VERSION ""

NS_ :

BS_:

BU_: CVC_B BCM_FL BCM_FR DUMMY_ECU DKCU BCM_R

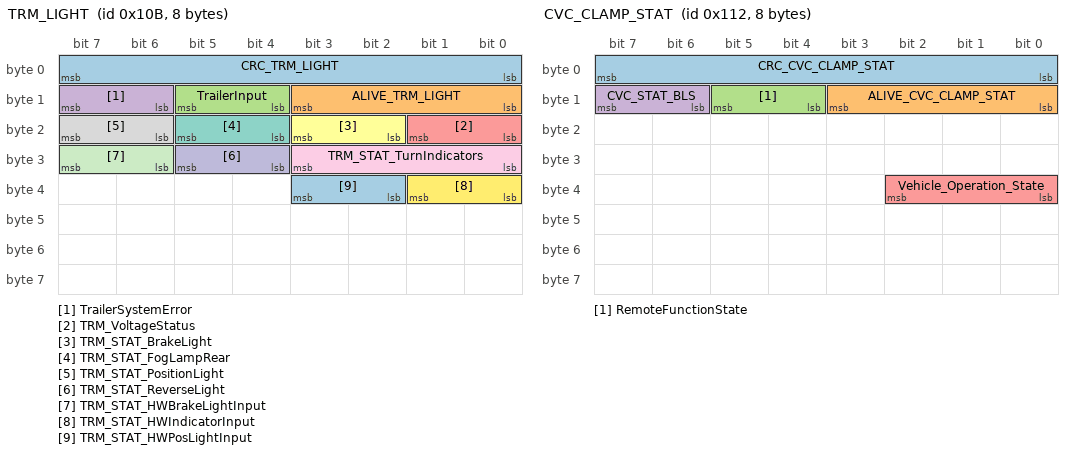
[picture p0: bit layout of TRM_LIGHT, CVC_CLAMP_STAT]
BO_ 267 TRM_LIGHT: 8 CVC_B
 SG_ CRC_TRM_LIGHT : 7|8@0+ (1,0) [0|255] ""  BCM_FL,BCM_FR,BCM_R
 SG_ ALIVE_TRM_LIGHT : 11|4@0+ (1,0) [0|15] ""  BCM_FL,BCM_FR,BCM_R
 SG_ TrailerInput : 13|2@0+ (1,0) [0|3] ""  BCM_FL,BCM_FR,BCM_R
 SG_ TrailerSystemError : 15|2@0+ (1,0) [0|3] ""  BCM_FL,BCM_FR,BCM_R
 SG_ TRM_VoltageStatus : 17|2@0+ (1,0) [0|3] ""  BCM_FL,BCM_FR,BCM_R
 SG_ TRM_STAT_BrakeLight : 19|2@0+ (1,0) [0|3] ""  BCM_FL,BCM_FR,BCM_R
 SG_ TRM_STAT_FogLampRear : 21|2@0+ (1,0) [0|3] ""  BCM_FL,BCM_FR,BCM_R
 SG_ TRM_STAT_PositionLight : 23|2@0+ (1,0) [0|3] ""  BCM_FL,BCM_FR,BCM_R
 SG_ TRM_STAT_TurnIndicators : 27|4@0+ (1,0) [0|15] ""  BCM_FL,BCM_FR,BCM_R
 SG_ TRM_STAT_ReverseLight : 29|2@0+ (1,0) [0|3] ""  BCM_FL,BCM_FR,BCM_R
 SG_ TRM_STAT_HWBrakeLightInput : 31|2@0+ (1,0) [0|3] ""  BCM_FL,BCM_FR,BCM_R
 SG_ TRM_STAT_HWIndicatorInput : 33|2@0+ (1,0) [0|3] ""  BCM_FL,BCM_FR,BCM_R
 SG_ TRM_STAT_HWPosLightInput : 35|2@0+ (1,0) [0|3] ""  BCM_FL,BCM_FR,BCM_R

BO_ 274 CVC_CLAMP_STAT: 8 CVC_B
 SG_ CRC_CVC_CLAMP_STAT : 7|8@0+ (1,0) [0|255] ""  BCM_FL,BCM_FR,DKCU,BCM_R
 SG_ ALIVE_CVC_CLAMP_STAT : 11|4@0+ (1,0) [0|15] ""  BCM_FL,BCM_FR,DKCU,BCM_R
 SG_ RemoteFunctionState : 13|2@0+ (1,0) [0|3] ""  BCM_FL,BCM_FR,DKCU,BCM_R
 SG_ CVC_STAT_BLS : 15|2@0+ (1,0) [0|3] ""  BCM_FL,BCM_FR,DKCU,BCM_R
 SG_ Vehicle_Operation_State : 34|3@0+ (1,0) [0|7] ""  BCM_FL,BCM_FR,DKCU,BCM_R

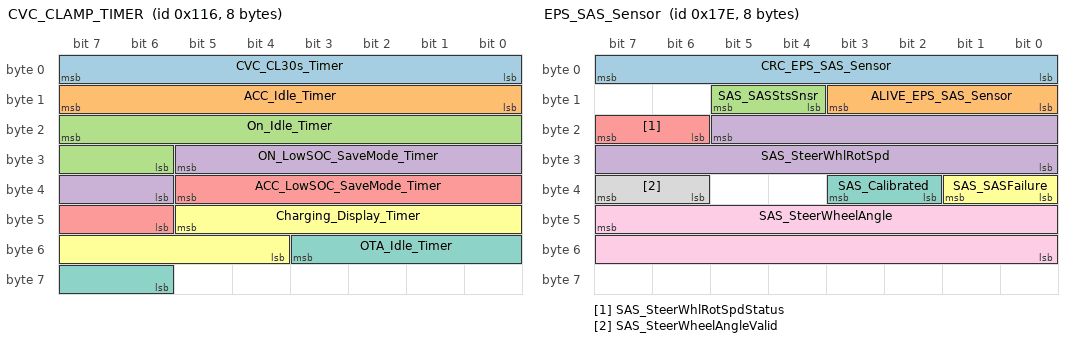
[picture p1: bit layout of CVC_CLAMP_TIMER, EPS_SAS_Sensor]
BO_ 278 CVC_CLAMP_TIMER: 8 CVC_B
 SG_ CVC_CL30s_Timer : 7|8@0+ (1,0) [0|255] "s"  BCM_FL,BCM_FR,BCM_R
 SG_ ACC_Idle_Timer : 15|8@0+ (1,0) [0|255] "s"  BCM_FL,BCM_FR,BCM_R
 SG_ On_Idle_Timer : 23|10@0+ (1,0) [0|1023] "s"  BCM_FL,BCM_FR,BCM_R
 SG_ ON_LowSOC_SaveMode_Timer : 29|8@0+ (1,0) [0|255] "s"  BCM_FL,BCM_FR,BCM_R
 SG_ ACC_LowSOC_SaveMode_Timer : 37|8@0+ (1,0) [0|255] "s"  BCM_FL,BCM_FR,BCM_R
 SG_ Charging_Display_Timer : 45|10@0+ (1,0) [0|1023] "s"  BCM_FL,BCM_FR,BCM_R
 SG_ OTA_Idle_Timer : 51|6@0+ (1,0) [0|63] "minute"  BCM_FL,BCM_FR,BCM_R

BO_ 284 FOTAClampCtrl: 8 CVC_B
 SG_ TBOX_FOTA_STAT_TerminalReq : 7|3@0+ (1,0) [0|7] ""  BCM_FL,BCM_FR,BCM_R

BO_ 307 SRR_RR_BSD_RCTA_DOW: 32 CVC_B
 SG_ CRC_SRR_RR_BSD_RCTA_DOW : 7|8@0+ (1,0) [0|255] ""  BCM_FL,BCM_FR,BCM_R
 SG_ ALIVE_SRR_RR_BSD_RCTA_DOW : 11|4@0+ (1,0) [0|15] ""  BCM_FL,BCM_FR,BCM_R
 SG_ SRR_RR_BSD_check : 19|2@0+ (1,0) [0|3] ""  BCM_FL,BCM_FR,BCM_R
 SG_ SRR_RR_BSD_state : 22|3@0+ (1,0) [0|7] ""  BCM_FL,BCM_FR,BCM_R
 SG_ SRR_RR_BSD_AudChime_Feed : 23|1@0+ (1,0) [0|1] ""  BCM_FL,BCM_FR,BCM_R
 SG_ SRR_RR_BSD_IndLeft : 25|2@0+ (1,0) [0|3] ""  BCM_FL,BCM_FR,BCM_R
 SG_ SRR_RR_BSD_IndRight : 27|2@0+ (1,0) [0|3] ""  BCM_FL,BCM_FR,BCM_R
 SG_ SRR_RR_BSD_SndWarn : 29|2@0+ (1,0) [0|3] ""  BCM_FL,BCM_FR,BCM_R
 SG_ SRR_RR_BSD_Mode_Feed : 30|1@0+ (1,0) [0|1] ""  BCM_FL,BCM_FR,BCM_R
 SG_ SRR_RR_BSD_sens_Feed : 33|2@0+ (1,0) [0|3] ""  BCM_FL,BCM_FR,BCM_R
 SG_ SRR_RR_RCTA_IndRight : 39|2@0+ (1,0) [0|3] ""  BCM_FL,BCM_FR,BCM_R
 SG_ SRR_RR_RCTA_IndLeft : 17|2@0+ (1,0) [0|3] ""  BCM_FL,BCM_FR,BCM_R
 SG_ SRR_RR_RCTA_sens_Feed : 37|2@0+ (1,0) [0|3] ""  BCM_FL,BCM_FR,BCM_R
 SG_ SRR_RR_RCTA_state : 63|3@0+ (1,0) [0|7] ""  BCM_FL,BCM_FR,BCM_R
 SG_ SRR_RR_RCTA_SndWarn : 35|2@0+ (1,0) [0|3] ""  BCM_FL,BCM_FR,BCM_R
 SG_ SRR_RR_RCTA_Mode_Feed : 13|2@0+ (1,0) [0|3] ""  BCM_FL,BCM_FR,BCM_R
 SG_ SRR_RR_RCTA_check : 47|2@0+ (1,0) [0|3] ""  BCM_FL,BCM_FR,BCM_R
 SG_ SRR_RR_DOW_SndWarn : 50|2@0+ (1,0) [0|3] ""  BCM_FL,BCM_FR,BCM_R
 SG_ SRR_RR_DOW_WarnRight : 52|2@0+ (1,0) [0|3] ""  BCM_FL,BCM_FR,BCM_R
 SG_ SRR_RR_DOW_WarnLeft : 54|2@0+ (1,0) [0|3] ""  BCM_FL,BCM_FR,BCM_R
 SG_ SRR_RR_DOW_check : 40|2@0+ (1,0) [0|3] ""  BCM_FL,BCM_FR,BCM_R
 SG_ SRR_RR_DOW_state : 45|3@0+ (1,0) [0|7] ""  BCM_FL,BCM_FR,BCM_R
 SG_ SRR_RR_DOW_Mode_Feed : 42|2@0+ (1,0) [0|3] ""  BCM_FL,BCM_FR,BCM_R
 SG_ SRR_RR_Right_block : 15|2@0+ (1,0) [0|3] ""  BCM_FL,BCM_FR,BCM_R
 SG_ SRR_RR_Left_block : 60|2@0+ (1,0) [0|3] ""  BCM_FL,BCM_FR,BCM_R
 SG_ Obj_ID_RL : 71|8@0+ (1,0) [0|255] ""  BCM_FL,BCM_FR,BCM_R
 SG_ Obj_Class_RL : 79|3@0+ (1,0) [0|7] ""  BCM_FL,BCM_FR,BCM_R
 SG_ Obj_OrientationAngle_RL : 76|10@0+ (0.4,-180) [-180|229.2] "deg"  BCM_FL,BCM_FR,BCM_R
 SG_ Obj_DistLong_RL : 82|13@0+ (0.2,-500) [-500|1138.2] "m"  BCM_FL,BCM_FR,BCM_R
 SG_ Obj_DislLat_RL : 101|11@0+ (0.2,-204.6) [-204.6|204.8] "m"  BCM_FL,BCM_FR,BCM_R
 SG_ Obj_VrelLong_RL : 106|10@0+ (0.25,-128) [-128|127.75] "m/s"  BCM_FL,BCM_FR,BCM_R
 SG_ Obj_VrelLat_RL : 112|9@0+ (0.25,-64) [-64|63.75] "m/s"  BCM_FL,BCM_FR,BCM_R
 SG_ Obj_ID_RR : 135|8@0+ (1,0) [0|255] ""  BCM_FL,BCM_FR,BCM_R
 SG_ Obj_Class_RR : 143|3@0+ (1,0) [0|7] ""  BCM_FL,BCM_FR,BCM_R
 SG_ Obj_OrientationAngle_RR : 140|10@0+ (0.4,-180) [-180|229.2] "deg"  BCM_FL,BCM_FR,BCM_R
 SG_ Obj_DistLong_RR : 146|13@0+ (0.2,-500) [-500|1138.2] "m"  BCM_FL,BCM_FR,BCM_R
 SG_ Obj_DislLat_RR : 165|11@0+ (0.2,-204.6) [-204.6|204.8] "m"  BCM_FL,BCM_FR,BCM_R
 SG_ Obj_VrelLong_RR : 170|10@0+ (0.25,-128) [-128|127.75] "m/s"  BCM_FL,BCM_FR,BCM_R
 SG_ Obj_VrelLat_RR : 176|9@0+ (0.25,-64) [-64|63.75] "m/s"  BCM_FL,BCM_FR,BCM_R
 SG_ SRR_RR_RCTB_Mode_Feed : 193|2@0+ (1,0) [0|3] ""  BCM_FL,BCM_FR,BCM_R
 SG_ SRR_RR_RCTB_State : 58|3@0+ (1,0) [0|7] ""  BCM_FL,BCM_FR,BCM_R
 SG_ SRR_RR_RCTB_Check : 197|2@0+ (1,0) [0|3] ""  BCM_FL,BCM_FR,BCM_R
 SG_ SRR_RR_RCTB_Braking_Flag : 199|2@0+ (1,0) [0|3] ""  BCM_FL,BCM_FR,BCM_R
 SG_ SRR_RR_RCTB_Braking_Deceleration : 215|8@0+ (0.1,-6.5) [-6.5|6.5] "m/s2"  BCM_FL,BCM_FR,BCM_R
 SG_ SRR_RR_CollisionObjID : 223|8@0+ (1,0) [0|255] ""  BCM_FL,BCM_FR,BCM_R

BO_ 323 CVC_RearHVAC_Control: 20 CVC_B
 SG_ Ionizer_Set : 3|2@0+ (1,0) [0|3] ""  BCM_R
 SG_ Rear_AirRecirculationFlap_Set : 15|8@0+ (1,0) [0|100] "%"  BCM_R
 SG_ FrontPass_AirModeFlap_Set : 23|8@0+ (1,0) [0|100] "%"  BCM_R
 SG_ FrontByPass_AirModeFlap_Set : 31|8@0+ (1,0) [0|100] "%"  BCM_R
 SG_ RearFoot_AirModeFlap_Set : 39|8@0+ (1,0) [0|100] "%"  BCM_R
 SG_ Rear_AirModeFlap_Set : 47|8@0+ (1,0) [0|100] "%"  BCM_R
 SG_ RL_TempFlap_Set : 55|8@0+ (1,0) [0|100] "%"  BCM_R
 SG_ RR_TempFlap_Set : 63|8@0+ (1,0) [0|100] "%"  BCM_R
 SG_ Rear_TempFlap_Set : 71|8@0+ (1,0) [0|100] "%"  BCM_R
 SG_ RearSOV_Req : 1|2@0+ (1,0) [0|3] ""  BCM_R
 SG_ RearBlowerRelay_Set : 5|2@0+ (1,0) [0|3] ""  BCM_R

BO_ 382 EPS_SAS_Sensor: 8 CVC_B
 SG_ CRC_EPS_SAS_Sensor : 7|8@0+ (1,0) [0|255] ""  DUMMY_ECU
 SG_ ALIVE_EPS_SAS_Sensor : 11|4@0+ (1,0) [0|15] ""  DUMMY_ECU
 SG_ SAS_SASStsSnsr : 13|2@0+ (1,0) [0|1] ""  DUMMY_ECU
 SG_ SAS_SteerWhlRotSpd : 21|14@0+ (0.125,-1024) [-1024|1023.88] "degree/s"  DUMMY_ECU
 SG_ SAS_SteerWhlRotSpdStatus : 23|2@0+ (1,0) [0|1] ""  DUMMY_ECU
 SG_ SAS_SASFailure : 33|2@0+ (1,0) [0|1] ""  DUMMY_ECU
 SG_ SAS_Calibrated : 35|2@0+ (1,0) [0|1] ""  DUMMY_ECU
 SG_ SAS_SteerWheelAngleValid : 39|2@0+ (1,0) [0|1] ""  DUMMY_ECU
 SG_ SAS_SteerWheelAngle : 47|16@0+ (0.0238,-780) [-780|779.7] "deg"  DUMMY_ECU

BO_ 519 BCM_SunroofSts: 8 BCM_FR
 SG_ SR_Undervoltage_Fault_Sts : 0|1@0+ (1,0) [0|1] ""  CVC_B
 SG_ SR_Overvoltage_Fault_Sts : 1|1@0+ (1,0) [0|1] ""  CVC_B
 SG_ SR_SLEEP_RQ : 2|1@0+ (1,0) [0|1] ""  CVC_B
 SG_ SR_Position : 5|3@0+ (1,0) [0|7] ""  CVC_B
 SG_ SR_Motor_Running_Sts : 7|2@0+ (1,0) [0|3] ""  CVC_B
 SG_ SR_MotorReverse_Fault_Sts : 8|1@0+ (1,0) [0|1] ""  CVC_B
 SG_ SR_Hall_Fault_Sts : 9|1@0+ (1,0) [0|1] ""  CVC_B
 SG_ SR_Normalisation_Sts : 10|1@0+ (1,0) [0|1] ""  CVC_B
 SG_ SR_Relay_Fault : 11|1@0+ (1,0) [0|1] ""  CVC_B
 SG_ SR_Commu_Fault_Sts : 12|1@0+ (1,0) [0|1] ""  CVC_B
 SG_ SR_Initialisation_Status : 13|1@0+ (1,0) [0|1] ""  CVC_B
 SG_ SR_Ctrl_Result : 15|2@0+ (1,0) [0|3] ""  CVC_B
 SG_ SR_ThermalProtection_Fault_Sts : 16|1@0+ (1,0) [0|1] ""  CVC_B
 SG_ SR_Posit_Percentage : 23|7@0+ (1,0) [0|100] "%"  CVC_B
 SG_ SR_Operation_Stat : 27|4@0+ (1,0) [0|8] ""  CVC_B
 SG_ SR_Error_RSP : 28|1@0+ (1,0) [0|1] ""  CVC_B
 SG_ BCM_AutoSunroof_Sts : 30|2@0+ (1,0) [0|3] ""  CVC_B

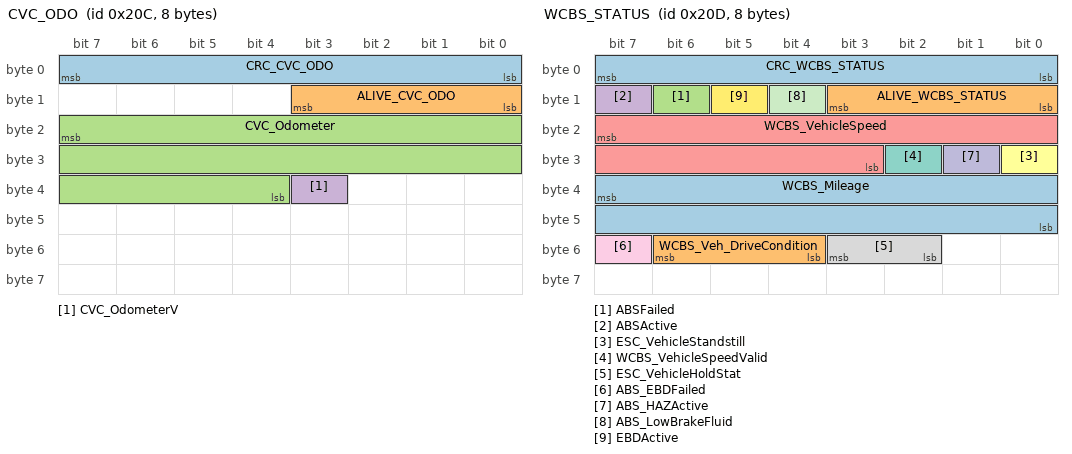
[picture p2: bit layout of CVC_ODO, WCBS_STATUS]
BO_ 524 CVC_ODO: 8 CVC_B
 SG_ CRC_CVC_ODO : 7|8@0+ (1,0) [0|255] ""  BCM_FL,BCM_FR
 SG_ ALIVE_CVC_ODO : 11|4@0+ (1,0) [0|15] ""  BCM_FL,BCM_FR
 SG_ CVC_Odometer : 23|20@0+ (1,0) [0|999999] "km"  BCM_FL,BCM_FR
 SG_ CVC_OdometerV : 35|1@0+ (1,0) [0|1] ""  BCM_FL,BCM_FR

BO_ 525 WCBS_STATUS: 8 CVC_B
 SG_ CRC_WCBS_STATUS : 7|8@0+ (1,0) [0|255] ""  BCM_FL,BCM_FR,DKCU,BCM_R
 SG_ ALIVE_WCBS_STATUS : 11|4@0+ (1,0) [0|15] ""  BCM_FL,BCM_FR,DKCU,BCM_R
 SG_ ABSFailed : 14|1@0+ (1,0) [0|1] ""  BCM_FL,BCM_FR,DKCU,BCM_R
 SG_ ABSActive : 15|1@0+ (1,0) [0|1] ""  BCM_FL,BCM_FR,DKCU,BCM_R
 SG_ WCBS_VehicleSpeed : 23|13@0+ (0.05625,0) [0|300] "km/h"  BCM_FL,BCM_FR,DKCU,BCM_R
 SG_ ESC_VehicleStandstill : 24|1@0+ (1,0) [0|1] ""  BCM_FL,BCM_FR,DKCU,BCM_R
 SG_ WCBS_VehicleSpeedValid : 26|1@0+ (1,0) [0|1] ""  BCM_FL,BCM_FR,DKCU,BCM_R
 SG_ ESC_VehicleHoldStat : 51|2@0+ (1,0) [0|3] ""  BCM_FL,BCM_FR,DKCU,BCM_R
 SG_ ABS_EBDFailed : 55|1@0+ (1,0) [0|1] ""  BCM_FL,BCM_FR,DKCU,BCM_R
 SG_ ABS_HAZActive : 25|1@0+ (1,0) [0|1] ""  BCM_FL,BCM_FR,DKCU,BCM_R
 SG_ ABS_LowBrakeFluid : 12|1@0+ (1,0) [0|1] ""  BCM_FL,BCM_FR,DKCU,BCM_R
 SG_ EBDActive : 13|1@0+ (1,0) [0|1] ""  BCM_FL,BCM_FR,DKCU,BCM_R
 SG_ WCBS_Mileage : 39|16@0+ (1,0) [0|65535] "cm"  BCM_FL,BCM_FR,DKCU,BCM_R
 SG_ WCBS_Veh_DriveCondition : 54|3@0+ (1,0) [0|7] ""  BCM_FL,BCM_FR,DKCU,BCM_R

BO_ 533 BMS_Sts: 16 CVC_B
 SG_ CRC_BMS_Sts : 7|8@0+ (1,0) [0|255] ""  BCM_FL,BCM_FR,BCM_R
 SG_ ALIVE_BMS_Sts : 11|4@0+ (1,0) [0|15] ""  BCM_FL,BCM_FR,BCM_R
 SG_ BMS_BatBalance_ERR : 12|1@0+ (1,0) [0|1] ""  BCM_FL,BCM_FR,BCM_R
 SG_ BMS_Balance_STS : 13|1@0+ (1,0) [0|1] ""  BCM_FL,BCM_FR,BCM_R
 SG_ BMS_IGN_Sts : 14|1@0+ (1,0) [0|1] ""  BCM_FL,BCM_FR,BCM_R
 SG_ BMS_HWCrash_Sts : 15|1@0+ (1,0) [0|1] ""  BCM_FL,BCM_FR,BCM_R
 SG_ BMS_HVIL_STS : 17|2@0+ (1,0) [0|3] ""  BCM_FL,BCM_FR,BCM_R
 SG_ BMS_HVOnOff_STS : 19|2@0+ (1,0) [0|3] ""  BCM_FL,BCM_FR,BCM_R
 SG_ BMS_ERR_LEV : 23|4@0+ (1,0) [0|7] ""  BCM_FL,BCM_FR,BCM_R
 SG_ BMS_SocActual_EST : 25|10@0+ (0.1,0) [0|100] "%"  BCM_FL,BCM_FR,BCM_R
 SG_ BMS_Sys_STS : 29|4@0+ (1,0) [0|15] ""  BCM_FL,BCM_FR,BCM_R
 SG_ BMS_ISU_Status : 31|2@0+ (1,0) [0|3] ""  BCM_FL,BCM_FR,BCM_R
 SG_ BMS_SOH : 47|8@0+ (0.5,0) [0|100] "%"  BCM_FL,BCM_FR,BCM_R
 SG_ BMS_SOE : 55|8@0+ (0.5,0) [0|100] "%"  BCM_FL,BCM_FR,BCM_R
 SG_ BMS_HV_Sts : 63|8@0+ (1,0) [0|255] ""  BCM_FL,BCM_FR,BCM_R
 SG_ BMS_Display_SOC : 71|10@0+ (0.1,0) [0|100] "%"  BCM_FL,BCM_FR,BCM_R
 SG_ BMS_SOCE : 87|14@0+ (0.01,0) [0|100] "%"  BCM_FL,BCM_FR,BCM_R

BO_ 536 CVC_ExteriorLight_Req: 12 CVC_B
 SG_ CRC_CVC_ExteriorLight_Req : 7|8@0+ (1,0) [0|255] ""  BCM_FL,BCM_FR,BCM_R
 SG_ ALIVE_CVC_ExteriorLight_Req : 11|4@0+ (1,0) [0|15] ""  BCM_FL,BCM_FR,BCM_R
 SG_ CVC_PosLight_RR_Req : 31|2@0+ (1,0) [0|3] ""  BCM_FL,BCM_FR,BCM_R
 SG_ CVC_RearFogLamp_RL_Req : 13|2@0+ (1,0) [0|3] ""  BCM_FL,BCM_FR,BCM_R
 SG_ CVC_RearFogLamp_RR_Req : 15|2@0+ (1,0) [0|3] ""  BCM_FL,BCM_FR,BCM_R
 SG_ CVC_DaytimeRunningLight_FL_Req : 17|2@0+ (1,0) [0|3] ""  BCM_FL,BCM_FR,BCM_R
 SG_ CVC_DaytimeRunningLight_FR_Req : 19|2@0+ (1,0) [0|3] ""  BCM_FL,BCM_FR,BCM_R
 SG_ CVC_TurnIndicator_FL_Req : 21|2@0+ (1,0) [0|3] ""  BCM_FL,BCM_FR,BCM_R
 SG_ CVC_TurnIndicator_RL_Req : 23|2@0+ (1,0) [0|3] ""  BCM_FL,BCM_FR,BCM_R
 SG_ CVC_TurnIndicator_FR_Req : 25|2@0+ (1,0) [0|3] ""  BCM_FL,BCM_FR,BCM_R
 SG_ CVC_TurnIndicator_RR_Req : 27|2@0+ (1,0) [0|3] ""  BCM_FL,BCM_FR,BCM_R
 SG_ CVC_RLS_AutoLampRequest : 29|2@0+ (1,0) [0|3] ""  BCM_FL,BCM_FR,BCM_R
 SG_ CVC_ReverseLamp_RL_Req : 33|2@0+ (1,0) [0|3] ""  BCM_FL,BCM_FR,BCM_R
 SG_ CVC_ReverseLamp_RR_Req : 35|2@0+ (1,0) [0|3] ""  BCM_FL,BCM_FR,BCM_R
 SG_ CVC_BrakeLight_RL_Req : 37|2@0+ (1,0) [0|3] ""  BCM_FL,BCM_FR,BCM_R
 SG_ CVC_BrakeLight_RR_Req : 39|2@0+ (1,0) [0|3] ""  BCM_FL,BCM_FR,BCM_R
 SG_ CVC_BrakeLight_Center_Req : 41|2@0+ (1,0) [0|3] ""  BCM_FL,BCM_FR,BCM_R
 SG_ CVC_LicensePlateLamp_RE_Req : 43|2@0+ (1,0) [0|3] ""  BCM_FL,BCM_FR,BCM_R
 SG_ CVC_HighBeam_FL_Req : 45|2@0+ (1,0) [0|3] ""  BCM_FL,BCM_FR,BCM_R
 SG_ CVC_HighBeam_FR_Req : 47|2@0+ (1,0) [0|3] ""  BCM_FL,BCM_FR,BCM_R
 SG_ CVC_LowBeam_FL_Req : 49|2@0+ (1,0) [0|3] ""  BCM_FL,BCM_FR,BCM_R
 SG_ CVC_LowBeam_FR_Req : 51|2@0+ (1,0) [0|3] ""  BCM_FL,BCM_FR,BCM_R
 SG_ CVC_PosLight_RL_Req : 53|2@0+ (1,0) [0|3] ""  BCM_FL,BCM_FR,BCM_R
 SG_ CVC_MirrorLED_FL_Req : 55|2@0+ (1,0) [0|3] ""  BCM_FL,BCM_R
 SG_ CVC_MirrorLED_FR_Req : 57|2@0+ (1,0) [0|3] ""  BCM_FR,BCM_R
 SG_ CVC_WelcomeFarewellLight_Req : 60|3@0+ (1,0) [0|7] ""  BCM_FL,BCM_FR,BCM_R
 SG_ CVC_SignatureLight_RE_Req : 63|3@0+ (1,0) [0|7] ""  BCM_FL,BCM_FR,BCM_R
 SG_ CVC_PosLight_FR_Req : 65|2@0+ (1,0) [0|3] ""  BCM_FL,BCM_FR,BCM_R
 SG_ CVC_PosLight_FL_Req : 67|2@0+ (1,0) [0|3] ""  BCM_FL,BCM_FR,BCM_R
 SG_ CVC_FrontFogLamp_FR_Req : 69|2@0+ (1,0) [0|3] ""  BCM_FL,BCM_FR,BCM_R
 SG_ CVC_FrontFogLamp_FL_Req : 71|2@0+ (1,0) [0|3] ""  BCM_FL,BCM_FR,BCM_R
 SG_ CVC_IndicatorMode_Req : 75|4@0+ (1,0) [0|15] ""  BCM_FL,BCM_FR,BCM_R
 SG_ CVC_ParkLight_RL_Req : 77|2@0+ (1,0) [0|3] ""  BCM_R
 SG_ CVC_ParkLight_RR_Req : 79|2@0+ (1,0) [0|3] ""  BCM_R
 SG_ CVC_SideMarkerLight_Req : 83|2@0+ (1,0) [0|3] ""  BCM_FL,BCM_FR,BCM_R
 SG_ CVC_ParkLight_RM_Req : 85|2@0+ (1,0) [0|3] ""  BCM_R
 SG_ CVC_PosLight_RM_Req : 87|2@0+ (1,0) [0|3] ""  BCM_R

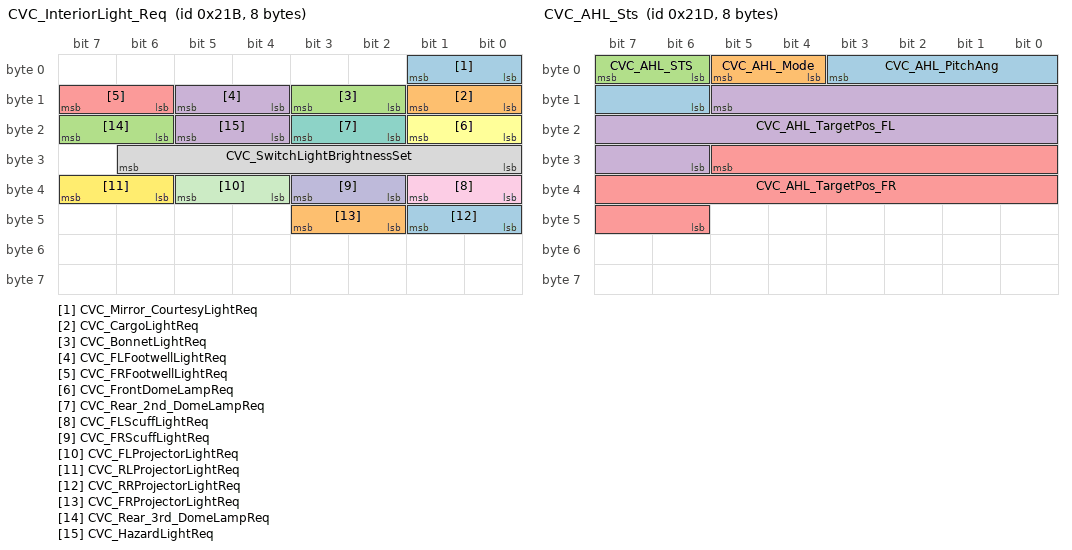
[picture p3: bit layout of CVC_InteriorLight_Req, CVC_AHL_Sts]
BO_ 539 CVC_InteriorLight_Req: 8 CVC_B
 SG_ CVC_Mirror_CourtesyLightReq : 1|2@0+ (1,0) [0|3] ""  BCM_FL,BCM_FR,BCM_R
 SG_ CVC_CargoLightReq : 9|2@0+ (1,0) [0|3] ""  BCM_FL,BCM_FR,BCM_R
 SG_ CVC_BonnetLightReq : 11|2@0+ (1,0) [0|3] ""  BCM_FL,BCM_FR,BCM_R
 SG_ CVC_FLFootwellLightReq : 13|2@0+ (1,0) [0|3] ""  BCM_FL,BCM_FR,BCM_R
 SG_ CVC_FRFootwellLightReq : 15|2@0+ (1,0) [0|3] ""  BCM_FL,BCM_FR,BCM_R
 SG_ CVC_FrontDomeLampReq : 17|2@0+ (1,0) [0|3] ""  BCM_FL,BCM_FR,BCM_R
 SG_ CVC_Rear_2nd_DomeLampReq : 19|2@0+ (1,0) [0|3] ""  BCM_FL,BCM_FR,BCM_R
 SG_ CVC_SwitchLightBrightnessSet : 30|7@0+ (1,0) [0|100] "%"  BCM_FL,BCM_FR,BCM_R
 SG_ CVC_FLScuffLightReq : 33|2@0+ (1,0) [0|3] ""  BCM_FL,BCM_FR,BCM_R
 SG_ CVC_FRScuffLightReq : 35|2@0+ (1,0) [0|3] ""  BCM_FL,BCM_FR,BCM_R
 SG_ CVC_FLProjectorLightReq : 37|2@0+ (1,0) [0|3] ""  BCM_FL,BCM_FR,BCM_R
 SG_ CVC_RLProjectorLightReq : 39|2@0+ (1,0) [0|3] ""  BCM_FL,BCM_FR,BCM_R
 SG_ CVC_RRProjectorLightReq : 41|2@0+ (1,0) [0|3] ""  BCM_FL,BCM_FR,BCM_R
 SG_ CVC_FRProjectorLightReq : 43|2@0+ (1,0) [0|3] ""  BCM_FL,BCM_FR,BCM_R
 SG_ CVC_Rear_3rd_DomeLampReq : 23|2@0+ (1,0) [0|3] ""  BCM_FL,BCM_FR,BCM_R
 SG_ CVC_HazardLightReq : 21|2@0+ (1,0) [0|3] ""  BCM_FL,BCM_FR,BCM_R

BO_ 541 CVC_AHL_Sts: 8 CVC_B
 SG_ CVC_AHL_PitchAng : 3|6@0+ (0.1,-2) [-2|2] "Degree"  BCM_FL,BCM_FR
 SG_ CVC_AHL_Mode : 5|2@0+ (1,0) [0|3] ""  BCM_FL,BCM_FR
 SG_ CVC_AHL_STS : 7|2@0+ (1,0) [0|3] ""  BCM_FL,BCM_FR
 SG_ CVC_AHL_TargetPos_FL : 13|16@0+ (1,0) [0|65535] ""  BCM_FL,BCM_FR
 SG_ CVC_AHL_TargetPos_FR : 29|16@0+ (1,0) [0|65535] ""  BCM_FL,BCM_FR

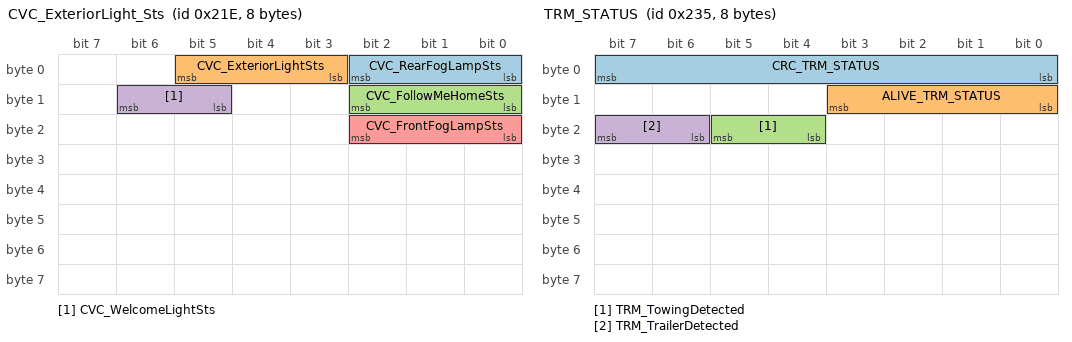
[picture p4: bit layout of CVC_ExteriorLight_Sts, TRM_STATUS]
BO_ 542 CVC_ExteriorLight_Sts: 8 CVC_B
 SG_ CVC_RearFogLampSts : 2|3@0+ (1,0) [0|4] ""  BCM_FL,BCM_FR,BCM_R
 SG_ CVC_ExteriorLightSts : 5|3@0+ (1,0) [0|4] ""  BCM_FL,BCM_FR,BCM_R
 SG_ CVC_FollowMeHomeSts : 10|3@0+ (1,0) [0|5] ""  BCM_FL,BCM_FR,BCM_R
 SG_ CVC_WelcomeLightSts : 14|2@0+ (1,0) [0|3] ""  BCM_FL,BCM_FR,BCM_R
 SG_ CVC_FrontFogLampSts : 18|3@0+ (1,0) [0|4] ""  BCM_FL,BCM_FR,BCM_R

BO_ 565 TRM_STATUS: 8 CVC_B
 SG_ CRC_TRM_STATUS : 7|8@0+ (1,0) [0|255] ""  DUMMY_ECU
 SG_ ALIVE_TRM_STATUS : 11|4@0+ (1,0) [0|15] ""  DUMMY_ECU
 SG_ TRM_TowingDetected : 21|2@0+ (1,0) [0|3] ""  DUMMY_ECU
 SG_ TRM_TrailerDetected : 23|2@0+ (1,0) [0|3] ""  DUMMY_ECU

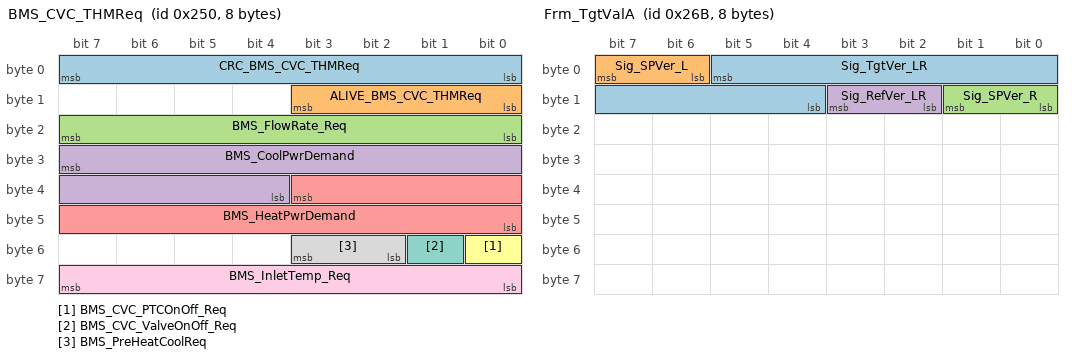
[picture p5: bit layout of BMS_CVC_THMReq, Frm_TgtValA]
BO_ 592 BMS_CVC_THMReq: 8 CVC_B
 SG_ CRC_BMS_CVC_THMReq : 7|8@0+ (1,0) [0|255] ""  BCM_FL,BCM_FR,BCM_R
 SG_ ALIVE_BMS_CVC_THMReq : 11|4@0+ (1,0) [0|15] ""  BCM_FL,BCM_FR,BCM_R
 SG_ BMS_FlowRate_Req : 23|8@0+ (1,0) [0|50] "l/min"  BCM_FL,BCM_FR,BCM_R
 SG_ BMS_CoolPwrDemand : 31|12@0+ (0.1,0) [0|10] "kW"  BCM_FL,BCM_FR,BCM_R
 SG_ BMS_HeatPwrDemand : 35|12@0+ (0.1,0) [0|10] "kW"  BCM_FL,BCM_FR,BCM_R
 SG_ BMS_CVC_PTCOnOff_Req : 48|1@0+ (1,0) [0|1] ""  BCM_FL,BCM_FR,BCM_R
 SG_ BMS_CVC_ValveOnOff_Req : 49|1@0+ (1,0) [0|1] ""  BCM_FL,BCM_FR,BCM_R
 SG_ BMS_PreHeatCoolReq : 51|2@0+ (1,0) [0|3] ""  BCM_FL,BCM_FR,BCM_R
 SG_ BMS_InletTemp_Req : 63|8@0+ (1,-40) [-40|215] "Degree C"  BCM_FL,BCM_FR,BCM_R

BO_ 619 Frm_TgtValA: 8 CVC_B
 SG_ Sig_TgtVer_LR : 5|10@0+ (1,0) [0|1000] "deg"  BCM_FL,BCM_FR,BCM_R
 SG_ Sig_SPVer_L : 7|2@0+ (1,0) [0|3] ""  BCM_FL,BCM_FR,BCM_R
 SG_ Sig_SPVer_R : 9|2@0+ (1,0) [0|3] "deg"  BCM_FL,BCM_FR,BCM_R
 SG_ Sig_RefVer_LR : 11|2@0+ (1,0) [0|3] ""  BCM_FL,BCM_FR,BCM_R

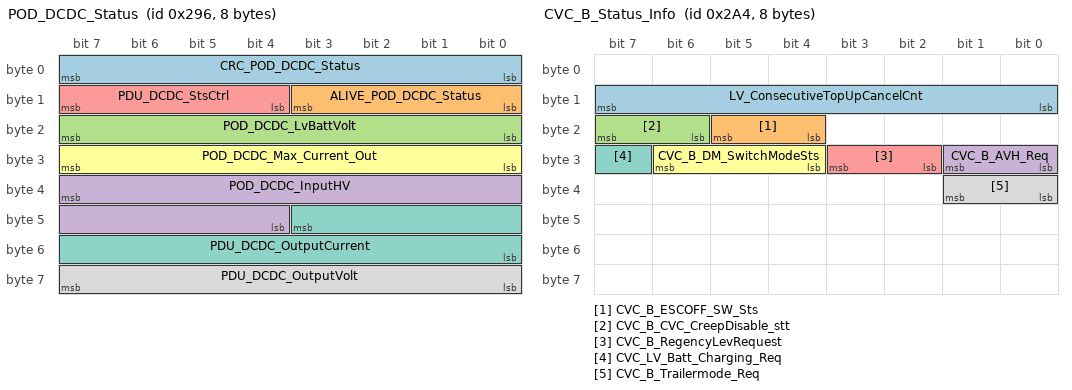
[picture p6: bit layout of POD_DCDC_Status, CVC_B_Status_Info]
BO_ 662 POD_DCDC_Status: 8 CVC_B
 SG_ CRC_POD_DCDC_Status : 7|8@0+ (1,0) [0|255] ""  BCM_FL,BCM_FR,BCM_R
 SG_ ALIVE_POD_DCDC_Status : 11|4@0+ (1,0) [0|15] ""  BCM_FL,BCM_FR,BCM_R
 SG_ POD_DCDC_LvBattVolt : 23|8@0+ (0.1,0) [0|15] ""  BCM_FL,BCM_FR,BCM_R
 SG_ POD_DCDC_InputHV : 39|12@0+ (0.5,0) [0|1000] "V"  BCM_FL,BCM_FR,BCM_R
 SG_ PDU_DCDC_StsCtrl : 15|4@0+ (1,0) [0|15] ""  BCM_FL,BCM_FR,BCM_R
 SG_ POD_DCDC_Max_Current_Out : 31|8@0+ (1,0) [0|250] ""  BCM_FL,BCM_FR,BCM_R
 SG_ PDU_DCDC_OutputCurrent : 43|12@0+ (0.1,-100) [-100|300] "A"  BCM_FL,BCM_FR,BCM_R
 SG_ PDU_DCDC_OutputVolt : 63|8@0+ (0.125,0) [0|31.875] "V"  BCM_FL,BCM_FR,BCM_R

BO_ 676 CVC_B_Status_Info: 8 CVC_B
 SG_ LV_ConsecutiveTopUpCancelCnt : 15|8@0+ (1,0) [0|255] ""  BCM_FL
 SG_ CVC_B_ESCOFF_SW_Sts : 21|2@0+ (1,0) [0|3] ""  BCM_FL,BCM_FR,BCM_R
 SG_ CVC_B_CVC_CreepDisable_stt : 23|2@0+ (1,0) [0|3] ""  BCM_FL,BCM_FR,BCM_R
 SG_ CVC_B_AVH_Req : 25|2@0+ (1,0) [0|3] ""  BCM_FL,BCM_FR,BCM_R
 SG_ CVC_B_RegencyLevRequest : 27|2@0+ (1,0) [0|3] ""  BCM_FL,BCM_FR,BCM_R
 SG_ CVC_B_DM_SwitchModeSts : 30|3@0+ (1,0) [0|7] ""  BCM_FL,BCM_FR,BCM_R
 SG_ CVC_LV_Batt_Charging_Req : 31|1@0+ (1,0) [0|1] ""  BCM_FL
 SG_ CVC_B_Trailermode_Req : 33|2@0+ (1,0) [0|3] ""  BCM_FL,BCM_FR,BCM_R

BO_ 746 CVC_Temp: 16 CVC_B
 SG_ InteriorTemperature : 7|12@0+ (0.1,-80) [-80|329] "C"  BCM_FL,BCM_FR,DKCU,BCM_R
 SG_ CVC_SW_Versions : 23|16@0+ (1,0) [0|255] ""  DUMMY_ECU
 SG_ CVC_Fan_Sts : 33|2@0+ (1,0) [0|3] ""  DUMMY_ECU
 SG_ CVC_DCChgPosTemp : 47|8@0+ (1,-40) [-40|210] "Degree C"  DUMMY_ECU
 SG_ CVC_DCChgNegTemp : 55|8@0+ (1,-40) [-40|210] "Degree C"  DUMMY_ECU
 SG_ CVC_ACChgLTerminalTemp : 63|8@0+ (1,-40) [-40|210] "Degree C"  DUMMY_ECU
 SG_ CVC_ACChgNTerminalTemp_Reserve : 71|8@0+ (1,-40) [-40|210] "Degree C"  DUMMY_ECU
 SG_ CVC_EdrivePump_Sts : 77|2@0+ (1,0) [0|3] ""  DUMMY_ECU
 SG_ CVC_BatPump_Sts : 79|2@0+ (1,0) [0|3] ""  DUMMY_ECU
 SG_ CVC_ActiveHeatingPower : 87|16@0+ (0.2,0) [0|8000] "kW"  DUMMY_ECU

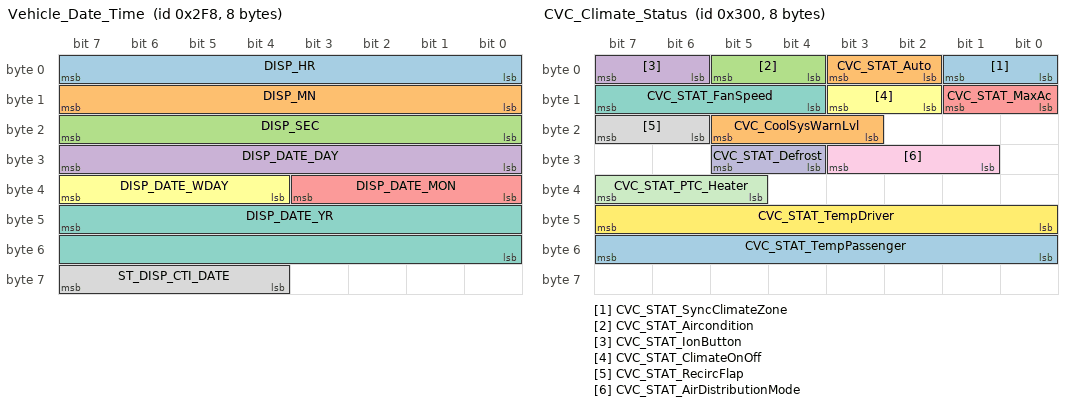
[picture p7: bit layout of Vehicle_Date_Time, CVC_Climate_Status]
BO_ 760 Vehicle_Date_Time: 8 CVC_B
 SG_ DISP_HR : 7|8@0+ (1,0) [0|23] "h"  BCM_FL,BCM_FR,BCM_R
 SG_ DISP_MN : 15|8@0+ (1,0) [0|59] "min"  BCM_FL,BCM_FR,BCM_R
 SG_ DISP_SEC : 23|8@0+ (1,0) [0|59] "s"  BCM_FL,BCM_FR,BCM_R
 SG_ DISP_DATE_DAY : 31|8@0+ (1,0) [1|31] "Day"  BCM_FL,BCM_FR,BCM_R
 SG_ DISP_DATE_MON : 35|4@0+ (1,0) [1|12] "Month"  BCM_FL,BCM_FR,BCM_R
 SG_ DISP_DATE_WDAY : 39|4@0+ (1,0) [0|15] ""  BCM_FL,BCM_FR,BCM_R
 SG_ DISP_DATE_YR : 47|16@0+ (1,0) [1|65534] "Year"  BCM_FL,BCM_FR,BCM_R
 SG_ ST_DISP_CTI_DATE : 63|4@0+ (1,0) [0|15] ""  BCM_FL,BCM_FR,BCM_R

BO_ 768 CVC_Climate_Status: 8 CVC_B
 SG_ CVC_STAT_SyncClimateZone : 1|2@0+ (1,0) [0|3] ""  DUMMY_ECU
 SG_ CVC_STAT_Auto : 3|2@0+ (1,0) [0|3] ""  DUMMY_ECU
 SG_ CVC_STAT_Aircondition : 5|2@0+ (1,0) [0|3] ""  DUMMY_ECU
 SG_ CVC_STAT_IonButton : 7|2@0+ (1,0) [0|3] ""  DUMMY_ECU
 SG_ CVC_STAT_MaxAc : 9|2@0+ (1,0) [0|3] ""  DUMMY_ECU
 SG_ CVC_STAT_ClimateOnOff : 11|2@0+ (1,0) [0|3] ""  DUMMY_ECU
 SG_ CVC_STAT_FanSpeed : 15|4@0+ (1,0) [0|15] ""  DUMMY_ECU
 SG_ CVC_STAT_RecircFlap : 23|2@0+ (1,0) [0|3] ""  DUMMY_ECU
 SG_ CVC_STAT_AirDistributionMode : 27|3@0+ (1,0) [0|7] ""  DUMMY_ECU
 SG_ CVC_STAT_Defrost : 29|2@0+ (1,0) [0|3] ""  DUMMY_ECU
 SG_ CVC_STAT_PTC_Heater : 39|3@0+ (1,0) [0|7] ""  DUMMY_ECU
 SG_ CVC_STAT_TempDriver : 47|8@0+ (0.5,0) [16|32] "Degree C"  DUMMY_ECU
 SG_ CVC_STAT_TempPassenger : 55|8@0+ (0.5,0) [16|32] "Degree C"  DUMMY_ECU
 SG_ CVC_CoolSysWarnLvl : 21|3@0+ (1,0) [0|7] ""  DUMMY_ECU

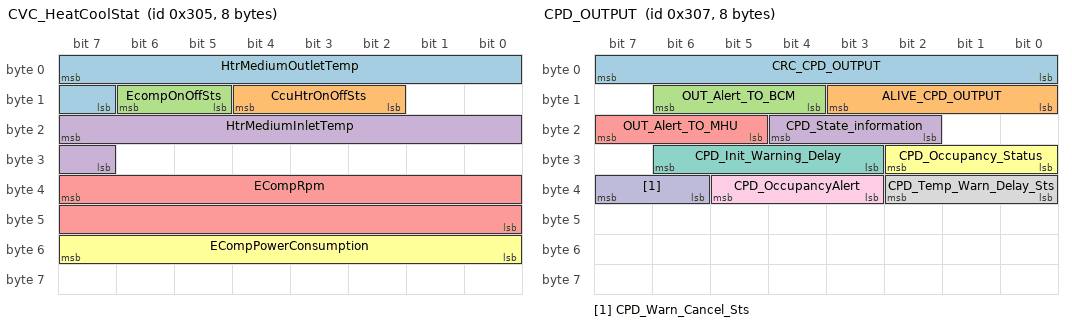
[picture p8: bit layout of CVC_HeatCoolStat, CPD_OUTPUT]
BO_ 773 CVC_HeatCoolStat: 8 CVC_B
 SG_ HtrMediumOutletTemp : 7|9@0+ (0.5,-40) [-40|200] "Degree C"  BCM_FR
 SG_ CcuHtrOnOffSts : 12|3@0+ (1,0) [0|7] ""  BCM_FR
 SG_ EcompOnOffSts : 14|2@0+ (1,0) [0|3] ""  BCM_FR
 SG_ HtrMediumInletTemp : 23|9@0+ (0.5,-40) [-40|200] "Degree C"  BCM_FR
 SG_ ECompRpm : 39|16@0+ (1,0) [0|12000] "rpm"  BCM_FR
 SG_ ECompPowerConsumption : 55|8@0+ (0.1,0) [0|12] "kW"  BCM_FR

BO_ 775 CPD_OUTPUT: 8 DKCU
 SG_ CRC_CPD_OUTPUT : 7|8@0+ (1,0) [0|255] ""  CVC_B
 SG_ ALIVE_CPD_OUTPUT : 11|4@0+ (1,0) [0|15] ""  CVC_B
 SG_ OUT_Alert_TO_BCM : 14|3@0+ (1,0) [0|7] ""  CVC_B
 SG_ CPD_State_information : 20|3@0+ (1,0) [0|7] ""  CVC_B
 SG_ OUT_Alert_TO_MHU : 23|3@0+ (1,0) [0|7] ""  CVC_B
 SG_ CPD_Occupancy_Status : 26|3@0+ (1,0) [0|7] ""  CVC_B
 SG_ CPD_Init_Warning_Delay : 30|4@0+ (1,0) [0|15] ""  CVC_B
 SG_ CPD_Temp_Warn_Delay_Sts : 34|3@0+ (1,0) [0|7] ""  CVC_B
 SG_ CPD_OccupancyAlert : 37|3@0+ (1,0) [0|7] ""  CVC_B
 SG_ CPD_Warn_Cancel_Sts : 39|2@0+ (1,0) [0|3] ""  CVC_B

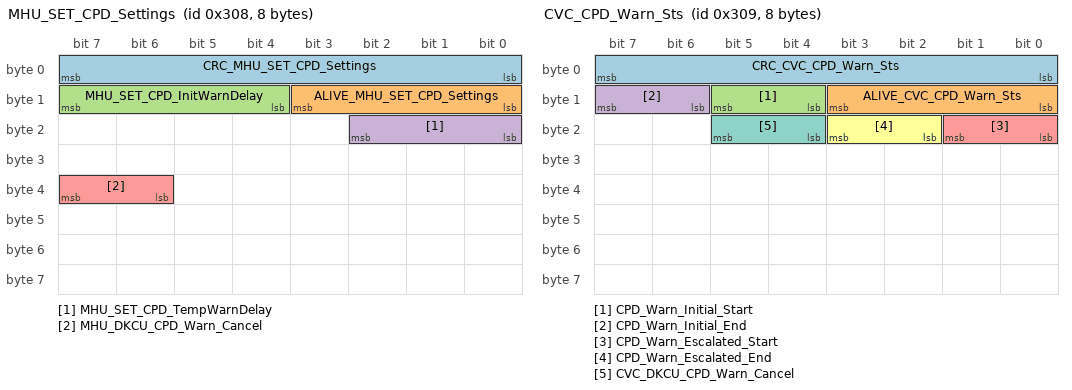
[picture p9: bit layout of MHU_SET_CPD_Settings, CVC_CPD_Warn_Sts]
BO_ 776 MHU_SET_CPD_Settings: 8 CVC_B
 SG_ CRC_MHU_SET_CPD_Settings : 7|8@0+ (1,0) [0|255] ""  DKCU
 SG_ ALIVE_MHU_SET_CPD_Settings : 11|4@0+ (1,0) [0|15] ""  DKCU
 SG_ MHU_SET_CPD_InitWarnDelay : 15|4@0+ (1,0) [0|15] ""  DKCU
 SG_ MHU_SET_CPD_TempWarnDelay : 18|3@0+ (1,0) [0|7] ""  DKCU
 SG_ MHU_DKCU_CPD_Warn_Cancel : 39|2@0+ (1,0) [0|3] ""  DKCU

BO_ 777 CVC_CPD_Warn_Sts: 8 CVC_B
 SG_ CRC_CVC_CPD_Warn_Sts : 7|8@0+ (1,0) [0|255] ""  DKCU
 SG_ ALIVE_CVC_CPD_Warn_Sts : 11|4@0+ (1,0) [0|15] ""  DKCU
 SG_ CPD_Warn_Initial_Start : 13|2@0+ (1,0) [0|3] ""  DKCU
 SG_ CPD_Warn_Initial_End : 15|2@0+ (1,0) [0|3] ""  DKCU
 SG_ CPD_Warn_Escalated_Start : 17|2@0+ (1,0) [0|3] ""  DKCU
 SG_ CPD_Warn_Escalated_End : 19|2@0+ (1,0) [0|3] ""  DKCU
 SG_ CVC_DKCU_CPD_Warn_Cancel : 21|2@0+ (1,0) [0|3] ""  DKCU

BO_ 778 CVC_DKCU_CommandRequest: 24 CVC_B
 SG_ CRC_CVC_DKCU_CommandRequest : 7|8@0+ (1,0) [0|255] ""  DKCU
 SG_ ALIVE_CVC_DKCU_CommandRequest : 11|4@0+ (1,0) [0|15] ""  DKCU
 SG_ CVC_DKCU_PhoneLocationReq : 18|3@0+ (1,0) [0|7] ""  DKCU
 SG_ Secure_ResetCnt_0x30A : 135|16@0+ (1,0) [0|65535] ""  DKCU
 SG_ Secure_MsgCnt_0x30A : 151|16@0+ (1,0) [0|65535] ""  DKCU
 SG_ Secure_MAC_0x30A : 167|32@0+ (1,0) [0|4294967295] ""  DKCU

BO_ 779 CVC_DK_TempIntervention_Start: 8 CVC_B
 SG_ CVC_DKCU_Temp_Intervention_Fdbk : 7|8@0+ (1,0) [0|255] ""  DKCU
 SG_ CVC_DKCU_Remote_Phone_Interventi : 15|8@0+ (1,0) [0|255] ""  DKCU

BO_ 862 CVC_Vehicle_info: 16 CVC_B
 SG_ CRC_CVC_Vehicle_info : 7|8@0+ (1,0) [0|255] ""  BCM_FL,BCM_FR,DKCU,BCM_R
 SG_ ALIVE_CVC_Vehicle_info : 11|4@0+ (1,0) [0|15] ""  BCM_FL,BCM_FR,DKCU,BCM_R
 SG_ CVC_VehLock_STS : 13|2@0+ (1,0) [0|3] ""  BCM_FL,BCM_FR,DKCU,BCM_R
 SG_ CVC_VehSpd_ScreenDisplay : 23|8@0+ (1,0) [0|254] ""  BCM_FL,BCM_FR,DKCU,BCM_R
 SG_ CVC_VehChgAllow : 25|2@0+ (1,0) [0|3] ""  BCM_FL,BCM_FR,DKCU,BCM_R
 SG_ CVC_VehDischgAllow : 15|2@0+ (1,0) [0|3] ""  BCM_FL,BCM_FR,DKCU,BCM_R
 SG_ Re_InitCharging_Req : 27|2@0+ (1,0) [0|3] ""  BCM_FL,BCM_FR,DKCU,BCM_R
 SG_ CVC_AntiTheft_Status : 30|3@0+ (1,0) [0|7] ""  BCM_FL,BCM_FR,DKCU,BCM_R
 SG_ CVC_GPSMonitorStatus : 31|1@0+ (1,0) [0|1] ""  DUMMY_ECU
 SG_ CVC_RLS_Malfunction : 37|1@0+ (1,0) [0|1] ""  DUMMY_ECU
 SG_ CVC_RLS_Response_Error : 36|1@0+ (1,0) [0|1] ""  DUMMY_ECU
 SG_ CVC_HV_DispSOC : 41|10@0+ (0.1,0) [0|100] "%"  BCM_FL,BCM_FR,BCM_R
 SG_ CVC_HV_Cur_LoadComp : 63|10@0+ (0.1,0) [0|100] "A"  BCM_FL,BCM_FR,BCM_R
 SG_ CVC_FrontWiperMotor_Status : 69|2@0+ (1,0) [0|3] ""  DUMMY_ECU
 SG_ CVC_RearWiperMotor_Status : 67|2@0+ (1,0) [0|3] ""  DUMMY_ECU

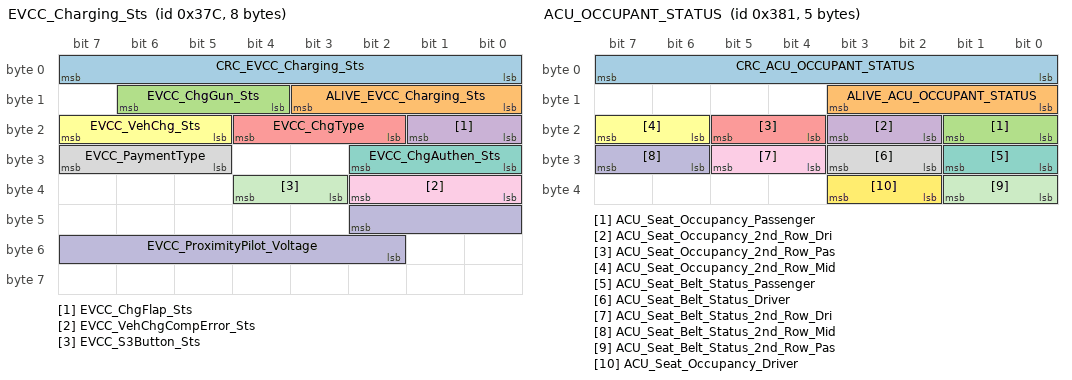
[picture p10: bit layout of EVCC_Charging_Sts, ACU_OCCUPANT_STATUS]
BO_ 892 EVCC_Charging_Sts: 8 CVC_B
 SG_ CRC_EVCC_Charging_Sts : 7|8@0+ (1,0) [0|255] ""  BCM_FL,BCM_FR,BCM_R
 SG_ ALIVE_EVCC_Charging_Sts : 11|4@0+ (1,0) [0|15] ""  BCM_FL,BCM_FR,BCM_R
 SG_ EVCC_ChgGun_Sts : 14|3@0+ (1,0) [0|7] ""  BCM_FL,BCM_FR,BCM_R
 SG_ EVCC_ChgFlap_Sts : 17|2@0+ (1,0) [0|3] ""  BCM_FL,BCM_FR,BCM_R
 SG_ EVCC_ChgType : 20|3@0+ (1,0) [0|7] ""  BCM_FL,BCM_FR,BCM_R
 SG_ EVCC_VehChg_Sts : 23|3@0+ (1,0) [0|7] ""  BCM_FL,BCM_FR,BCM_R
 SG_ EVCC_ChgAuthen_Sts : 26|3@0+ (1,0) [0|7] ""  BCM_FL,BCM_FR,BCM_R
 SG_ EVCC_PaymentType : 31|3@0+ (1,0) [0|7] ""  BCM_FL,BCM_FR,BCM_R
 SG_ EVCC_VehChgCompError_Sts : 34|3@0+ (1,0) [0|7] ""  BCM_FL,BCM_FR,BCM_R
 SG_ EVCC_ProximityPilot_Voltage : 42|9@0+ (0.01,0) [0|5] "V"  BCM_FL,BCM_FR,BCM_R
 SG_ EVCC_S3Button_Sts : 36|2@0+ (1,0) [0|3] ""  BCM_FL,BCM_FR,BCM_R

BO_ 897 ACU_OCCUPANT_STATUS: 5 CVC_B
 SG_ CRC_ACU_OCCUPANT_STATUS : 7|8@0+ (1,0) [0|255] ""  BCM_FL,BCM_FR,BCM_R
 SG_ ALIVE_ACU_OCCUPANT_STATUS : 11|4@0+ (1,0) [0|15] ""  BCM_FL,BCM_FR,BCM_R
 SG_ ACU_Seat_Occupancy_Passenger : 17|2@0+ (1,0) [0|3] ""  BCM_FL,BCM_FR,BCM_R
 SG_ ACU_Seat_Occupancy_2nd_Row_Dri : 19|2@0+ (1,0) [0|3] ""  BCM_FL,BCM_FR,BCM_R
 SG_ ACU_Seat_Occupancy_2nd_Row_Pas : 21|2@0+ (1,0) [0|3] ""  BCM_FL,BCM_FR,BCM_R
 SG_ ACU_Seat_Occupancy_2nd_Row_Mid : 23|2@0+ (1,0) [0|3] ""  BCM_FL,BCM_FR,BCM_R
 SG_ ACU_Seat_Belt_Status_Passenger : 25|2@0+ (1,0) [0|3] ""  BCM_FL,BCM_FR,BCM_R
 SG_ ACU_Seat_Belt_Status_Driver : 27|2@0+ (1,0) [0|3] ""  BCM_FL,BCM_FR,BCM_R
 SG_ ACU_Seat_Belt_Status_2nd_Row_Dri : 29|2@0+ (1,0) [0|3] ""  BCM_FL,BCM_FR,BCM_R
 SG_ ACU_Seat_Belt_Status_2nd_Row_Mid : 31|2@0+ (1,0) [0|3] ""  BCM_FL,BCM_FR,BCM_R
 SG_ ACU_Seat_Belt_Status_2nd_Row_Pas : 33|2@0+ (1,0) [0|3] ""  BCM_FL,BCM_FR,BCM_R
 SG_ ACU_Seat_Occupancy_Driver : 35|2@0+ (1,0) [0|3] ""  BCM_FL,BCM_FR,BCM_R

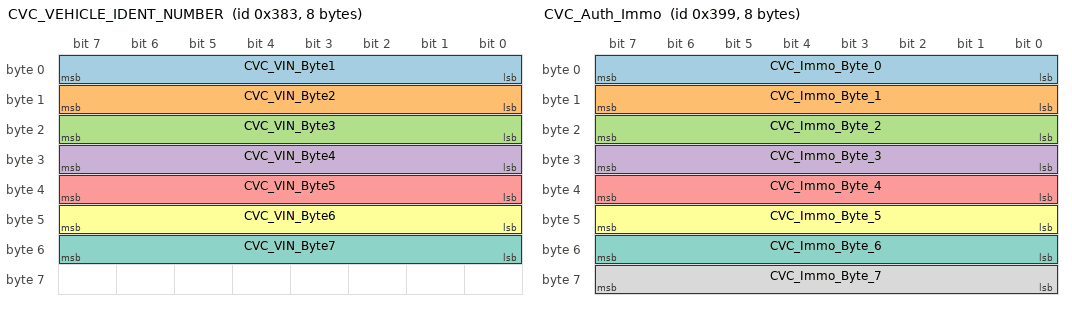
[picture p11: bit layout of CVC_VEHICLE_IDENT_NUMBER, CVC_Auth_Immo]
BO_ 899 CVC_VEHICLE_IDENT_NUMBER: 8 CVC_B
 SG_ CVC_VIN_Byte1 : 7|8@0+ (1,0) [0|255] ""  BCM_FL,BCM_FR,BCM_R
 SG_ CVC_VIN_Byte2 : 15|8@0+ (1,0) [0|255] ""  BCM_FL,BCM_FR,BCM_R
 SG_ CVC_VIN_Byte3 : 23|8@0+ (1,0) [0|255] ""  BCM_FL,BCM_FR,BCM_R
 SG_ CVC_VIN_Byte4 : 31|8@0+ (1,0) [0|255] ""  BCM_FL,BCM_FR,BCM_R
 SG_ CVC_VIN_Byte5 : 39|8@0+ (1,0) [0|255] ""  BCM_FL,BCM_FR,BCM_R
 SG_ CVC_VIN_Byte6 : 47|8@0+ (1,0) [0|255] ""  BCM_FL,BCM_FR,BCM_R
 SG_ CVC_VIN_Byte7 : 55|8@0+ (1,0) [0|255] ""  BCM_FL,BCM_FR,BCM_R

BO_ 905 CVC_Sts3: 64 CVC_B
 SG_ DK_CVC_Immo_Status : 33|2@0+ (1,0) [0|3] ""  DKCU
 SG_ CVC_IMMO_Sts : 35|2@0+ (1,0) [0|3] ""  BCM_FR
 SG_ Truncated_MAC : 71|32@0+ (1,0) [0|4294967295] ""  BCM_FR
 SG_ DKCU_AuthSessionStatus : 37|2@0+ (1,0) [0|3] ""  DKCU

BO_ 921 CVC_Auth_Immo: 8 CVC_B
 SG_ CVC_Immo_Byte_0 : 7|8@0+ (1,0) [0|255] ""  BCM_FR,DKCU
 SG_ CVC_Immo_Byte_1 : 15|8@0+ (1,0) [0|255] ""  BCM_FR,DKCU
 SG_ CVC_Immo_Byte_2 : 23|8@0+ (1,0) [0|255] ""  BCM_FR,DKCU
 SG_ CVC_Immo_Byte_3 : 31|8@0+ (1,0) [0|255] ""  BCM_FR,DKCU
 SG_ CVC_Immo_Byte_4 : 39|8@0+ (1,0) [0|255] ""  BCM_FR,DKCU
 SG_ CVC_Immo_Byte_5 : 47|8@0+ (1,0) [0|255] ""  BCM_FR,DKCU
 SG_ CVC_Immo_Byte_6 : 55|8@0+ (1,0) [0|255] ""  BCM_FR,DKCU
 SG_ CVC_Immo_Byte_7 : 63|8@0+ (1,0) [0|255] ""  BCM_FR,DKCU

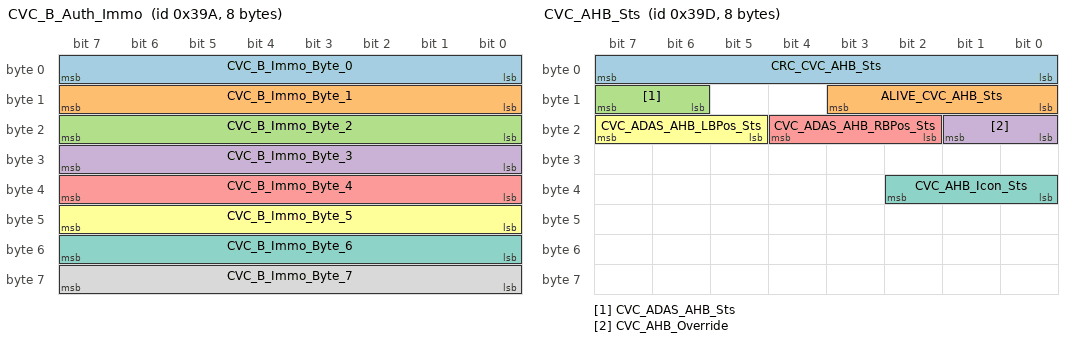
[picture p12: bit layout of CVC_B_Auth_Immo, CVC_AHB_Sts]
BO_ 922 CVC_B_Auth_Immo: 8 CVC_B
 SG_ CVC_B_Immo_Byte_0 : 7|8@0+ (1,0) [0|255] ""  BCM_FR
 SG_ CVC_B_Immo_Byte_1 : 15|8@0+ (1,0) [0|255] ""  BCM_FR
 SG_ CVC_B_Immo_Byte_2 : 23|8@0+ (1,0) [0|255] ""  BCM_FR
 SG_ CVC_B_Immo_Byte_3 : 31|8@0+ (1,0) [0|255] ""  BCM_FR
 SG_ CVC_B_Immo_Byte_4 : 39|8@0+ (1,0) [0|255] ""  BCM_FR
 SG_ CVC_B_Immo_Byte_5 : 47|8@0+ (1,0) [0|255] ""  BCM_FR
 SG_ CVC_B_Immo_Byte_6 : 55|8@0+ (1,0) [0|255] ""  BCM_FR
 SG_ CVC_B_Immo_Byte_7 : 63|8@0+ (1,0) [0|255] ""  BCM_FR

BO_ 925 CVC_AHB_Sts: 8 CVC_B
 SG_ CRC_CVC_AHB_Sts : 7|8@0+ (1,0) [0|255] ""  BCM_FL,BCM_FR,BCM_R
 SG_ ALIVE_CVC_AHB_Sts : 11|4@0+ (1,0) [0|15] ""  BCM_FL,BCM_FR,BCM_R
 SG_ CVC_ADAS_AHB_Sts : 15|2@0+ (1,0) [0|3] ""  BCM_FL,BCM_FR,BCM_R
 SG_ CVC_AHB_Override : 17|2@0+ (1,0) [0|3] ""  BCM_FL,BCM_FR,BCM_R
 SG_ CVC_ADAS_AHB_RBPos_Sts : 20|3@0+ (1,0) [0|7] ""  BCM_FL,BCM_FR,BCM_R
 SG_ CVC_ADAS_AHB_LBPos_Sts : 23|3@0+ (1,0) [0|7] ""  BCM_FL,BCM_FR,BCM_R
 SG_ CVC_AHB_Icon_Sts : 34|3@0+ (1,0) [0|7] ""  BCM_FL,BCM_FR,BCM_R

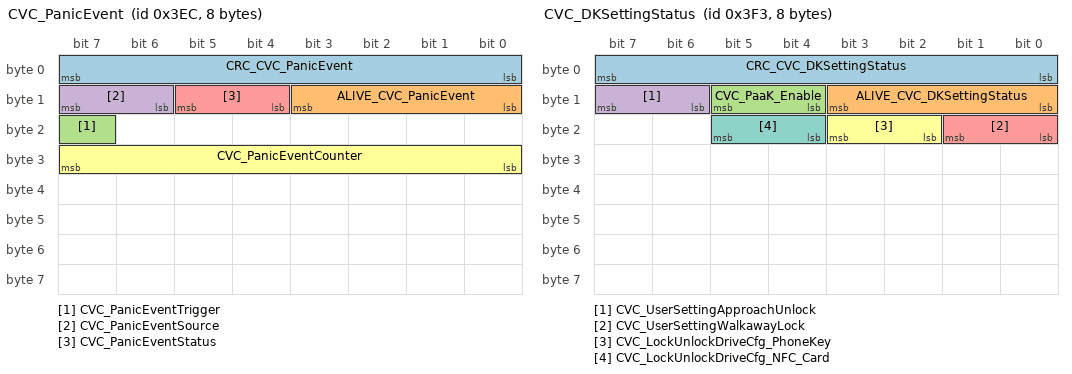
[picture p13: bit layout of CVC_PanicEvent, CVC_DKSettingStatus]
BO_ 1004 CVC_PanicEvent: 8 CVC_B
 SG_ CRC_CVC_PanicEvent : 7|8@0+ (1,0) [0|255] ""  DKCU
 SG_ ALIVE_CVC_PanicEvent : 11|4@0+ (1,0) [0|15] ""  DKCU
 SG_ CVC_PanicEventTrigger : 23|1@0+ (1,0) [0|1] ""  DKCU
 SG_ CVC_PanicEventSource : 15|2@0+ (1,0) [0|3] ""  DKCU
 SG_ CVC_PanicEventStatus : 13|2@0+ (1,0) [0|3] ""  DKCU
 SG_ CVC_PanicEventCounter : 31|8@0+ (1,0) [0|255] ""  DKCU

BO_ 1009 CVC_Amb_Intensity_Brightness: 8 CVC_B
 SG_ CVC_AmbientLightIntensityBrightn : 7|8@0+ (1,0) [0|100] "%"  BCM_FL,BCM_FR,BCM_R

BO_ 1011 CVC_DKSettingStatus: 8 CVC_B
 SG_ CRC_CVC_DKSettingStatus : 7|8@0+ (1,0) [0|255] ""  DKCU
 SG_ ALIVE_CVC_DKSettingStatus : 11|4@0+ (1,0) [0|15] ""  DKCU
 SG_ CVC_PaaK_Enable : 13|2@0+ (1,0) [0|3] ""  DKCU
 SG_ CVC_UserSettingApproachUnlock : 15|2@0+ (1,0) [0|3] ""  DKCU
 SG_ CVC_UserSettingWalkawayLock : 17|2@0+ (1,0) [0|3] ""  DKCU
 SG_ CVC_LockUnlockDriveCfg_PhoneKey : 19|2@0+ (1,0) [0|3] ""  DKCU
 SG_ CVC_LockUnlockDriveCfg_NFC_Card : 21|2@0+ (1,0) [0|3] ""  DKCU

BO_ 1015 CVC_MFS_Control_Button: 12 CVC_B
 SG_ CRC_CVC_MFS_Control_Button : 7|8@0+ (1,0) [0|255] ""  BCM_FL,BCM_FR,BCM_R
 SG_ ALIVE_CVC_MFS_Control_Button : 11|4@0+ (1,0) [0|15] ""  BCM_FL,BCM_FR,BCM_R
 SG_ MFS_L_Lever_Control : 14|3@0+ (1,0) [0|7] ""  BCM_FL,BCM_R
 SG_ MFS_L_LeverButton_Control : 24|3@0+ (1,0) [0|7] ""  BCM_FL,BCM_R
 SG_ MFS_L_Failure : 17|3@0+ (1,0) [0|7] ""  BCM_FL
 SG_ MFS_L_UpControl : 23|3@0+ (1,0) [0|7] ""  BCM_FL,BCM_FR,BCM_R
 SG_ MFS_L_DownControl : 20|3@0+ (1,0) [0|7] ""  BCM_FL,BCM_FR,BCM_R
 SG_ MFS_L_LeftControl : 30|3@0+ (1,0) [0|7] ""  BCM_FL,BCM_FR,BCM_R
 SG_ MFS_L_RightControl : 27|3@0+ (1,0) [0|7] ""  BCM_FL,BCM_FR,BCM_R
 SG_ MFS_LIN_error : 51|3@0+ (1,0) [0|7] ""  BCM_FL
 SG_ MFS_R_Lever_Control : 37|3@0+ (1,0) [0|7] ""  BCM_FL,BCM_R
 SG_ MFS_R_LeverButton_Control : 54|3@0+ (1,0) [0|7] ""  BCM_FL,BCM_R
 SG_ MFS_R_Failure : 48|3@0+ (1,0) [0|7] ""  BCM_FL
 SG_ MFS_R_UpControl : 47|3@0+ (1,0) [0|7] ""  BCM_FL
 SG_ MFS_R_DownControl : 34|3@0+ (1,0) [0|7] ""  BCM_FL
 SG_ MFS_R_LeftControl : 44|3@0+ (1,0) [0|7] ""  BCM_FL
 SG_ MFS_R_RightControl : 41|3@0+ (1,0) [0|7] ""  BCM_FL
 SG_ MFS_Delta_Scroll_Wheel_Left : 71|8@0+ (1,0) [0|255] ""  BCM_FL
 SG_ MFS_Delta_Scroll_Wheel_Right : 79|8@0+ (1,0) [0|255] ""  BCM_FL
 SG_ MFS_Scroll_Wheel_Left_Direction : 61|2@0+ (1,0) [0|3] ""  BCM_FL
 SG_ MFS_Scroll_Wheel_Right_Direction : 59|2@0+ (1,0) [0|3] ""  BCM_FL
 SG_ MFS_Scroll_Wheel_Left_Press : 57|2@0+ (1,0) [0|3] ""  BCM_FL
 SG_ MFS_Scroll_Wheel_Right_Press : 85|2@0+ (1,0) [0|3] ""  BCM_FL
 SG_ MFS_Scroll_Wheel_Left_Valid : 86|1@0+ (1,0) [0|1] ""  BCM_FL
 SG_ MFS_Scroll_Wheel_Right_Valid : 87|1@0+ (1,0) [0|1] ""  BCM_FL
 SG_ MFS_Scroll_Wheel_Left_ID : 83|4@0+ (1,0) [0|15] ""  BCM_FL,BCM_R
 SG_ MFS_Scroll_Wheel_Right_ID : 91|4@0+ (1,0) [0|15] ""  BCM_FL,BCM_R

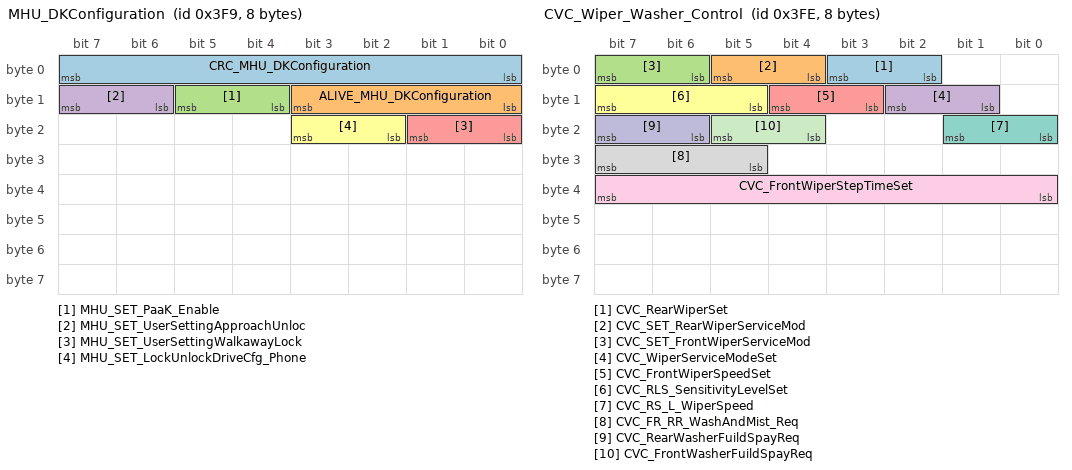
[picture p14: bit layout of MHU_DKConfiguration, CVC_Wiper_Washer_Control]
BO_ 1017 MHU_DKConfiguration: 8 CVC_B
 SG_ CRC_MHU_DKConfiguration : 7|8@0+ (1,0) [0|255] ""  DKCU
 SG_ ALIVE_MHU_DKConfiguration : 11|4@0+ (1,0) [0|15] ""  DKCU
 SG_ MHU_SET_PaaK_Enable : 13|2@0+ (1,0) [0|3] ""  DKCU
 SG_ MHU_SET_UserSettingApproachUnloc : 15|2@0+ (1,0) [0|3] ""  DKCU
 SG_ MHU_SET_UserSettingWalkawayLock : 17|2@0+ (1,0) [0|3] ""  DKCU
 SG_ MHU_SET_LockUnlockDriveCfg_Phone : 19|2@0+ (1,0) [0|3] ""  DKCU

BO_ 1022 CVC_Wiper_Washer_Control: 8 CVC_B
 SG_ CVC_RearWiperSet : 3|2@0+ (1,0) [0|2] ""  BCM_FL,BCM_FR,BCM_R
 SG_ CVC_SET_RearWiperServiceMod : 5|2@0+ (1,0) [0|3] ""  BCM_FL,BCM_FR,BCM_R
 SG_ CVC_SET_FrontWiperServiceMod : 7|2@0+ (1,0) [0|3] ""  BCM_FL,BCM_FR,BCM_R
 SG_ CVC_WiperServiceModeSet : 10|2@0+ (1,0) [0|2] ""  BCM_FL,BCM_FR,BCM_R
 SG_ CVC_FrontWiperSpeedSet : 12|2@0+ (1,0) [0|3] ""  BCM_FL,BCM_FR,BCM_R
 SG_ CVC_RLS_SensitivityLevelSet : 15|3@0+ (1,0) [1|4] ""  BCM_FL,BCM_FR,BCM_R
 SG_ CVC_RS_L_WiperSpeed : 17|2@0+ (1,0) [0|3] ""  BCM_FL,BCM_FR,BCM_R
 SG_ CVC_FR_RR_WashAndMist_Req : 31|3@0+ (1,0) [0|7] ""  BCM_FL,BCM_FR,BCM_R
 SG_ CVC_FrontWiperStepTimeSet : 39|8@0+ (1,0) [0|255] "s"  BCM_FL,BCM_FR,BCM_R
 SG_ CVC_RearWasherFuildSpayReq : 23|2@0+ (1,0) [0|2] ""  BCM_FL,BCM_FR,BCM_R
 SG_ CVC_FrontWasherFuildSpayReq : 21|2@0+ (1,0) [0|2] ""  BCM_FL,BCM_FR,BCM_R

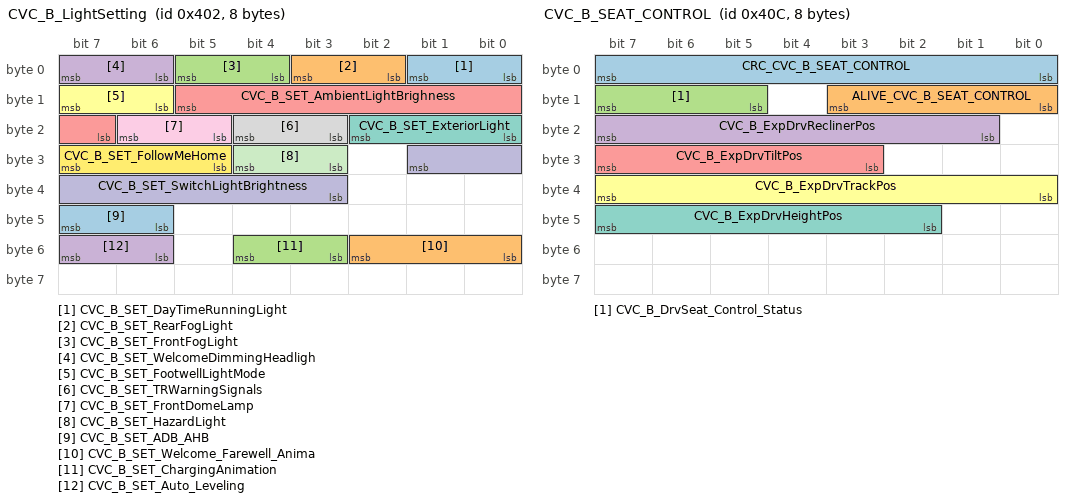
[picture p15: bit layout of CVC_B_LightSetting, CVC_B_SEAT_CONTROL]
BO_ 1026 CVC_B_LightSetting: 8 CVC_B
 SG_ CVC_B_SET_DayTimeRunningLight : 1|2@0+ (1,0) [0|3] ""  BCM_FL,BCM_FR,BCM_R
 SG_ CVC_B_SET_RearFogLight : 3|2@0+ (1,0) [0|3] ""  BCM_FL,BCM_FR,BCM_R
 SG_ CVC_B_SET_FrontFogLight : 5|2@0+ (1,0) [0|3] ""  BCM_FL,BCM_FR,BCM_R
 SG_ CVC_B_SET_WelcomeDimmingHeadligh : 7|2@0+ (1,0) [0|3] ""  BCM_FL,BCM_FR,BCM_R
 SG_ CVC_B_SET_AmbientLightBrighness : 13|7@0+ (1,0) [0|100] "%"  BCM_FL,BCM_FR,BCM_R
 SG_ CVC_B_SET_FootwellLightMode : 15|2@0+ (1,0) [0|3] ""  BCM_FL,BCM_FR,BCM_R
 SG_ CVC_B_SET_ExteriorLight : 18|3@0+ (1,0) [0|7] ""  BCM_FL,BCM_FR,BCM_R
 SG_ CVC_B_SET_TRWarningSignals : 20|2@0+ (1,0) [0|3] ""  BCM_FL,BCM_FR,BCM_R
 SG_ CVC_B_SET_FrontDomeLamp : 22|2@0+ (1,0) [0|3] ""  BCM_FL,BCM_FR,BCM_R
 SG_ CVC_B_SET_SwitchLightBrightness : 25|7@0+ (1,0) [0|100] "%"  BCM_FL,BCM_FR,BCM_R
 SG_ CVC_B_SET_HazardLight : 28|2@0+ (1,0) [0|3] ""  BCM_FL,BCM_FR,BCM_R
 SG_ CVC_B_SET_FollowMeHome : 31|3@0+ (1,0) [0|7] ""  BCM_FL,BCM_FR,BCM_R
 SG_ CVC_B_SET_ADB_AHB : 47|2@0+ (1,0) [0|3] ""  BCM_FL,BCM_FR,BCM_R
 SG_ CVC_B_SET_Welcome_Farewell_Anima : 50|3@0+ (1,0) [0|7] ""  BCM_FL,BCM_FR,BCM_R
 SG_ CVC_B_SET_ChargingAnimation : 52|2@0+ (1,0) [0|3] ""  BCM_FL,BCM_FR,BCM_R
 SG_ CVC_B_SET_Auto_Leveling : 55|2@0+ (1,0) [0|3] ""  BCM_FL,BCM_FR,BCM_R

BO_ 1032 CVC_ComfortReq: 8 CVC_B
 SG_ CVC_SET_MirrorAuto : 1|2@0+ (1,0) [0|3] ""  BCM_FL,BCM_FR
 SG_ CVC_SET_MirrorAutoUnfold : 3|2@0+ (1,0) [0|3] ""  BCM_FL,BCM_FR
 SG_ CVC_SET_WLC : 5|2@0+ (1,0) [0|3] ""  BCM_FL,BCM_FR
 SG_ CVC_SET_AutoRearWiper : 7|2@0+ (1,0) [0|3] ""  BCM_FL,BCM_FR
 SG_ CVC_SET_RearHeatedWindow : 9|2@0+ (1,0) [0|3] ""  BCM_FL,BCM_FR
 SG_ CVC_TPMSReset : 11|2@0+ (1,0) [0|3] ""  BCM_FL,BCM_FR
 SG_ CVC_SET_MirrorDefaultSetting : 13|2@0+ (1,0) [0|3] ""  BCM_FL,BCM_FR
 SG_ CVC_SET_MirrorReverseLink : 15|2@0+ (1,0) [0|3] ""  BCM_FL,BCM_FR
 SG_ CVC_SET_AntiTheftMode : 17|2@0+ (1,0) [0|3] ""  BCM_FL,BCM_FR
 SG_ CVC_SET_WLCReminder : 21|2@0+ (1,0) [0|3] ""  BCM_FL,BCM_FR
 SG_ CVC_SET_ClimateKeepOn : 25|2@0+ (1,0) [0|3] ""  BCM_FL,BCM_FR
 SG_ CVC_SET_WLC2 : 27|2@0+ (1,0) [0|3] ""  BCM_FL,BCM_FR
 SG_ CVC_SET_WLC2Reminder : 29|2@0+ (1,0) [0|3] ""  BCM_FL,BCM_FR
 SG_ CVC_SET_WLC_Phoneforgetalert : 35|2@0+ (1,0) [0|3] ""  BCM_FL,BCM_FR
 SG_ CVC_SteeringWheel_Adjust_Req : 39|3@0+ (1,0) [0|7] ""  BCM_FL
 SG_ CVC_SteeringWheelPosX_Req : 47|7@0+ (1,-50) [-50|50] "mm"  BCM_FL
 SG_ CVC_SteeringWheelPosY_Req : 55|7@0+ (1,-50) [-50|50] "mm"  BCM_FL

BO_ 1033 TBOX_IntrusionAlertStatus: 8 CVC_B
 SG_ TBOX_IntrusionAlertStatus : 31|2@0+ (1,0) [0|3] ""  BCM_FL,BCM_FR,BCM_R

BO_ 1036 CVC_B_SEAT_CONTROL: 8 CVC_B
 SG_ CRC_CVC_B_SEAT_CONTROL : 7|8@0+ (1,0) [0|255] ""  BCM_FL
 SG_ ALIVE_CVC_B_SEAT_CONTROL : 11|4@0+ (1,0) [0|15] ""  BCM_FL
 SG_ CVC_B_DrvSeat_Control_Status : 15|3@0+ (1,0) [0|7] ""  BCM_FL
 SG_ CVC_B_ExpDrvReclinerPos : 23|7@0+ (1,0) [0|127] "degree"  BCM_FL
 SG_ CVC_B_ExpDrvTiltPos : 31|5@0+ (1,0) [0|31] "mm"  BCM_FL
 SG_ CVC_B_ExpDrvTrackPos : 39|8@0+ (1,0) [0|255] "mm"  BCM_FL
 SG_ CVC_B_ExpDrvHeightPos : 47|6@0+ (1,0) [0|63] "mm"  BCM_FL

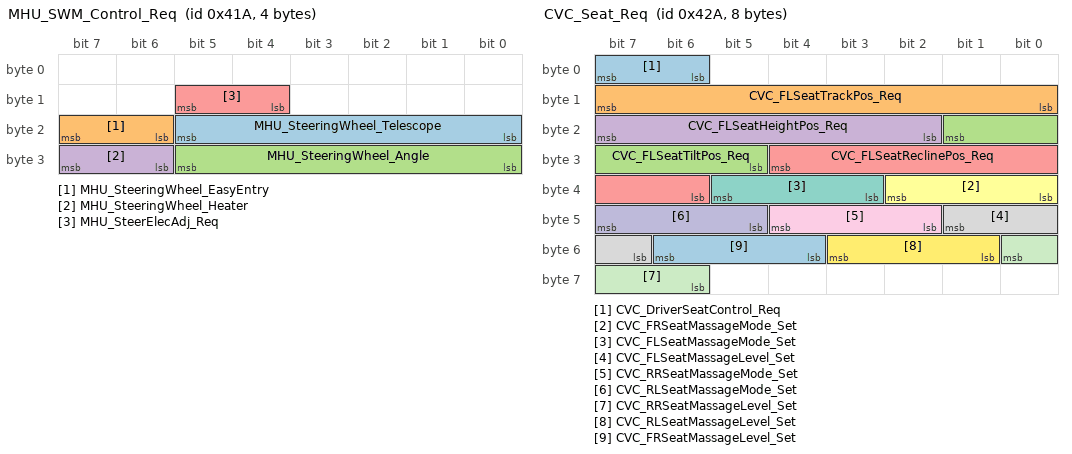
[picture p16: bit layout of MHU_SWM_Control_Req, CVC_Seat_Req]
BO_ 1050 MHU_SWM_Control_Req: 4 CVC_B
 SG_ MHU_SteeringWheel_Telescope : 21|6@0+ (1,-20) [-20|20] "mm"  BCM_FL
 SG_ MHU_SteeringWheel_EasyEntry : 23|2@0+ (1,0) [0|3] ""  BCM_FL
 SG_ MHU_SteeringWheel_Angle : 29|6@0+ (0.1,-2.1) [-2.1|2.1] "Degree"  BCM_FL
 SG_ MHU_SteeringWheel_Heater : 31|2@0+ (1,0) [0|3] ""  BCM_FL
 SG_ MHU_SteerElecAdj_Req : 13|2@0+ (1,0) [0|3] ""  BCM_FL

BO_ 1066 CVC_Seat_Req: 8 CVC_B
 SG_ CVC_DriverSeatControl_Req : 7|2@0+ (1,0) [0|3] ""  BCM_FL
 SG_ CVC_FLSeatTrackPos_Req : 15|8@0+ (1,0) [0|240] "mm"  BCM_FL
 SG_ CVC_FLSeatTiltPos_Req : 17|5@0+ (1,0) [0|18] "mm"  BCM_FL
 SG_ CVC_FLSeatHeightPos_Req : 23|6@0+ (1,0) [0|52] "mm"  BCM_FL
 SG_ CVC_FLSeatReclinePos_Req : 28|7@0+ (1,0) [0|70] "Degree"  BCM_FL
 SG_ CVC_FRSeatMassageMode_Set : 34|3@0+ (1,0) [0|7] ""  BCM_FR
 SG_ CVC_FLSeatMassageMode_Set : 37|3@0+ (1,0) [0|7] ""  BCM_FL
 SG_ CVC_FLSeatMassageLevel_Set : 41|3@0+ (1,0) [0|7] ""  BCM_FL
 SG_ CVC_RRSeatMassageMode_Set : 44|3@0+ (1,0) [0|7] ""  DUMMY_ECU
 SG_ CVC_RLSeatMassageMode_Set : 47|3@0+ (1,0) [0|7] ""  DUMMY_ECU
 SG_ CVC_RRSeatMassageLevel_Set : 48|3@0+ (1,0) [0|7] ""  DUMMY_ECU
 SG_ CVC_RLSeatMassageLevel_Set : 51|3@0+ (1,0) [0|7] ""  DUMMY_ECU
 SG_ CVC_FRSeatMassageLevel_Set : 54|3@0+ (1,0) [0|7] ""  BCM_FR

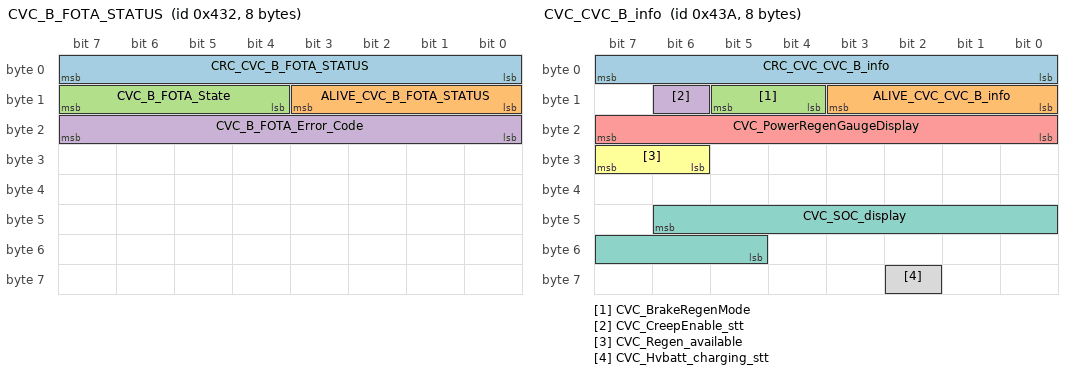
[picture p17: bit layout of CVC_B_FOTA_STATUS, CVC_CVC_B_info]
BO_ 1074 CVC_B_FOTA_STATUS: 8 CVC_B
 SG_ CRC_CVC_B_FOTA_STATUS : 7|8@0+ (1,0) [0|255] ""  BCM_FL,BCM_FR,BCM_R
 SG_ ALIVE_CVC_B_FOTA_STATUS : 11|4@0+ (1,0) [0|15] ""  BCM_FL,BCM_FR,BCM_R
 SG_ CVC_B_FOTA_State : 15|4@0+ (1,0) [0|15] ""  BCM_FL,BCM_FR,BCM_R
 SG_ CVC_B_FOTA_Error_Code : 23|8@0+ (1,0) [0|255] ""  BCM_FL,BCM_FR,BCM_R

BO_ 1082 CVC_CVC_B_info: 8 CVC_B
 SG_ CRC_CVC_CVC_B_info : 7|8@0+ (1,0) [0|255] ""  BCM_FL,BCM_FR,BCM_R
 SG_ ALIVE_CVC_CVC_B_info : 11|4@0+ (1,0) [0|15] ""  BCM_FL,BCM_FR,BCM_R
 SG_ CVC_BrakeRegenMode : 13|2@0+ (1,0) [0|3] ""  BCM_FL,BCM_FR,BCM_R
 SG_ CVC_CreepEnable_stt : 14|1@0+ (1,0) [0|1] ""  BCM_FL,BCM_FR,BCM_R
 SG_ CVC_PowerRegenGaugeDisplay : 23|8@0+ (1,-100) [-100|100] "%"  BCM_FL,BCM_FR,BCM_R
 SG_ CVC_Regen_available : 31|2@0+ (1,0) [0|3] ""  BCM_FL,BCM_FR,BCM_R
 SG_ CVC_SOC_display : 46|10@0+ (0.1,0) [0|100] "%"  BCM_FL,BCM_FR,BCM_R
 SG_ CVC_Hvbatt_charging_stt : 58|1@0+ (1,0) [0|1] ""  BCM_FL,BCM_FR,BCM_R

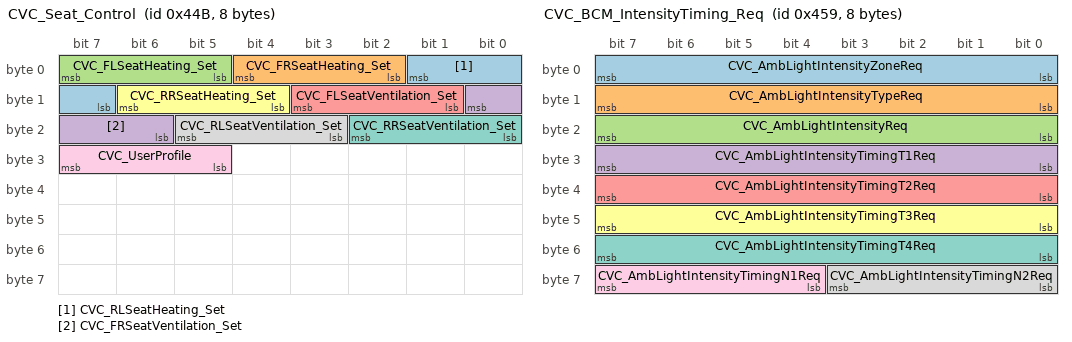
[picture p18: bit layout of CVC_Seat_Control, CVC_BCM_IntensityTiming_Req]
BO_ 1099 CVC_Seat_Control: 8 CVC_B
 SG_ CVC_RLSeatHeating_Set : 1|3@0+ (1,0) [0|7] ""  DUMMY_ECU
 SG_ CVC_FRSeatHeating_Set : 4|3@0+ (1,0) [0|7] ""  BCM_FR
 SG_ CVC_FLSeatHeating_Set : 7|3@0+ (1,0) [0|7] ""  BCM_FL
 SG_ CVC_FRSeatVentilation_Set : 8|3@0+ (1,0) [0|7] ""  BCM_FR
 SG_ CVC_FLSeatVentilation_Set : 11|3@0+ (1,0) [0|7] ""  BCM_FL
 SG_ CVC_RRSeatHeating_Set : 14|3@0+ (1,0) [0|7] ""  DUMMY_ECU
 SG_ CVC_RRSeatVentilation_Set : 18|3@0+ (1,0) [0|7] ""  DUMMY_ECU
 SG_ CVC_RLSeatVentilation_Set : 21|3@0+ (1,0) [0|7] ""  DUMMY_ECU
 SG_ CVC_UserProfile : 31|3@0+ (1,0) [0|7] ""  BCM_FL,BCM_FR

BO_ 1112 CVC_BCM_Color_Req: 8 CVC_B
 SG_ CVC_AmbientLightColorZoneReq : 7|8@0+ (1,0) [0|31] ""  BCM_FL,BCM_FR,BCM_R
 SG_ CVC_AmbientLightColorRed : 15|8@0+ (1,0) [0|255] ""  BCM_FL,BCM_FR,BCM_R
 SG_ CVC_AmbientLightColorGreen : 23|8@0+ (1,0) [0|255] ""  BCM_FL,BCM_FR,BCM_R
 SG_ CVC_AmbientLightColorBlue : 31|8@0+ (1,0) [0|255] ""  BCM_FL,BCM_FR,BCM_R

BO_ 1113 CVC_BCM_IntensityTiming_Req: 8 CVC_B
 SG_ CVC_AmbLightIntensityZoneReq : 7|8@0+ (1,0) [0|31] ""  BCM_FL,BCM_FR,BCM_R
 SG_ CVC_AmbLightIntensityTypeReq : 15|8@0+ (1,0) [0|5] ""  BCM_FL,BCM_FR,BCM_R
 SG_ CVC_AmbLightIntensityReq : 23|8@0+ (1,0) [0|100] "%"  BCM_FL,BCM_FR,BCM_R
 SG_ CVC_AmbLightIntensityTimingT1Req : 31|8@0+ (0.1,0) [0|25.5] "s"  BCM_FL,BCM_FR,BCM_R
 SG_ CVC_AmbLightIntensityTimingT2Req : 39|8@0+ (0.1,0) [0|25.5] "s"  BCM_FL,BCM_FR,BCM_R
 SG_ CVC_AmbLightIntensityTimingT3Req : 47|8@0+ (0.1,0) [0|25.5] "s"  BCM_FL,BCM_FR,BCM_R
 SG_ CVC_AmbLightIntensityTimingT4Req : 55|8@0+ (0.1,0) [0|25.5] "s"  BCM_FL,BCM_FR,BCM_R
 SG_ CVC_AmbLightIntensityTimingN2Req : 59|4@0+ (1,0) [0|15] ""  BCM_FL,BCM_FR,BCM_R
 SG_ CVC_AmbLightIntensityTimingN1Req : 63|4@0+ (1,0) [0|15] ""  BCM_FL,BCM_FR,BCM_R

BO_ 1114 CVC_AmbLightReq: 8 CVC_B
 SG_ CVC_Z3_AmbLightZoneFLReq : 1|2@0+ (1,0) [0|3] ""  BCM_FL,BCM_FR,BCM_R
 SG_ CVC_Z1_AmbLightZoneIPDrivReq : 3|2@0+ (1,0) [0|3] ""  BCM_FL,BCM_FR,BCM_R
 SG_ CVC_Z2_AmbLightZoneFRReq : 5|2@0+ (1,0) [0|3] ""  BCM_FL,BCM_FR,BCM_R
 SG_ CVC_Z5_AmbLightZoneRLReq : 7|2@0+ (1,0) [0|3] ""  BCM_FL,BCM_FR,BCM_R
 SG_ CVC_Z4_AmbLightZoneRRReq : 9|2@0+ (1,0) [0|3] ""  BCM_FL,BCM_FR,BCM_R
 SG_ CVC_Z3B_AmbLightZoneFLReq : 11|2@0+ (1,0) [0|3] ""  BCM_FL,BCM_FR,BCM_R
 SG_ CVC_Z2B_AmbLightZoneFRReq : 13|2@0+ (1,0) [0|3] ""  BCM_FL,BCM_FR,BCM_R
 SG_ CVC_Z6_AmbLightZoneIPPassReq : 15|2@0+ (1,0) [0|3] ""  BCM_FL,BCM_FR,BCM_R
 SG_ CVC_Z6B_AmbLightZoneIPPassReq : 17|2@0+ (1,0) [0|3] ""  BCM_FL,BCM_FR,BCM_R
 SG_ CVC_Z7_AmbLightZoneConsLReq : 19|2@0+ (1,0) [0|3] ""  BCM_FL,BCM_FR,BCM_R
 SG_ CVC_Z7B_AmbLightZoneConsLReq : 21|2@0+ (1,0) [0|3] ""  BCM_FL,BCM_FR,BCM_R
 SG_ CVC_Z8_AmbLightZoneConsRReq : 23|2@0+ (1,0) [0|3] ""  BCM_FL,BCM_FR,BCM_R
 SG_ CVC_Z8B_AmbLightZoneConsRReq : 25|2@0+ (1,0) [0|3] ""  BCM_FL,BCM_FR,BCM_R
 SG_ CVC_Z9_AmbLightZoneConsRLReq : 27|2@0+ (1,0) [0|3] ""  BCM_FL,BCM_FR,BCM_R
 SG_ CVC_Z10_AmbLightZoneConsRRReq : 29|2@0+ (1,0) [0|3] ""  BCM_FL,BCM_FR,BCM_R
 SG_ CVC_Z5B_AmbLightZoneRLReq : 31|2@0+ (1,0) [0|3] ""  BCM_FL,BCM_FR,BCM_R
 SG_ CVC_Z4B_AmbLightZoneRRReq : 33|2@0+ (1,0) [0|3] ""  BCM_FL,BCM_FR,BCM_R

BO_ 1117 FCAM_Heater_Request: 4 CVC_B
 SG_ CRC_FCAM_Heater_Request : 7|8@0+ (1,0) [0|255] ""  BCM_FL
 SG_ ALIVE_FCAM_Heater_Request : 11|4@0+ (1,0) [0|15] ""  BCM_FL
 SG_ FCAM_HeaterActivation_Req : 16|1@0+ (1,0) [0|1] ""  BCM_FL

BO_ 1171 BMS_WarnMsg: 8 CVC_B
 SG_ CRC_BMS_WarnMsg : 7|8@0+ (1,0) [0|255] ""  BCM_FL,BCM_FR,BCM_R
 SG_ ALIVE_BMS_WarnMsg : 11|4@0+ (1,0) [0|15] ""  BCM_FL,BCM_FR,BCM_R
 SG_ BMS_PackTempSts : 13|2@0+ (1,0) [0|3] ""  BCM_FL,BCM_FR,BCM_R
 SG_ BMS_ThermalRunaway : 14|1@0+ (1,0) [0|1] ""  BCM_FL,BCM_FR,BCM_R
 SG_ BMS_BatteryReplacement : 15|1@0+ (1,0) [0|1] ""  BCM_FL,BCM_FR,BCM_R
 SG_ BMS_Warning_PowerDegrade : 16|1@0+ (1,0) [0|1] ""  BCM_FL,BCM_FR,BCM_R
 SG_ BMS_Warning_DeltaSoC : 17|1@0+ (1,0) [0|1] ""  BCM_FL,BCM_FR,BCM_R
 SG_ BMS_Warning_HVILSts : 18|1@0+ (1,0) [0|1] ""  BCM_FL,BCM_FR,BCM_R
 SG_ BMS_Warning_Isolation : 19|1@0+ (1,0) [0|1] ""  BCM_FL,BCM_FR,BCM_R
 SG_ BMS_Warning_CoolantLeakage : 20|1@0+ (1,0) [0|1] ""  BCM_FL,BCM_FR,BCM_R
 SG_ BMS_MalfunctionSts : 21|1@0+ (1,0) [0|1] ""  BCM_FL,BCM_FR,BCM_R
 SG_ BMS_LowBattery : 23|2@0+ (1,0) [0|3] ""  BCM_FL,BCM_FR,BCM_R
 SG_ BMS_Warning_DeltaTemperature : 31|8@0+ (1,0) [0|255] ""  BCM_FL,BCM_FR,BCM_R
 SG_ BMS_Warning_BDUTemperatureSts : 39|8@0+ (1,0) [0|255] ""  BCM_FL,BCM_FR,BCM_R
 SG_ BMS_Warning_Contactor_Aging : 47|1@0+ (1,0) [0|1] ""  BCM_FL,BCM_FR,BCM_R
 SG_ BMS_Reserved_signal4 : 55|8@0+ (1,0) [0|255] ""  BCM_FL,BCM_FR,BCM_R
 SG_ BMS_Reserved_signal5 : 63|8@0+ (1,0) [0|255] ""  BCM_FL,BCM_FR,BCM_R

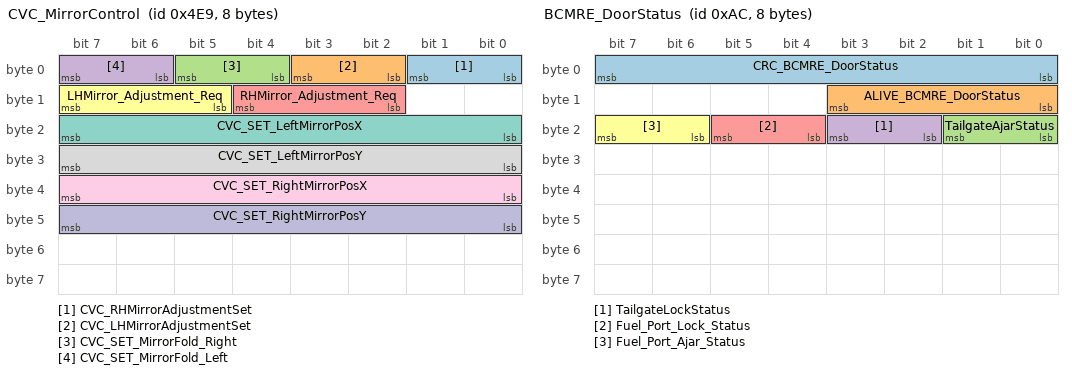
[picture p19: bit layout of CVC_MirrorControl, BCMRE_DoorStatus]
BO_ 1257 CVC_MirrorControl: 8 CVC_B
 SG_ CVC_RHMirrorAdjustmentSet : 1|2@0+ (1,0) [0|3] ""  BCM_FL,BCM_FR,BCM_R
 SG_ CVC_LHMirrorAdjustmentSet : 3|2@0+ (1,0) [0|3] ""  BCM_FL,BCM_FR,BCM_R
 SG_ CVC_SET_MirrorFold_Right : 5|2@0+ (1,0) [0|3] ""  BCM_FL,BCM_FR,BCM_R
 SG_ CVC_SET_MirrorFold_Left : 7|2@0+ (1,0) [0|3] ""  BCM_FL,BCM_FR,BCM_R
 SG_ RHMirror_Adjustment_Req : 12|3@0+ (1,0) [0|5] ""  BCM_FR
 SG_ LHMirror_Adjustment_Req : 15|3@0+ (1,0) [0|5] ""  BCM_FL
 SG_ CVC_SET_LeftMirrorPosX : 23|8@0+ (1,-15) [-15|15] "deg"  BCM_FL
 SG_ CVC_SET_LeftMirrorPosY : 31|8@0+ (1,-15) [-15|15] "deg"  BCM_FL
 SG_ CVC_SET_RightMirrorPosX : 39|8@0+ (1,-15) [-15|15] "deg"  BCM_FR
 SG_ CVC_SET_RightMirrorPosY : 47|8@0+ (1,-15) [-15|15] "deg"  BCM_FR

BO_ 1879 CVC_ThermalDebug: 16 CVC_B
 SG_ CVC_TMSMode : 23|8@0+ (1,0) [0|255] ""  DUMMY_ECU
 SG_ CVC_HVCHPowerLim : 31|10@0+ (0.1,0) [0|50] "kW"  DUMMY_ECU
 SG_ CVC_HVCHOffCode : 85|16@0+ (1,0) [0|65535] ""  DUMMY_ECU
 SG_ CVC_AirPTCOffCode : 37|16@0+ (1,0) [0|65535] ""  DUMMY_ECU
 SG_ CVC_CompOffCode : 53|32@0+ (1,0) [0|4294967295] ""  DUMMY_ECU

BO_ 1889 CVC_ITM_Debug: 20 CVC_B
 SG_ EAC_power_lim : 23|8@0+ (0.08,0) [0|3175] "kW"  DUMMY_ECU
 SG_ EAC_speed : 31|8@0+ (50,0) [0|12750] "rpm"  DUMMY_ECU
 SG_ EAC_target_speed : 39|8@0+ (50,0) [0|12750] "rpm"  DUMMY_ECU
 SG_ EAC_status : 47|3@0+ (1,0) [0|7] ""  DUMMY_ECU
 SG_ EAC_drive_request : 44|2@0+ (1,0) [0|3] "rpm"  DUMMY_ECU
 SG_ MWV1_OperationMode : 51|4@0+ (1,0) [0|15] ""  DUMMY_ECU
 SG_ MWV2_OperationMode : 55|4@0+ (1,0) [0|15] ""  DUMMY_ECU
 SG_ LEXV2_CurrentPosition : 63|16@0+ (1,0) [0|65535] ""  DUMMY_ECU
 SG_ CVC_LEXV2_PositionRequest : 79|16@0+ (1,0) [0|65535] ""  DUMMY_ECU
 SG_ LEXV1_CurrentPosition : 95|16@0+ (1,0) [0|65535] ""  DUMMY_ECU
 SG_ CVC_LEXV1_PositionRequest : 111|16@0+ (1,0) [0|65535] ""  DUMMY_ECU
 SG_ UIF_Temperatur : 127|12@0+ (0.1,-80) [-80|17920] "Degree C"  DUMMY_ECU
 SG_ BlwSpeed : 143|8@0+ (20,0) [0|255] "rpm"  DUMMY_ECU
 SG_ BlwRotationSpd : 151|8@0+ (20,0) [0|255] "rpm"  DUMMY_ECU

BO_ 1968 CVC_Synchronization_Master: 8 CVC_B
 SG_ Sync_TripCnt : 7|24@0+ (1,0) [0|16777215] ""  BCM_FL,BCM_FR,DKCU
 SG_ Sync_ResetCnt : 31|16@0+ (1,0) [0|65535] ""  BCM_FL,BCM_FR,DKCU
 SG_ Sync_MAC : 47|24@0+ (1,0) [0|16777215] ""  BCM_FL,BCM_FR,DKCU

BO_ 168 BCMRE_Climate_Feedback: 20 BCM_R
 SG_ BCMRE_Climate_RearAirDistFlapPos : 47|8@0+ (1,0) [0|100] "%"  CVC_B
 SG_ BCMRE_Climate_RearTempFlapPos : 55|8@0+ (1,0) [0|100] "%"  CVC_B
 SG_ BCMRE_Climate_RearAirRecirculati : 60|1@0+ (1,0) [0|1] ""  CVC_B
 SG_ BCMRE_Climate_RearAirDistFlapSts : 61|1@0+ (1,0) [0|1] ""  CVC_B
 SG_ BCMRE_Climate_RearTempFlapSts : 62|1@0+ (1,0) [0|1] ""  CVC_B
 SG_ BCMRE_Climate_RearAirRecirc_0000 : 15|8@0+ (1,0) [0|100] "%"  CVC_B
 SG_ BCMRE_Climate_FrontPassAirMode_F : 23|8@0+ (1,0) [0|100] "%"  CVC_B
 SG_ BCMRE_Climate_FrontByPassAirMode : 31|8@0+ (1,0) [0|100] "%"  CVC_B
 SG_ BCMRE_Climate_RearFootAirMode_Fl : 39|8@0+ (1,0) [0|100] "%"  CVC_B
 SG_ BCMRE_Climate_RLTemp_FlapPos : 71|8@0+ (1,0) [0|100] "%"  CVC_B
 SG_ BCMRE_Climate_RRTemp_FlapPos : 79|8@0+ (1,0) [0|100] "%"  CVC_B
 SG_ BCMRE_Climate_FrontPassAirMode_S : 63|1@0+ (1,0) [0|1] ""  CVC_B
 SG_ BCMRE_Climate_FrontByPassAi_0000 : 59|1@0+ (1,0) [0|1] ""  CVC_B
 SG_ BCMRE_Climate_RearFootAirMode_St : 58|1@0+ (1,0) [0|1] ""  CVC_B
 SG_ BCMRE_Climate_RLTemp_Sts : 57|1@0+ (1,0) [0|1] ""  CVC_B
 SG_ BCMRE_Climate_RRTemp_Sts : 56|1@0+ (1,0) [0|1] ""  CVC_B
 SG_ BCMRE_Climate_RearBlowerRelay_St : 81|2@0+ (1,0) [0|3] ""  CVC_B
 SG_ BCMRE_Climate_AirDistFlapRHPos : 95|8@0+ (1,0) [0|100] "%"  CVC_B
 SG_ BCMRE_Climate_AirDistFlapRHSts : 87|1@0+ (1,0) [0|1] ""  CVC_B
 SG_ BCMRE_Climate_BypassFlap : 103|8@0+ (1,0) [0|100] "%"  CVC_B
 SG_ BCMRE_Climate_BypassFlapSts : 86|1@0+ (1,0) [0|1] ""  CVC_B
 SG_ BCMRE_Climate_AirDistRearFlapPos : 111|8@0+ (1,0) [0|100] "%"  CVC_B
 SG_ BCMRE_Climate_AirDistRearFlapSts : 85|1@0+ (1,0) [0|1] ""  CVC_B
 SG_ BCMRE_Climate_RearDuctFlapPos : 119|7@0+ (1,0) [0|100] "%"  CVC_B
 SG_ BCMRE_Climate_RearDuctFlapSts : 112|1@0+ (1,0) [0|1] ""  CVC_B

BO_ 172 BCMRE_DoorStatus: 8 BCM_R
 SG_ CRC_BCMRE_DoorStatus : 7|8@0+ (1,0) [0|255] ""  CVC_B,DKCU
 SG_ ALIVE_BCMRE_DoorStatus : 11|4@0+ (1,0) [0|15] ""  CVC_B,DKCU
 SG_ TailgateAjarStatus : 17|2@0+ (1,0) [0|3] ""  CVC_B,DKCU
 SG_ TailgateLockStatus : 19|2@0+ (1,0) [0|3] ""  CVC_B,DKCU
 SG_ Fuel_Port_Lock_Status : 21|2@0+ (1,0) [0|3] ""  CVC_B,DKCU
 SG_ Fuel_Port_Ajar_Status : 23|2@0+ (1,0) [0|3] ""  CVC_B,DKCU

BO_ 179 ETG_Entry_Control: 8 BCM_R
 SG_ Tailgate_Malfunction : 0|1@0+ (1,0) [0|1] ""  CVC_B,DKCU
 SG_ TailgateIntButton_Request : 2|2@0+ (1,0) [0|2] ""  CVC_B,DKCU
 SG_ AntiPinch_Operation : 3|1@0+ (1,0) [0|1] ""  CVC_B,DKCU

BO_ 188 BCM_RE_PassiveEntryRequest: 8 BCM_R
 SG_ DoorPassiveEntry_Request : 1|2@0+ (1,0) [0|3] ""  CVC_B
 SG_ TailgatePassiveEntry_Request : 3|2@0+ (1,0) [0|3] ""  CVC_B

CM_ SG_ 267 ALIVE_TRM_LIGHT "Alive counter rolling counter of the message if it's over 14 then will swap back to 0 and increase again. Invalid Value = F";
CM_ SG_ 267 TrailerInput "Trailer synchronization confirmation with HW/SW";
CM_ SG_ 267 TrailerSystemError "Trailer error detection";
CM_ SG_ 267 TRM_VoltageStatus "Trailer voltage status";
CM_ SG_ 267 TRM_STAT_BrakeLight "Trailer Brake light status";
CM_ SG_ 267 TRM_STAT_FogLampRear "Trailer Rear fog lamp status";
CM_ SG_ 267 TRM_STAT_PositionLight "Trailer Position light status";
CM_ SG_ 267 TRM_STAT_TurnIndicators "Trailer Turn Indicatiors status";
CM_ SG_ 267 TRM_STAT_ReverseLight "Trailer Reverse light status";
CM_ SG_ 267 TRM_STAT_HWBrakeLightInput "Trailer hardwired Brake light inputstatus";
CM_ SG_ 267 TRM_STAT_HWIndicatorInput "Trailer hardwired Turn Indicatiors input status";
CM_ SG_ 267 TRM_STAT_HWPosLightInput "Trailer hardwired Position light input status";
CM_ SG_ 274 CRC_CVC_CLAMP_STAT "Checksum";
CM_ SG_ 274 ALIVE_CVC_CLAMP_STAT "Alive counter";
CM_ SG_ 274 RemoteFunctionState "0x1(remote function) will be sent after PreRemoteStart=0x1 first time in ignition OFF state, and this signal will be kept 0x1 until SESAM exit remote state.";
CM_ SG_ 274 CVC_STAT_BLS "Signal represent plausibility of both HW Inputs for brake light switch.";
CM_ SG_ 274 Vehicle_Operation_State "Represent the status of physical terminal";
CM_ SG_ 278 CVC_CL30s_Timer "The signal timer indicate the minimum time the vehicle turning off CL30s in OFF state";
CM_ SG_ 278 ACC_Idle_Timer "The Idle timer signal to the CAN indicating the time vehicle back to OFF state from ACC state in normal state";
CM_ SG_ 278 On_Idle_Timer "The Driver Ideal Timer signal to the CAN indicating the time vehicle back to OFF state from ON";
CM_ SG_ 278 ON_LowSOC_SaveMode_Timer "The Save mode ON timer signal to the CAN indicating the time vehicle back to ACC state from ON state in Transport mode or Low SOC state";
CM_ SG_ 278 ACC_LowSOC_SaveMode_Timer "The Save mode ACC timer signal to the CAN indicating the time vehicle back to ACC state from ON state in Transport mode or Low SOC state";
CM_ SG_ 278 Charging_Display_Timer "Full screen charging display timer";
CM_ SG_ 278 OTA_Idle_Timer "The OTA Ideal Timer signal to the CAN indicating the time vehicle back to OFF state from ON";
CM_ SG_ 284 TBOX_FOTA_STAT_TerminalReq "CAR state switching request for FOTA";
CM_ SG_ 307 CRC_SRR_RR_BSD_RCTA_DOW "Checksum";
CM_ SG_ 307 ALIVE_SRR_RR_BSD_RCTA_DOW "Alive Counter";
CM_ SG_ 307 SRR_RR_BSD_check "Blind Sport Detection Check";
CM_ SG_ 307 SRR_RR_BSD_state "Blind Sport Detection State Feedback";
CM_ SG_ 307 SRR_RR_BSD_AudChime_Feed "Blind Sport Detection Audible Chime Feedback";
CM_ SG_ 307 SRR_RR_BSD_IndLeft "Left Blind Sport Detection Warning";
CM_ SG_ 307 SRR_RR_BSD_IndRight "Right Blind Sport Detection Warning";
CM_ SG_ 307 SRR_RR_BSD_SndWarn "Rear Blind Sport Detection warning sound en disable";
CM_ SG_ 307 SRR_RR_BSD_Mode_Feed "Blind Sport Detection On Off Feedback";
CM_ SG_ 307 SRR_RR_BSD_sens_Feed "Blind Sport Detection sensitivity Feedback";
CM_ SG_ 307 SRR_RR_RCTA_IndRight "Right Rear Cross Traffic Alert (RCTA) System Warning";
CM_ SG_ 307 SRR_RR_RCTA_IndLeft "Left Rear Cross Traffic Alert (RCTA) System Warning";
CM_ SG_ 307 SRR_RR_RCTA_sens_Feed "Rear Cross Traffic Alert  Warning Sensitivity Feedback";
CM_ SG_ 307 SRR_RR_RCTA_state "Rear Cross Traffic Alert  Warning State";
CM_ SG_ 307 SRR_RR_RCTA_SndWarn "Rear Cross Traffic Alert warning sound en disable";
CM_ SG_ 307 SRR_RR_RCTA_Mode_Feed "Rear Cross Traffic Alert  Warning On Off Feedback";
CM_ SG_ 307 SRR_RR_RCTA_check "Rear Cross Traffic Alert Check";
CM_ SG_ 307 SRR_RR_DOW_SndWarn "Door Open Sound Warning en disable";
CM_ SG_ 307 SRR_RR_DOW_WarnRight "Right Door Open Warning";
CM_ SG_ 307 SRR_RR_DOW_WarnLeft "Left Door Open Warning";
CM_ SG_ 307 SRR_RR_DOW_check "Door Opening Warning Check";
CM_ SG_ 307 SRR_RR_DOW_state "Door Open Warning State";
CM_ SG_ 307 SRR_RR_DOW_Mode_Feed "Door Open Warning Mode select Feedback";
CM_ SG_ 307 SRR_RR_Right_block "Rear Right Radar Blockage state";
CM_ SG_ 307 SRR_RR_Left_block "Rear Left Radar Blockage state";
CM_ SG_ 307 Obj_ID_RL "This target ID";
CM_ SG_ 307 Obj_Class_RL "Estimated type of object";
CM_ SG_ 307 Obj_OrientationAngle_RL "azimuth";
CM_ SG_ 307 Obj_DistLong_RL "This ID target is a decomposition of the distance from the radar in the x-direction.";
CM_ SG_ 307 Obj_DislLat_RL "Distance decomposition of this ID target from the radar in the y-direction.";
CM_ SG_ 307 Obj_VrelLong_RL "This ID target distance radar x-direction velocity decomposition quantity";
CM_ SG_ 307 Obj_VrelLat_RL "This ID target distance from the radar y-direction velocity decomposition quantity";
CM_ SG_ 307 Obj_ID_RR "This target ID";
CM_ SG_ 307 Obj_Class_RR "Estimated type of object";
CM_ SG_ 307 Obj_OrientationAngle_RR "azimuth";
CM_ SG_ 307 Obj_DistLong_RR "This ID target is a decomposition of the distance from the radar in the x-direction.";
CM_ SG_ 307 Obj_DislLat_RR "Distance decomposition of this ID target from the radar in the y-direction.";
CM_ SG_ 307 Obj_VrelLong_RR "This ID target distance radar x-direction velocity decomposition quantity";
CM_ SG_ 307 Obj_VrelLat_RR "This ID target distance from the radar y-direction velocity decomposition quantity";
CM_ SG_ 307 SRR_RR_RCTB_Mode_Feed "Intersection Assist State  Mode select";
CM_ SG_ 307 SRR_RR_RCTB_State "Intersection Assist State";
CM_ SG_ 307 SRR_RR_RCTB_Check "Intersection Assist State Check";
CM_ SG_ 307 SRR_RR_RCTB_Braking_Flag "RCTB brake request flag";
CM_ SG_ 307 SRR_RR_RCTB_Braking_Deceleration "RCTB brake request deceleration";
CM_ SG_ 307 SRR_RR_CollisionObjID "Rear radar collision object";
CM_ SG_ 382 CRC_EPS_SAS_Sensor "Checksum";
CM_ SG_ 382 ALIVE_EPS_SAS_Sensor "Alive Counter";
CM_ SG_ 382 SAS_SASStsSnsr "The flag of  SAS status Punch Steering angle status";
CM_ SG_ 382 SAS_SteerWhlRotSpd "The current rotation speed of the steering wheel.";
CM_ SG_ 382 SAS_SteerWhlRotSpdStatus "The status of SteerWheelRotSpd";
CM_ SG_ 382 SAS_SASFailure "Angle sensor disabled.";
CM_ SG_ 382 SAS_Calibrated "SAS calibration state";
CM_ SG_ 382 SAS_SteerWheelAngleValid "Effective signal for steering angle";
CM_ SG_ 382 SAS_SteerWheelAngle "The current angle of the steering wheel(Positive, to left Negative, to right)";
CM_ SG_ 519 SR_Undervoltage_Fault_Sts "Sunroof under voltage status";
CM_ SG_ 519 SR_Overvoltage_Fault_Sts "Sunroof over voltage";
CM_ SG_ 519 SR_SLEEP_RQ "Sunroof sleep request";
CM_ SG_ 519 SR_Position "Sunroof position";
CM_ SG_ 519 SR_Motor_Running_Sts "Sunroof motor running status";
CM_ SG_ 519 SR_MotorReverse_Fault_Sts "Sunroof motor reverse status";
CM_ SG_ 519 SR_Hall_Fault_Sts "SR Hall Fault Sts";
CM_ SG_ 519 SR_Normalisation_Sts "SR Normalisation Sts";
CM_ SG_ 519 SR_Relay_Fault "SR Relay Fault";
CM_ SG_ 519 SR_Commu_Fault_Sts "Sunroof comminication status";
CM_ SG_ 519 SR_Initialisation_Status "SR_Initialisation_Status";
CM_ SG_ 519 SR_Ctrl_Result "Sunroof control result";
CM_ SG_ 519 SR_ThermalProtection_Fault_Sts "Sunroof thermal protection status";
CM_ SG_ 519 SR_Posit_Percentage "Sunroof position in percentage";
CM_ SG_ 519 SR_Operation_Stat "Sunroof operating state";
CM_ SG_ 519 SR_Error_RSP "Sunroof error";
CM_ SG_ 519 BCM_AutoSunroof_Sts "Auto Sunroof setting feedback";
CM_ SG_ 524 CRC_CVC_ODO "Checksum";
CM_ SG_ 524 ALIVE_CVC_ODO "Alive Counter";
CM_ SG_ 524 CVC_Odometer "Odometer information.";
CM_ SG_ 524 CVC_OdometerV "Validity of odometer information";
CM_ BO_ 525 "WCBS status";
CM_ SG_ 525 CRC_WCBS_STATUS "Checksum";
CM_ SG_ 525 ALIVE_WCBS_STATUS "Alive counter";
CM_ SG_ 525 ABSFailed "ABS Fault Status";
CM_ SG_ 525 ABSActive "Further details when which bit will be set are defined within attached Excel file: Functions_Interventions File is at the moment under review at Bosch WCBS side";
CM_ SG_ 525 WCBS_VehicleSpeed "Vehicle Speed";
CM_ SG_ 525 ESC_VehicleStandstill "Vehicle stationary detected";
CM_ SG_ 525 WCBS_VehicleSpeedValid "Vehicle Speed Status";
CM_ SG_ 525 ESC_VehicleHoldStat "Set if vehicle stationary for ACC is detected";
CM_ SG_ 525 ABS_EBDFailed "Signal from ABS/ABS to indicate EBD failure for driver";
CM_ SG_ 525 ABS_HAZActive "Emergency Stop Active";
CM_ SG_ 525 ABS_LowBrakeFluid "Detect the brake fluid level";
CM_ SG_ 525 EBDActive "Signal from ABS/ABS to indicate if EBD is activate or not";
CM_ SG_ 525 WCBS_Mileage "Mileage in cm";
CM_ SG_ 525 WCBS_Veh_DriveCondition "Driving Condition";
CM_ SG_ 533 CRC_BMS_Sts "Checksum";
CM_ SG_ 533 ALIVE_BMS_Sts "Rolling Counter";
CM_ SG_ 533 BMS_BatBalance_ERR "Battery Balance Error indicates Balancing switch is short or open";
CM_ SG_ 533 BMS_Balance_STS "BMS Balance Status";
CM_ SG_ 533 BMS_IGN_Sts "the ignition signal status (on/off)";
CM_ SG_ 533 BMS_HWCrash_Sts "Battery Pack Hardware Crash signal Status";
CM_ SG_ 533 BMS_HVIL_STS "The HVIL state of BMS";
CM_ SG_ 533 BMS_HVOnOff_STS "Status of the High Voltage";
CM_ SG_ 533 BMS_ERR_LEV "BMS requesting CVC to operate at the limited operating strategy (LOS)";
CM_ SG_ 533 BMS_SocActual_EST "Actual SOC";
CM_ SG_ 533 BMS_Sys_STS "BMS_Status(Self-test after BMS wake-up) BMS CVC";
CM_ SG_ 533 BMS_ISU_Status "Pack Insulation Status";
CM_ SG_ 533 BMS_SOH "BMS State Of Health";
CM_ SG_ 533 BMS_SOE "BMS State Of Enegy";
CM_ SG_ 533 BMS_HV_Sts "HV Status";
CM_ SG_ 533 BMS_Display_SOC "Display SOC";
CM_ SG_ 533 BMS_SOCE "State of certified energy";
CM_ SG_ 536 CVC_PosLight_RR_Req "Request RR position light";
CM_ SG_ 536 CVC_RearFogLamp_RL_Req "Request to control rear fog lamp Left";
CM_ SG_ 536 CVC_RearFogLamp_RR_Req "Request to control rear fog lamp Right";
CM_ SG_ 536 CVC_DaytimeRunningLight_FL_Req "Request to control FL DRL";
CM_ SG_ 536 CVC_DaytimeRunningLight_FR_Req "Request to control FR DRL";
CM_ SG_ 536 CVC_TurnIndicator_FL_Req "Request to control FL indicator";
CM_ SG_ 536 CVC_TurnIndicator_RL_Req "Request to control RL indicator";
CM_ SG_ 536 CVC_TurnIndicator_FR_Req "Request to control FR indicator";
CM_ SG_ 536 CVC_TurnIndicator_RR_Req "Request to control RR indicator";
CM_ SG_ 536 CVC_RLS_AutoLampRequest "Request automatic lighting control";
CM_ SG_ 536 CVC_ReverseLamp_RL_Req "Request left reverse lamp";
CM_ SG_ 536 CVC_ReverseLamp_RR_Req "Request right reverse lamp";
CM_ SG_ 536 CVC_BrakeLight_RL_Req "Request to control left brake light";
CM_ SG_ 536 CVC_BrakeLight_RR_Req "Request to control right brake light";
CM_ SG_ 536 CVC_BrakeLight_Center_Req "Request to control center mounting brake light";
CM_ SG_ 536 CVC_LicensePlateLamp_RE_Req "Request to control license plate lamp";
CM_ SG_ 536 CVC_HighBeam_FL_Req "Request to control FL HB";
CM_ SG_ 536 CVC_HighBeam_FR_Req "Request to control FR HB";
CM_ SG_ 536 CVC_LowBeam_FL_Req "Request to control Front-left LB";
CM_ SG_ 536 CVC_LowBeam_FR_Req "Request to control Front-right LB";
CM_ SG_ 536 CVC_PosLight_RL_Req "Request RL position light";
CM_ SG_ 536 CVC_MirrorLED_FL_Req "Request left front and rear mirror LED";
CM_ SG_ 536 CVC_MirrorLED_FR_Req "Request right front and rear mirror LED";
CM_ SG_ 536 CVC_SignatureLight_RE_Req "Rear right feature light request";
CM_ SG_ 536 CVC_PosLight_FR_Req "Request FR position light";
CM_ SG_ 536 CVC_PosLight_FL_Req "Request FL position light";
CM_ SG_ 536 CVC_FrontFogLamp_FR_Req "Request to control Front fog lamp Right";
CM_ SG_ 536 CVC_FrontFogLamp_FL_Req "Request to control Front fog lamp Left";
CM_ SG_ 536 CVC_IndicatorMode_Req "Request to control the working mode of vehicle indicator lights";
CM_ SG_ 536 CVC_ParkLight_RL_Req "Request RL Park light";
CM_ SG_ 536 CVC_ParkLight_RR_Req "Request RR Park light";
CM_ SG_ 536 CVC_ParkLight_RM_Req "Request RM Park light";
CM_ SG_ 536 CVC_PosLight_RM_Req "Request RM Position light";
CM_ SG_ 539 CVC_Mirror_CourtesyLightReq "Left front door welcome light control request";
CM_ SG_ 539 CVC_CargoLightReq "Control request for trunk lighting";
CM_ SG_ 539 CVC_BonnetLightReq "Engine compartment lighting control request";
CM_ SG_ 539 CVC_FLFootwellLightReq "Left front foot lighting control request";
CM_ SG_ 539 CVC_FRFootwellLightReq "Right front foot lighting requirement";
CM_ SG_ 539 CVC_FrontDomeLampReq "Front interior ceiling light control request";
CM_ SG_ 539 CVC_Rear_2nd_DomeLampReq "Rear interior ceiling light control request";
CM_ SG_ 539 CVC_SwitchLightBrightnessSet "Request for brightness setting of switch lights";
CM_ SG_ 539 CVC_FLScuffLightReq "Left front door sill decorative light control request";
CM_ SG_ 539 CVC_FRScuffLightReq "Right front door sill decorative light control request";
CM_ SG_ 539 CVC_FLProjectorLightReq "Left front projection lamp control request";
CM_ SG_ 539 CVC_RLProjectorLightReq "Left rear projection lamp control request";
CM_ SG_ 539 CVC_RRProjectorLightReq "Right rear projection lamp control request";
CM_ SG_ 539 CVC_FRProjectorLightReq "Right front projection lamp control request";
CM_ SG_ 541 CVC_AHL_PitchAng "AHL pitch angle";
CM_ SG_ 541 CVC_AHL_Mode "Working mode of AHL";
CM_ SG_ 541 CVC_AHL_STS "Feedback setting status of AHL function";
CM_ SG_ 541 CVC_AHL_TargetPos_FL "Target motor position of front left headlight";
CM_ SG_ 541 CVC_AHL_TargetPos_FR "Target motor position of front right headlight";
CM_ SG_ 542 CVC_RearFogLampSts "Setting feedback to CAN of rear fog light";
CM_ SG_ 542 CVC_ExteriorLightSts "Request exterior light system to change to the mode set from user";
CM_ SG_ 542 CVC_FollowMeHomeSts "Feedback FMH setting status";
CM_ SG_ 542 CVC_WelcomeLightSts "Feedback Welcome light setitng status";
CM_ SG_ 542 CVC_FrontFogLampSts "Setting feedback to CAN of Front Fog lamp";
CM_ SG_ 565 CRC_TRM_STATUS "Checksum";
CM_ SG_ 565 ALIVE_TRM_STATUS "Alive counter";
CM_ SG_ 565 TRM_TowingDetected "Towing status ( reserved )";
CM_ SG_ 565 TRM_TrailerDetected "Trailer Detected status";
CM_ SG_ 592 CRC_BMS_CVC_THMReq "Check sum";
CM_ SG_ 592 ALIVE_BMS_CVC_THMReq "Alive counter";
CM_ SG_ 592 BMS_FlowRate_Req "Flow rate required";
CM_ SG_ 592 BMS_CoolPwrDemand "requesting the cooling power required fro the battery pack";
CM_ SG_ 592 BMS_HeatPwrDemand "requesting the heating power required fro the battery pack";
CM_ SG_ 592 BMS_CVC_PTCOnOff_Req "PTC Heater turn on and off request";
CM_ SG_ 592 BMS_CVC_ValveOnOff_Req "requesting CVC to turn on and off the valve";
CM_ SG_ 592 BMS_PreHeatCoolReq "Battery pack precondition information";
CM_ SG_ 592 BMS_InletTemp_Req "Target water inlet temperature request";
CM_ SG_ 619 Sig_TgtVer_LR "AVAC Target Position Request";
CM_ SG_ 619 Sig_SPVer_L "AVAC Target Position Request";
CM_ SG_ 619 Sig_SPVer_R "AVAC Target Position Request";
CM_ SG_ 619 Sig_RefVer_LR "AVAC Target Position Request";
CM_ SG_ 662 POD_DCDC_InputHV "Input Voltage";
CM_ SG_ 662 PDU_DCDC_StsCtrl "DCDC Control Status to CVC";
CM_ SG_ 662 PDU_DCDC_OutputCurrent "Output Current";
CM_ SG_ 662 PDU_DCDC_OutputVolt "Output Voltage";
CM_ SG_ 676 LV_ConsecutiveTopUpCancelCnt "The counter tracks consecutive cancellations of top-up attempts";
CM_ SG_ 676 CVC_B_ESCOFF_SW_Sts "ESC Off Switch Status";
CM_ SG_ 676 CVC_B_CVC_CreepDisable_stt "Request for CVC to disable creep function";
CM_ SG_ 676 CVC_B_AVH_Req "AVH request";
CM_ SG_ 676 CVC_B_RegencyLevRequest "Switch of Regen Level on CVC_B";
CM_ SG_ 676 CVC_B_DM_SwitchModeSts "Switch of drive mode  on CVC_B";
CM_ SG_ 676 CVC_LV_Batt_Charging_Req "CVC LV Charging Request";
CM_ SG_ 676 CVC_B_Trailermode_Req "Dragmode request";
CM_ SG_ 746 InteriorTemperature "Interior Temprature value from LIN";
CM_ SG_ 746 CVC_SW_Versions "CVC software version";
CM_ SG_ 746 CVC_Fan_Sts "CVC control fan status";
CM_ SG_ 746 CVC_DCChgPosTemp "The Positive Temperature of DC Charging";
CM_ SG_ 746 CVC_DCChgNegTemp "The Negative Temperature of DC Charging";
CM_ SG_ 746 CVC_ACChgLTerminalTemp "Temperature of AC Charging L terminal";
CM_ SG_ 746 CVC_ACChgNTerminalTemp_Reserve "Temperature of AC Charging  N terminal_Reserve";
CM_ SG_ 746 CVC_EdrivePump_Sts "Electric drive water pump working status";
CM_ SG_ 746 CVC_BatPump_Sts "Battery water pump working status";
CM_ SG_ 746 CVC_ActiveHeatingPower "Active heating power for PTC in battery pre-heat for debugging";
CM_ SG_ 760 DISP_HR "The signal / parameter indicates the current hour.";
CM_ SG_ 760 DISP_MN "The signal / parameter indicates the current minute.";
CM_ SG_ 760 DISP_SEC "The signal / parameter indicates the current second.";
CM_ SG_ 760 DISP_DATE_DAY "The signal / parameter indicates the current day.";
CM_ SG_ 760 DISP_DATE_MON "The signal / parameter indicates the current month.";
CM_ SG_ 760 DISP_DATE_WDAY "The signal   parameter indicates the current day of the week.";
CM_ SG_ 760 DISP_DATE_YR "The signal / parameter indicates the current year.";
CM_ SG_ 760 ST_DISP_CTI_DATE "The signal / parameter indicates the state of the switch summer winter time.";
CM_ SG_ 768 CVC_STAT_SyncClimateZone "Status dual clima automatic";
CM_ SG_ 768 CVC_STAT_Auto "Status activation of auto mode";
CM_ SG_ 768 CVC_STAT_Aircondition "Aircondition status";
CM_ SG_ 768 CVC_STAT_IonButton "Status if the ionisator is active";
CM_ SG_ 768 CVC_STAT_MaxAc "Status activation of MAX AC mode";
CM_ SG_ 768 CVC_STAT_ClimateOnOff "Status On  Off button for clima";
CM_ SG_ 768 CVC_STAT_FanSpeed "Blower settings/Fan Speed for climate system";
CM_ SG_ 768 CVC_STAT_RecircFlap "Recirculation flap status, 100% fresh air, 0% recirculation mode";
CM_ SG_ 768 CVC_STAT_AirDistributionMode "Request for flap position";
CM_ SG_ 768 CVC_STAT_Defrost "Status activation of Defrost mode";
CM_ SG_ 768 CVC_STAT_PTC_Heater "CVC status for PTC heater";
CM_ SG_ 768 CVC_STAT_TempDriver "CVC status for temperature regulationr driver (Display Temperature)";
CM_ SG_ 768 CVC_STAT_TempPassenger "CVC status for temperature regulation  passenger(Display Temperature)";
CM_ SG_ 768 CVC_CoolSysWarnLvl "Cooling system warning level";
CM_ SG_ 773 HtrMediumOutletTemp "Heater medium outlet temperature (Purpose for PTC) Only BEV car";
CM_ SG_ 773 CcuHtrOnOffSts "PTC status from CVC  Only BEV car";
CM_ SG_ 773 EcompOnOffSts "Electrical compressor on/off status  Only BEV car";
CM_ SG_ 773 HtrMediumInletTemp "Heater medium inlet temperature (Purpose for PTC) Only BEV car";
CM_ SG_ 773 ECompRpm "E-compressor actual RPM  Only BEV car";
CM_ SG_ 773 ECompPowerConsumption "E-compressor actual power consumption  Only BEV car";
CM_ SG_ 775 CRC_CPD_OUTPUT "This signal is used for E2E protection.";
CM_ SG_ 775 ALIVE_CPD_OUTPUT "Alive counter required by AUTOSAR E2E protection.";
CM_ SG_ 775 OUT_Alert_TO_BCM "This signal is used to trigger warning on BCM";
CM_ SG_ 775 CPD_State_information "This signal is used to send state of CPD (enable/disable) to CVC_B";
CM_ SG_ 775 OUT_Alert_TO_MHU "This signal is used to trigger warning on CVC_B";
CM_ SG_ 775 CPD_Occupancy_Status "CPD occupancy status.";
CM_ SG_ 775 CPD_Init_Warning_Delay "Initial warning delay time for CPD";
CM_ SG_ 775 CPD_Temp_Warn_Delay_Sts "CPD temporary warning delayed status";
CM_ SG_ 775 CPD_OccupancyAlert "CPD occupancy alarm";
CM_ SG_ 775 CPD_Warn_Cancel_Sts "CPD warning cancellation status";
CM_ SG_ 776 MHU_SET_CPD_InitWarnDelay "Delay time for setting the first warning signal";
CM_ SG_ 776 MHU_SET_CPD_TempWarnDelay "Temporary warning delay setting";
CM_ SG_ 776 MHU_DKCU_CPD_Warn_Cancel "Warning signal cancellation setting";
CM_ SG_ 777 CPD_Warn_Initial_Start "CPD initial warning begins";
CM_ SG_ 777 CPD_Warn_Initial_End "CPD initial warning ends";
CM_ SG_ 777 CPD_Warn_Escalated_Start "CPD upgrade warning begins";
CM_ SG_ 777 CPD_Warn_Escalated_End "CPD upgrade warning ends";
CM_ SG_ 777 CVC_DKCU_CPD_Warn_Cancel "CPD warning cancelled";
CM_ SG_ 778 CVC_DKCU_PhoneLocationReq "CVC request to DKCU for Device presence confirmation";
CM_ SG_ 779 CVC_DKCU_Temp_Intervention_Fdbk "CVC received intervention message and started notifying BCM to start the in car air conditioning system";
CM_ SG_ 779 CVC_DKCU_Remote_Phone_Interventi "CVC received an intervention message and began to execute the phone system dialing actionCVC";
CM_ SG_ 862 CRC_CVC_Vehicle_info "Checksum";
CM_ SG_ 862 ALIVE_CVC_Vehicle_info "Alive counter";
CM_ SG_ 862 CVC_VehLock_STS "Vehicle Lock Status";
CM_ SG_ 862 CVC_VehSpd_ScreenDisplay "Indicate the display speed on HMI screen calculated according";
CM_ SG_ 862 CVC_VehChgAllow "Indicate the request to allow the vehicle to start charging";
CM_ SG_ 862 CVC_VehDischgAllow "Indicate the request to allow the vehicle to start discharging";
CM_ SG_ 862 Re_InitCharging_Req "Request re-initiate charging";
CM_ SG_ 892 CRC_EVCC_Charging_Sts "Checksum";
CM_ SG_ 892 ALIVE_EVCC_Charging_Sts "Alive counter";
CM_ SG_ 892 EVCC_ChgGun_Sts "Indicate the status of the charge gun: whether it is connected, removed, or if there is an error.";
CM_ SG_ 892 EVCC_ChgFlap_Sts "Indicate the status of the charge flap: whether it is opened, closed and locked or released.";
CM_ SG_ 892 EVCC_ChgType "Indicate the charging type for the charging session. The charging type is detected via the PWM value of the CP pin and the message pair ServiceDiscovery during PLC communication";
CM_ SG_ 892 EVCC_VehChg_Sts "Indicate the charging status.";
CM_ SG_ 892 EVCC_ChgAuthen_Sts "Indicate the authentication status of charging session, whether the vehicle and the EVSE is compatible or not.";
CM_ SG_ 892 EVCC_PaymentType "Description Indicate the payment type for the charging session";
CM_ SG_ 892 EVCC_VehChgCompError_Sts "Indicate the error status of the charging components from the vehicle.";
CM_ SG_ 892 EVCC_ProximityPilot_Voltage "Indicate the measure voltage of Proximity pilot (PP) pin";
CM_ SG_ 892 EVCC_S3Button_Sts "S3 button state";
CM_ SG_ 897 CRC_ACU_OCCUPANT_STATUS "Checksum";
CM_ SG_ 897 ALIVE_ACU_OCCUPANT_STATUS "Alive Counter";
CM_ SG_ 897 ACU_Seat_Occupancy_Passenger "Passenger seat occupancy status";
CM_ SG_ 897 ACU_Seat_Occupancy_2nd_Row_Dri "The occupancy status of the driver's side seat in the second row";
CM_ SG_ 897 ACU_Seat_Occupancy_2nd_Row_Pas "The occupancy status of the second row passenger side seat";
CM_ SG_ 897 ACU_Seat_Occupancy_2nd_Row_Mid "The occupancy status of the middle seat in the second row";
CM_ SG_ 897 ACU_Seat_Belt_Status_Passenger "The status of passenger seat belts";
CM_ SG_ 897 ACU_Seat_Belt_Status_Driver "The status of the driver's seat belt";
CM_ SG_ 897 ACU_Seat_Belt_Status_2nd_Row_Dri "The status of the driver's side seat belt in the second row";
CM_ SG_ 897 ACU_Seat_Belt_Status_2nd_Row_Mid "The status of the second row middle seat belt";
CM_ SG_ 897 ACU_Seat_Belt_Status_2nd_Row_Pas "The status of the second row passenger side seat belt";
CM_ SG_ 897 ACU_Seat_Occupancy_Driver "Driver seat occupancy status";
CM_ SG_ 899 CVC_VIN_Byte1 "This signal contains the seventh last digit of the chassis number. (The individual digits are encoded in ASCII characters.)";
CM_ SG_ 899 CVC_VIN_Byte2 "This signal contains the sixth last digit of the chassis number. (The individual digits are encoded in ASCII characters.)";
CM_ SG_ 899 CVC_VIN_Byte3 "This signal contains the fifth last digit of the chassis number. (The individual digits are encoded in ASCII characters.)";
CM_ SG_ 899 CVC_VIN_Byte4 "This signal contains the fourth last digit of the chassis number. (The individual digits are encoded in ASCII characters.)";
CM_ SG_ 899 CVC_VIN_Byte5 "This signal contains the third last digit of the chassis number. (The individual digits are encoded in ASCII characters.)";
CM_ SG_ 899 CVC_VIN_Byte6 "This signal contains the penultimate digit of the chassis number. (The individual digits are encoded in ASCII characters.)";
CM_ SG_ 899 CVC_VIN_Byte7 "This signal contains the last digit of the chassis number. (The individual digits are encoded in ASCII characters.)";
CM_ SG_ 905 CVC_IMMO_Sts "IMMO status";
CM_ SG_ 921 CVC_Immo_Byte_0 "CVC Authentication signal byte 0";
CM_ SG_ 921 CVC_Immo_Byte_1 "CVC Authentication signal byte 1";
CM_ SG_ 921 CVC_Immo_Byte_2 "CVC Authentication signal byte 2";
CM_ SG_ 921 CVC_Immo_Byte_3 "CVC Authentication signal byte 3";
CM_ SG_ 921 CVC_Immo_Byte_4 "CVC Authentication signal byte 4";
CM_ SG_ 921 CVC_Immo_Byte_5 "CVC Authentication signal byte 5";
CM_ SG_ 921 CVC_Immo_Byte_6 "CVC Authentication signal byte 6";
CM_ SG_ 921 CVC_Immo_Byte_7 "CVC Authentication signal byte 7";
CM_ SG_ 922 CVC_B_Immo_Byte_0 "CVC_B Authentication signal byte 0";
CM_ SG_ 922 CVC_B_Immo_Byte_1 "CVC_B Authentication signal byte 1";
CM_ SG_ 922 CVC_B_Immo_Byte_2 "CVC_B Authentication signal byte 2";
CM_ SG_ 922 CVC_B_Immo_Byte_3 "CVC_B Authentication signal byte 3";
CM_ SG_ 922 CVC_B_Immo_Byte_4 "CVC_B Authentication signal byte 4";
CM_ SG_ 922 CVC_B_Immo_Byte_5 "CVC_B Authentication signal byte 5";
CM_ SG_ 922 CVC_B_Immo_Byte_6 "CVC_B Authentication signal byte 6";
CM_ SG_ 922 CVC_B_Immo_Byte_7 "CVC_B Authentication signal byte 7";
CM_ SG_ 925 CRC_CVC_AHB_Sts "Checksum";
CM_ SG_ 925 ALIVE_CVC_AHB_Sts "Alive counter";
CM_ SG_ 925 CVC_ADAS_AHB_Sts "AHB state";
CM_ SG_ 925 CVC_AHB_Override "Automatic High Beam Override by Driver using Stalk lever";
CM_ SG_ 925 CVC_ADAS_AHB_RBPos_Sts "High Beam Position Request Signal staus(Right Ramp)";
CM_ SG_ 925 CVC_ADAS_AHB_LBPos_Sts "High Beam Position Request Signal staus(Left Ramp)";
CM_ SG_ 925 CVC_AHB_Icon_Sts "AHB ICON status";
CM_ SG_ 1009 CVC_AmbientLightIntensityBrightn "CVC AmbientLight Intensity Brightness Request";
CM_ SG_ 1015 MFS_L_Lever_Control "Left steering wheel lever control signal";
CM_ SG_ 1015 MFS_L_LeverButton_Control "Control signal for the left steering wheel lever button";
CM_ SG_ 1015 MFS_L_Failure "Fault signal of left multifunction control module of steering wheel";
CM_ SG_ 1015 MFS_L_UpControl "Left side upward control signal of steering wheel";
CM_ SG_ 1015 MFS_L_DownControl "Left side downward control signal of steering wheel";
CM_ SG_ 1015 MFS_L_LeftControl "Left control signal on the left side of the steering wheel";
CM_ SG_ 1015 MFS_L_RightControl "Left to right control signal of steering wheel";
CM_ SG_ 1015 MFS_LIN_error "LIN bus error signal of steering wheel multifunction module";
CM_ SG_ 1015 MFS_R_Lever_Control "Steering wheel right lever control signal";
CM_ SG_ 1015 MFS_R_LeverButton_Control "Steering wheel right lever button control signal";
CM_ SG_ 1015 MFS_R_Failure "Fault signal of multifunctional control module on the right side of the steering wheel";
CM_ SG_ 1015 MFS_R_UpControl "Control signal for upward movement on the right side of the steering wheel";
CM_ SG_ 1015 MFS_R_DownControl "Right side downward control signal of steering wheel";
CM_ SG_ 1015 MFS_R_LeftControl "Right control signal on the right side of the steering wheel";
CM_ SG_ 1015 MFS_R_RightControl "Right control signal on the right side of the steering wheel";
CM_ SG_ 1015 MFS_Delta_Scroll_Wheel_Left "Steering wheel left wheel operation signal";
CM_ SG_ 1015 MFS_Delta_Scroll_Wheel_Right "Steering wheel right wheel operation signal";
CM_ SG_ 1015 MFS_Scroll_Wheel_Left_Direction "Left wheel rolling direction signal";
CM_ SG_ 1015 MFS_Scroll_Wheel_Right_Direction "Right side roller rolling direction signal";
CM_ SG_ 1015 MFS_Scroll_Wheel_Left_Press "Left wheel pressing signal on steering wheel";
CM_ SG_ 1015 MFS_Scroll_Wheel_Right_Press "Signal for pressing the right wheel of the steering wheel";
CM_ SG_ 1015 MFS_Scroll_Wheel_Left_Valid "Signal indicating the effectiveness of the left wheel operation on the steering wheel";
CM_ SG_ 1015 MFS_Scroll_Wheel_Right_Valid "Signal indicating the effectiveness of the right wheel operation on the steering wheel";
CM_ SG_ 1015 MFS_Scroll_Wheel_Left_ID "Unique identifier for the left wheel of the steering wheel";
CM_ SG_ 1015 MFS_Scroll_Wheel_Right_ID "Unique identifier for the right wheel of the steering wheel";
CM_ SG_ 1017 MHU_SET_PaaK_Enable "Set the enabled status of the phone's key function";
CM_ SG_ 1017 MHU_SET_UserSettingApproachUnloc "Set user proximity unlock";
CM_ SG_ 1017 MHU_SET_UserSettingWalkawayLock "Set user departure lock";
CM_ SG_ 1017 MHU_SET_LockUnlockDriveCfg_Phone "Set up lock/unlock/driving configurations related to mobile phones";
CM_ SG_ 1022 CVC_RearWiperSet "CVC request to turn on/off rear wiper";
CM_ SG_ 1022 CVC_SET_RearWiperServiceMod "CVC request to operate rear wiper as service mode";
CM_ SG_ 1022 CVC_SET_FrontWiperServiceMod "CVC request to operate front wiper as service mode";
CM_ SG_ 1022 CVC_WiperServiceModeSet "CVC request to operate front wiper at service position";
CM_ SG_ 1022 CVC_FrontWiperSpeedSet "CVC set operate speed for front wiper";
CM_ SG_ 1022 CVC_RLS_SensitivityLevelSet "CVC set the RLS sensitivity level";
CM_ SG_ 1022 CVC_FR_RR_WashAndMist_Req "Front and Rear Washer and Mist function control request from CVC to BCM";
CM_ SG_ 1022 CVC_FrontWiperStepTimeSet "CVC set the front wiper time step";
CM_ SG_ 1022 CVC_RearWasherFuildSpayReq "Request turn on/off the duo washer to splay fluid to rear windshield";
CM_ SG_ 1022 CVC_FrontWasherFuildSpayReq "Request turn on/off the duo washer to splay fluid to front windshield";
CM_ SG_ 1026 CVC_B_SET_DayTimeRunningLight "On Off Day Time Running Light";
CM_ SG_ 1026 CVC_B_SET_RearFogLight "On/Off Rear Fog Light";
CM_ SG_ 1026 CVC_B_SET_FrontFogLight "On/Off Front Fog Light";
CM_ SG_ 1026 CVC_B_SET_WelcomeDimmingHeadligh "On/Off Welcome headlight dimming";
CM_ SG_ 1026 CVC_B_SET_AmbientLightBrighness "Change Ambient light brighness percent";
CM_ SG_ 1026 CVC_B_SET_FootwellLightMode "Change Footwell Light mode";
CM_ SG_ 1026 CVC_B_SET_ExteriorLight "Change Exterior light mode";
CM_ SG_ 1026 CVC_B_SET_TRWarningSignals "Turn on/off BCM Thermal runaway warning signals";
CM_ SG_ 1026 CVC_B_SET_FrontDomeLamp "Setting On/Off/Auto Front Dome Lamp";
CM_ SG_ 1026 CVC_B_SET_SwitchLightBrightness "Change Brighness level of Switch illumination";
CM_ SG_ 1026 CVC_B_SET_HazardLight "On/Off HazardLight function";
CM_ SG_ 1026 CVC_B_SET_FollowMeHome "Change follow me home headlamp mode and delay";
CM_ SG_ 1026 CVC_B_SET_ADB_AHB "On/off ADB/AHB function, ADB in ECE version, AHB in SAE version";
CM_ SG_ 1026 CVC_B_SET_Welcome_Farewell_Anima "selection of different welcome/goodbye animations";
CM_ SG_ 1026 CVC_B_SET_ChargingAnimation "De-/Activation of charging animation";
CM_ SG_ 1026 CVC_B_SET_Auto_Leveling "On/Off Auto-Leveling function";
CM_ SG_ 1032 CVC_SET_MirrorAuto "Change mirror auto mode";
CM_ SG_ 1032 CVC_SET_MirrorAutoUnfold "setting Mirror Auto unfold mode";
CM_ SG_ 1032 CVC_SET_WLC "On Off wireless charger";
CM_ SG_ 1032 CVC_SET_AutoRearWiper "On Off Auto rear wiper";
CM_ SG_ 1032 CVC_SET_RearHeatedWindow "On Off Rear window heating";
CM_ SG_ 1032 CVC_TPMSReset "Request reset the TPMS";
CM_ SG_ 1032 CVC_SET_MirrorDefaultSetting "Trigger the default Mirror setting";
CM_ SG_ 1032 CVC_SET_MirrorReverseLink "Mirror Auto Tilt On Reverse Mode";
CM_ SG_ 1032 CVC_SET_AntiTheftMode "setting Anti-theft mode";
CM_ SG_ 1032 CVC_SET_WLCReminder "On Off WLC reminder";
CM_ SG_ 1032 CVC_SET_ClimateKeepOn "Keep power for climate PET/CAMP mode";
CM_ SG_ 1032 CVC_SET_WLC2 "On Off wireless charger rear";
CM_ SG_ 1032 CVC_SET_WLC2Reminder "On Off WLC rear reminder";
CM_ SG_ 1032 CVC_SET_WLC_Phoneforgetalert "On Off Phone forget alert function";
CM_ SG_ 1032 CVC_SteeringWheel_Adjust_Req "CVC_SteeringWheel_Adjust_Req";
CM_ SG_ 1032 CVC_SteeringWheelPosX_Req "CVC_SteeringWheelPosX_Req";
CM_ SG_ 1032 CVC_SteeringWheelPosY_Req "CVC_SteeringWheelPosY_Req";
CM_ SG_ 1033 TBOX_IntrusionAlertStatus "Detection of Intrusion Alert in the CVC_B";
CM_ SG_ 1036 CRC_CVC_B_SEAT_CONTROL "Checksum";
CM_ SG_ 1036 ALIVE_CVC_B_SEAT_CONTROL "Alive Counter";
CM_ SG_ 1036 CVC_B_DrvSeat_Control_Status "CVC_B driver seat control status";
CM_ SG_ 1036 CVC_B_ExpDrvReclinerPos "Expected recliner position of driver seat requested by CVC_B";
CM_ SG_ 1036 CVC_B_ExpDrvTiltPos "Expected tilt position of driver seat requested by CVC_B";
CM_ SG_ 1036 CVC_B_ExpDrvTrackPos "Expected track position of driver seat requested by CVC_B";
CM_ SG_ 1036 CVC_B_ExpDrvHeightPos "Expected height position of driver seat requested by CVC_B";
CM_ SG_ 1050 MHU_SteeringWheel_Telescope "MHU sets the steering wheel telescopic";
CM_ SG_ 1050 MHU_SteeringWheel_EasyEntry "MHU sets the steering wheel for easy access";
CM_ SG_ 1050 MHU_SteeringWheel_Angle "MHU sets steering wheel angle";
CM_ SG_ 1050 MHU_SteeringWheel_Heater "MHU sets steering wheel heating function on/off";
CM_ SG_ 1050 MHU_SteerElecAdj_Req "MHU sets the steering wheel for electric adjustment";
CM_ SG_ 1066 CVC_DriverSeatControl_Req "CVC request BCM_FL to restore seat position";
CM_ SG_ 1066 CVC_FLSeatTrackPos_Req "CVC sends request for Seat track position";
CM_ SG_ 1066 CVC_FLSeatTiltPos_Req "CVC sends request for Seat tilt position";
CM_ SG_ 1066 CVC_FLSeatHeightPos_Req "CVC sends request for Seat height position";
CM_ SG_ 1066 CVC_FLSeatReclinePos_Req "CVC sends request for Recline position";
CM_ SG_ 1066 CVC_FRSeatMassageMode_Set "Front Right Seat Massage Mode setting";
CM_ SG_ 1066 CVC_FLSeatMassageMode_Set "Front Left Seat Massage Mode setting";
CM_ SG_ 1066 CVC_FLSeatMassageLevel_Set "Front left seat massage level set";
CM_ SG_ 1066 CVC_RRSeatMassageMode_Set "Rear Right Seat Massage Mode setting";
CM_ SG_ 1066 CVC_RLSeatMassageMode_Set "Rear Left Seat Massage Mode setting";
CM_ SG_ 1066 CVC_RRSeatMassageLevel_Set "Rear right seat massage level set";
CM_ SG_ 1066 CVC_RLSeatMassageLevel_Set "Rear left seat massage level set";
CM_ SG_ 1066 CVC_FRSeatMassageLevel_Set "Front right seat massage level set";
CM_ SG_ 1074 CRC_CVC_B_FOTA_STATUS "FOTA global status message checksum";
CM_ SG_ 1074 ALIVE_CVC_B_FOTA_STATUS "FOTA global status message alive counter";
CM_ SG_ 1074 CVC_B_FOTA_State "FOTA global status";
CM_ SG_ 1074 CVC_B_FOTA_Error_Code "FOTA Error Code";
CM_ SG_ 1082 CRC_CVC_CVC_B_info "Checksum";
CM_ SG_ 1082 ALIVE_CVC_CVC_B_info "Alive counter";
CM_ SG_ 1082 CVC_BrakeRegenMode "CVC Brake regenerative mode";
CM_ SG_ 1082 CVC_CreepEnable_stt "Feedback for Creep disable request";
CM_ SG_ 1082 CVC_PowerRegenGaugeDisplay "Power Regen gauge display, plus vaue is power level, minus value is regen level.";
CM_ SG_ 1082 CVC_Regen_available "When braking / coasting regeneration system not available or regeneration system capability = 0 or regeneration system = failed.";
CM_ SG_ 1082 CVC_SOC_display "HV battery SOC for displaying only - for CVC strategy";
CM_ SG_ 1082 CVC_Hvbatt_charging_stt "HV battery charging - not charging status,for displaying only ( for both regen/ charging )";
CM_ SG_ 1099 CVC_RLSeatHeating_Set "CVC translate and forward signal seat heating level to BCM_RE";
CM_ SG_ 1099 CVC_FRSeatHeating_Set "CVC translate and forward signal seat heating level to BCM_FR";
CM_ SG_ 1099 CVC_FLSeatHeating_Set "CVC translate and forward signal seat heating level to BCM_FL";
CM_ SG_ 1099 CVC_FRSeatVentilation_Set "CVC translate and forward signal seat Ventilation level to BCM_FR";
CM_ SG_ 1099 CVC_FLSeatVentilation_Set "CVC translate and forward signal seat Ventilation level to BCM_FL";
CM_ SG_ 1099 CVC_RRSeatHeating_Set "CVC translate and forward signal seat heating level to BCM_RE";
CM_ SG_ 1099 CVC_RRSeatVentilation_Set "CVC translate and forward signal seat Ventilation level to BCM_RE";
CM_ SG_ 1099 CVC_RLSeatVentilation_Set "CVC translate and forward signal seat Ventilation level to BCM_RE";
CM_ SG_ 1099 CVC_UserProfile "User profile confirm";
CM_ SG_ 1112 CVC_AmbientLightColorZoneReq "Zone identifier for interior ambient lighting colour.";
CM_ SG_ 1112 CVC_AmbientLightColorRed "Requested Ambient Lighting Red Intensity";
CM_ SG_ 1112 CVC_AmbientLightColorGreen "Requested Ambient Lighting Green Intensity";
CM_ SG_ 1112 CVC_AmbientLightColorBlue "Requested Ambient Lighting Blue Intensity";
CM_ SG_ 1113 CVC_AmbLightIntensityZoneReq "Zone identifier for interior ambient lighting intensity. Allows smart LED module to take into account messages addressed to their zone when intensity value are received.";
CM_ SG_ 1113 CVC_AmbLightIntensityTypeReq "Zone identifier for interior ambient lighting intensity.";
CM_ SG_ 1113 CVC_AmbLightIntensityReq "Intensity (brightness) of interior ambient lighting.";
CM_ SG_ 1113 CVC_AmbLightIntensityTimingT1Req "Blinking: Ton Wave: Tfade Morse: Ton1 Fading: Tfade";
CM_ SG_ 1113 CVC_AmbLightIntensityTimingT2Req "Blinking: Toff Wave: not used Morse: Toff1, Fading: not used";
CM_ SG_ 1113 CVC_AmbLightIntensityTimingT3Req "Blinking: not used Wave: not used Morse: Ton2, Fading: not used";
CM_ SG_ 1113 CVC_AmbLightIntensityTimingT4Req "Blinking: not used Wave: not used Morse: Toff2, Fading: not used";
CM_ SG_ 1113 CVC_AmbLightIntensityTimingN2Req "Morse: number of repetitions for Ton2";
CM_ SG_ 1113 CVC_AmbLightIntensityTimingN1Req "Morse: number of repetitions for Ton1";
CM_ SG_ 1114 CVC_Z3_AmbLightZoneFLReq "Ambient Light Color Zone";
CM_ SG_ 1114 CVC_Z1_AmbLightZoneIPDrivReq "Ambient Light Color Zone";
CM_ SG_ 1114 CVC_Z2_AmbLightZoneFRReq "Ambient Light Color Zone";
CM_ SG_ 1114 CVC_Z5_AmbLightZoneRLReq "Ambient Light Color Zone";
CM_ SG_ 1114 CVC_Z4_AmbLightZoneRRReq "Ambient Light Color Zone";
CM_ SG_ 1114 CVC_Z3B_AmbLightZoneFLReq "Ambient Light Color Zone";
CM_ SG_ 1114 CVC_Z2B_AmbLightZoneFRReq "Ambient Light Color Zone";
CM_ SG_ 1114 CVC_Z6_AmbLightZoneIPPassReq "Ambient Light Color Zone";
CM_ SG_ 1114 CVC_Z6B_AmbLightZoneIPPassReq "Ambient Light Color Zone";
CM_ SG_ 1114 CVC_Z7_AmbLightZoneConsLReq "Ambient Light Color Zone";
CM_ SG_ 1114 CVC_Z7B_AmbLightZoneConsLReq "Ambient Light Color Zone";
CM_ SG_ 1114 CVC_Z8_AmbLightZoneConsRReq "Ambient Light Color Zone";
CM_ SG_ 1114 CVC_Z8B_AmbLightZoneConsRReq "Ambient Light Color Zone";
CM_ SG_ 1114 CVC_Z9_AmbLightZoneConsRLReq "Ambient Light Color Zone";
CM_ SG_ 1114 CVC_Z10_AmbLightZoneConsRRReq "Ambient Light Color Zone";
CM_ SG_ 1114 CVC_Z5B_AmbLightZoneRLReq "Ambient Light Color Zone";
CM_ SG_ 1114 CVC_Z4B_AmbLightZoneRRReq "Ambient Light Color Zone";
CM_ SG_ 1117 CRC_FCAM_Heater_Request "Checksum";
CM_ SG_ 1117 ALIVE_FCAM_Heater_Request "Alive Counter";
CM_ SG_ 1117 FCAM_HeaterActivation_Req "FCAM Request Windshield Heating";
CM_ SG_ 1171 CRC_BMS_WarnMsg "Checksum";
CM_ SG_ 1171 ALIVE_BMS_WarnMsg "Alive Counter";
CM_ SG_ 1171 BMS_PackTempSts "Pack temperature warning";
CM_ SG_ 1171 BMS_ThermalRunaway "Thermal runaway warning";
CM_ SG_ 1171 BMS_BatteryReplacement "Separate signal to indicate the battery replacement information(Battery replacement CVC_B)";
CM_ SG_ 1171 BMS_Warning_PowerDegrade "Pack Power Degrade: Battery is cold & limited capacity, please charge";
CM_ SG_ 1171 BMS_Warning_DeltaSoC "EV Battery Delta SOC is high, range reduction in vehicle will be absorbed";
CM_ SG_ 1171 BMS_Warning_HVILSts "HVIL warning signal";
CM_ SG_ 1171 BMS_Warning_Isolation "Coolant Leakage warning";
CM_ SG_ 1171 BMS_Warning_CoolantLeakage "Coolant Leakage warning";
CM_ SG_ 1171 BMS_MalfunctionSts "Malfunction status of battery for CVC_B display";
CM_ SG_ 1171 BMS_LowBattery "Low Battery Warning";
CM_ SG_ 1171 BMS_Warning_DeltaTemperature "Delta temperature warning signal";
CM_ SG_ 1171 BMS_Warning_BDUTemperatureSts "BDU temperature warning signal";
CM_ SG_ 1171 BMS_Warning_Contactor_Aging "Contactor Aging Warning";
CM_ SG_ 1171 BMS_Reserved_signal4 "Warning Message Flag, Component owner, Supplier align and define for this signal";
CM_ SG_ 1171 BMS_Reserved_signal5 "Warning Message Flag, Component owner, Supplier align and define for this signal";
CM_ SG_ 1257 CVC_RHMirrorAdjustmentSet "Right mirror adjustment mode";
CM_ SG_ 1257 CVC_LHMirrorAdjustmentSet "Left mirror adjustment mode";
CM_ SG_ 1257 CVC_SET_MirrorFold_Right "Right side mirror fold";
CM_ SG_ 1257 CVC_SET_MirrorFold_Left "Left side mirror fold";
CM_ SG_ 1257 RHMirror_Adjustment_Req "Right mirror adjustment request";
CM_ SG_ 1257 LHMirror_Adjustment_Req "Left mirror adjustment request";
CM_ SG_ 1257 CVC_SET_LeftMirrorPosX "CVC store Mirror position and send request to BCM_FL";
CM_ SG_ 1257 CVC_SET_LeftMirrorPosY "CVC store Mirror position and send request to BCM_FL";
CM_ SG_ 1257 CVC_SET_RightMirrorPosX "CVC store Mirror position and send request to BCM_FR";
CM_ SG_ 1257 CVC_SET_RightMirrorPosY "CVC store Mirror position and send request to BCM_FR";
CM_ SG_ 1879 CVC_TMSMode "Thermal management system mode";
CM_ SG_ 1879 CVC_HVCHPowerLim "High voltage charging power limit value";
CM_ SG_ 1879 CVC_HVCHOffCode "High voltage charging interruption code";
CM_ SG_ 1879 CVC_AirPTCOffCode "Air conditioner PTC heating shutdown code";
CM_ SG_ 1879 CVC_CompOffCode "Air conditioning compressor shutdown code";
CM_ SG_ 1889 EAC_speed "Electric Air Compressor Speed";
CM_ SG_ 1889 EAC_status "Electric Air Compressor Status";
CM_ SG_ 1889 UIF_Temperatur "Interior Temperature";
CM_ SG_ 168 BCMRE_Climate_RearAirDistFlapPos "Rear air distribution flap actual position";
CM_ SG_ 168 BCMRE_Climate_RearTempFlapPos "Rear temperature flap actual position";
CM_ SG_ 168 BCMRE_Climate_RearAirRecirculati "current Recirculation status";
CM_ SG_ 168 BCMRE_Climate_RearAirDistFlapSts "Rear air distribution flap fault status";
CM_ SG_ 168 BCMRE_Climate_RearTempFlapSts "Rear temperature flap fault status";
CM_ SG_ 168 BCMRE_Climate_AirDistFlapRHPos "Mode Flap RH Actual Position";
CM_ SG_ 168 BCMRE_Climate_AirDistFlapRHSts "Mode Flap RH Status";
CM_ SG_ 168 BCMRE_Climate_BypassFlap "Bypass Flap Actual Position";
CM_ SG_ 168 BCMRE_Climate_BypassFlapSts "Bypass Flap Status";
CM_ SG_ 168 BCMRE_Climate_AirDistRearFlapPos "Rear Mode Flap Actual Position";
CM_ SG_ 168 BCMRE_Climate_AirDistRearFlapSts "Rear Mode Flap Status";
CM_ SG_ 172 CRC_BCMRE_DoorStatus "Checksum";
CM_ SG_ 172 ALIVE_BCMRE_DoorStatus "Alive counter";
CM_ SG_ 172 TailgateAjarStatus "ETG Ajar Door Status";
CM_ SG_ 172 TailgateLockStatus "Signal from BCM to indicate the Lock Status of ETG";
CM_ SG_ 172 Fuel_Port_Lock_Status "Fuel Filler Flap Locked Status";
CM_ SG_ 172 Fuel_Port_Ajar_Status "Fuel Filler Flap Not Fully Closed Status";
CM_ SG_ 179 Tailgate_Malfunction "Feedback the error on the electric tailgate latch to CVC";
CM_ SG_ 179 TailgateIntButton_Request "Send tailgate Interior Switch press event to CVC";
CM_ SG_ 179 AntiPinch_Operation "Operation of anti pinch function";
CM_ SG_ 188 DoorPassiveEntry_Request "Door keyless entry request";
CM_ SG_ 188 TailgatePassiveEntry_Request "Keyless entry request for trunk";
BA_DEF_ BO_  "DiagRequest" ENUM  "No","Yes";
BA_DEF_ BO_  "DiagResponse" ENUM  "No","Yes";
BA_DEF_ BO_  "DiagState" ENUM  "No","Yes";
BA_DEF_ BO_  "GenMsgCycleTime" INT 0 65535;
BA_DEF_ BO_  "GenMsgCycleTimeFast" INT 0 65535;
BA_DEF_ BO_  "GenMsgDelayTime" INT 0 65535;
BA_DEF_ BO_  "GenMsgILSupport" ENUM  "No","Yes";
BA_DEF_ BO_  "GenMsgNrOfRepetition" INT 0 65535;
BA_DEF_ BO_  "GenMsgSendType" ENUM  "Cyclic","NoMsgSendType","NotUsed","NotUsed","NotUsed","NotUsed","NotUsed","IfActive","NoMsgSendType","NotUsed";
BA_DEF_ BO_  "NmAsrMessage" ENUM  "No","Yes";
BA_DEF_ BO_  "NmMessage" ENUM  "No","Yes";
BA_DEF_ SG_  "GenSigSendType" ENUM  "Cyclic","NoSigSendType","OnWriteWithRepetition","OnChange","OnChangeWithRepetition","IfActive","IfActiveWithRepetition","OnWrite","NotUsed","NotUsed","NotUsed","NotUsed","NotUsed";
BA_DEF_ SG_  "GenSigStartValue" INT 0 2147483647;
BA_DEF_ SG_  "GenSigTimeoutTime_ALL" INT 0 65535;
BA_DEF_ SG_  "InvalidValue" STRING ;
BA_DEF_ SG_  "GenSigInactiveValue" INT 0 2147483647;
BA_DEF_ BO_  "VFrameFormat" ENUM  "StandardCAN","ExtendedCAN","reserved","J1939PG","reserved","reserved","reserved","reserved","reserved","reserved","reserved","reserved","reserved","reserved","StandardCAN_FD","ExtendedCAN_FD";
BA_DEF_ BO_  "CANFD_BRS" ENUM  "0","1";
BA_DEF_ SG_  "SystemSignalLongSymbol" STRING ;
BA_DEF_DEF_  "DiagRequest" "No";
BA_DEF_DEF_  "DiagResponse" "No";
BA_DEF_DEF_  "DiagState" "No";
BA_DEF_DEF_  "GenMsgCycleTime" 0;
BA_DEF_DEF_  "GenMsgCycleTimeFast" 0;
BA_DEF_DEF_  "GenMsgDelayTime" 0;
BA_DEF_DEF_  "GenMsgILSupport" "Yes";
BA_DEF_DEF_  "GenMsgNrOfRepetition" 0;
BA_DEF_DEF_  "GenMsgSendType" "Cyclic";
BA_DEF_DEF_  "NmAsrMessage" "No";
BA_DEF_DEF_  "NmMessage" "No";
BA_DEF_DEF_  "GenSigSendType" "Cyclic";
BA_DEF_DEF_  "GenSigStartValue" 0;
BA_DEF_DEF_  "GenSigTimeoutTime_ALL" 0;
BA_DEF_DEF_  "InvalidValue" "";
BA_DEF_DEF_  "GenSigInactiveValue" 0;
BA_DEF_DEF_  "VFrameFormat" "StandardCAN_FD";
BA_DEF_DEF_  "CANFD_BRS" "1";
BA_DEF_DEF_  "SystemSignalLongSymbol" "";
BA_ "GenMsgCycleTime" BO_ 267 100;
BA_ "GenMsgCycleTime" BO_ 274 100;
BA_ "GenMsgCycleTime" BO_ 278 100;
BA_ "GenMsgSendType" BO_ 284 1;
BA_ "GenMsgCycleTime" BO_ 307 50;
BA_ "GenMsgCycleTimeFast" BO_ 307 15;
BA_ "GenMsgNrOfRepetition" BO_ 307 3;
BA_ "GenMsgSendType" BO_ 323 1;
BA_ "GenMsgCycleTime" BO_ 382 10;
BA_ "GenMsgCycleTime" BO_ 519 100;
BA_ "GenMsgCycleTime" BO_ 524 100;
BA_ "GenMsgCycleTime" BO_ 525 20;
BA_ "GenMsgCycleTime" BO_ 533 50;
BA_ "GenMsgCycleTime" BO_ 536 100;
BA_ "GenMsgCycleTime" BO_ 539 100;
BA_ "GenMsgCycleTime" BO_ 541 100;
BA_ "GenMsgCycleTime" BO_ 542 100;
BA_ "GenMsgCycleTime" BO_ 565 100;
BA_ "GenMsgCycleTime" BO_ 592 100;
BA_ "GenMsgCycleTime" BO_ 619 100;
BA_ "GenMsgCycleTime" BO_ 662 100;
BA_ "GenMsgSendType" BO_ 676 1;
BA_ "GenMsgCycleTime" BO_ 746 200;
BA_ "GenMsgCycleTime" BO_ 760 1000;
BA_ "GenMsgSendType" BO_ 768 1;
BA_ "GenMsgCycleTime" BO_ 773 100;
BA_ "GenMsgCycleTime" BO_ 775 1000;
BA_ "GenMsgCycleTime" BO_ 776 200;
BA_ "GenMsgCycleTimeFast" BO_ 776 20;
BA_ "GenMsgNrOfRepetition" BO_ 776 3;
BA_ "GenMsgCycleTime" BO_ 777 200;
BA_ "GenMsgCycleTimeFast" BO_ 777 20;
BA_ "GenMsgNrOfRepetition" BO_ 777 3;
BA_ "GenMsgCycleTime" BO_ 778 200;
BA_ "GenMsgCycleTimeFast" BO_ 778 20;
BA_ "GenMsgNrOfRepetition" BO_ 778 3;
BA_ "GenMsgCycleTime" BO_ 779 100;
BA_ "GenMsgCycleTimeFast" BO_ 779 20;
BA_ "GenMsgNrOfRepetition" BO_ 779 3;
BA_ "GenMsgCycleTime" BO_ 862 100;
BA_ "GenMsgCycleTime" BO_ 892 100;
BA_ "GenMsgCycleTime" BO_ 897 40;
BA_ "GenMsgCycleTime" BO_ 899 1000;
BA_ "GenMsgSendType" BO_ 905 1;
BA_ "GenMsgSendType" BO_ 921 1;
BA_ "GenMsgSendType" BO_ 922 1;
BA_ "GenMsgCycleTime" BO_ 925 50;
BA_ "GenMsgCycleTime" BO_ 1004 100;
BA_ "GenMsgSendType" BO_ 1009 1;
BA_ "GenMsgCycleTime" BO_ 1011 500;
BA_ "GenMsgCycleTime" BO_ 1015 1000;
BA_ "GenMsgCycleTimeFast" BO_ 1015 50;
BA_ "GenMsgNrOfRepetition" BO_ 1015 3;
BA_ "GenMsgCycleTime" BO_ 1017 100;
BA_ "GenMsgCycleTime" BO_ 1022 100;
BA_ "GenMsgCycleTime" BO_ 1026 100;
BA_ "GenMsgSendType" BO_ 1032 1;
BA_ "GenMsgSendType" BO_ 1033 1;
BA_ "GenMsgCycleTime" BO_ 1036 200;
BA_ "GenMsgCycleTime" BO_ 1050 500;
BA_ "GenMsgCycleTimeFast" BO_ 1050 100;
BA_ "GenMsgNrOfRepetition" BO_ 1050 3;
BA_ "GenMsgCycleTime" BO_ 1066 100;
BA_ "GenMsgCycleTime" BO_ 1074 500;
BA_ "GenMsgCycleTime" BO_ 1082 100;
BA_ "GenMsgCycleTime" BO_ 1099 100;
BA_ "GenMsgSendType" BO_ 1112 1;
BA_ "GenMsgSendType" BO_ 1113 1;
BA_ "GenMsgSendType" BO_ 1114 1;
BA_ "GenMsgCycleTime" BO_ 1117 100;
BA_ "GenMsgCycleTime" BO_ 1171 1000;
BA_ "GenMsgSendType" BO_ 1257 1;
BA_ "GenMsgSendType" BO_ 1879 1;
BA_ "GenMsgCycleTime" BO_ 1889 1000;
BA_ "GenMsgCycleTime" BO_ 1968 15000;
BA_ "GenMsgCycleTimeFast" BO_ 1968 50;
BA_ "GenMsgNrOfRepetition" BO_ 1968 2;
BA_ "GenMsgSendType" BO_ 168 1;
BA_ "GenMsgCycleTime" BO_ 172 20;
BA_ "GenMsgCycleTime" BO_ 179 100;
BA_ "GenMsgCycleTime" BO_ 188 100;
BA_ "InvalidValue" SG_ 267 ALIVE_TRM_LIGHT "Fh";
BA_ "InvalidValue" SG_ 267 TrailerInput "3h";
BA_ "GenSigStartValue" SG_ 267 TrailerInput 3;
BA_ "InvalidValue" SG_ 267 TrailerSystemError "3h";
BA_ "GenSigStartValue" SG_ 267 TrailerSystemError 3;
BA_ "InvalidValue" SG_ 267 TRM_VoltageStatus "3h";
BA_ "InvalidValue" SG_ 267 TRM_STAT_BrakeLight "3h";
BA_ "InvalidValue" SG_ 267 TRM_STAT_FogLampRear "3h";
BA_ "InvalidValue" SG_ 267 TRM_STAT_PositionLight "3h";
BA_ "InvalidValue" SG_ 267 TRM_STAT_TurnIndicators "Fh";
BA_ "InvalidValue" SG_ 267 TRM_STAT_ReverseLight "3h";
BA_ "InvalidValue" SG_ 267 TRM_STAT_HWBrakeLightInput "3h";
BA_ "InvalidValue" SG_ 267 TRM_STAT_HWIndicatorInput "3h";
BA_ "InvalidValue" SG_ 267 TRM_STAT_HWPosLightInput "3h";
BA_ "InvalidValue" SG_ 274 ALIVE_CVC_CLAMP_STAT "Fh";
BA_ "InvalidValue" SG_ 274 RemoteFunctionState "3h";
BA_ "InvalidValue" SG_ 274 CVC_STAT_BLS "3h";
BA_ "InvalidValue" SG_ 274 Vehicle_Operation_State "7h";
BA_ "InvalidValue" SG_ 284 TBOX_FOTA_STAT_TerminalReq "7h";
BA_ "GenSigSendType" SG_ 284 TBOX_FOTA_STAT_TerminalReq 1;
BA_ "GenSigTimeoutTime_ALL" SG_ 307 CRC_SRR_RR_BSD_RCTA_DOW 500;
BA_ "InvalidValue" SG_ 307 ALIVE_SRR_RR_BSD_RCTA_DOW "Fh";
BA_ "GenSigTimeoutTime_ALL" SG_ 307 ALIVE_SRR_RR_BSD_RCTA_DOW 500;
BA_ "InvalidValue" SG_ 307 SRR_RR_BSD_check "3h";
BA_ "GenSigTimeoutTime_ALL" SG_ 307 SRR_RR_BSD_check 500;
BA_ "GenSigSendType" SG_ 307 SRR_RR_BSD_check 2;
BA_ "InvalidValue" SG_ 307 SRR_RR_BSD_state "7h";
BA_ "GenSigTimeoutTime_ALL" SG_ 307 SRR_RR_BSD_state 500;
BA_ "GenSigSendType" SG_ 307 SRR_RR_BSD_state 2;
BA_ "InvalidValue" SG_ 307 SRR_RR_BSD_AudChime_Feed "0h";
BA_ "GenSigTimeoutTime_ALL" SG_ 307 SRR_RR_BSD_AudChime_Feed 500;
BA_ "GenSigSendType" SG_ 307 SRR_RR_BSD_AudChime_Feed 2;
BA_ "InvalidValue" SG_ 307 SRR_RR_BSD_IndLeft "3h";
BA_ "GenSigTimeoutTime_ALL" SG_ 307 SRR_RR_BSD_IndLeft 500;
BA_ "GenSigSendType" SG_ 307 SRR_RR_BSD_IndLeft 2;
BA_ "InvalidValue" SG_ 307 SRR_RR_BSD_IndRight "3h";
BA_ "GenSigTimeoutTime_ALL" SG_ 307 SRR_RR_BSD_IndRight 500;
BA_ "GenSigSendType" SG_ 307 SRR_RR_BSD_IndRight 2;
BA_ "InvalidValue" SG_ 307 SRR_RR_BSD_SndWarn "0h";
BA_ "GenSigTimeoutTime_ALL" SG_ 307 SRR_RR_BSD_SndWarn 500;
BA_ "GenSigSendType" SG_ 307 SRR_RR_BSD_SndWarn 2;
BA_ "InvalidValue" SG_ 307 SRR_RR_BSD_Mode_Feed "0h";
BA_ "GenSigStartValue" SG_ 307 SRR_RR_BSD_Mode_Feed 1;
BA_ "GenSigTimeoutTime_ALL" SG_ 307 SRR_RR_BSD_Mode_Feed 500;
BA_ "GenSigSendType" SG_ 307 SRR_RR_BSD_Mode_Feed 2;
BA_ "InvalidValue" SG_ 307 SRR_RR_BSD_sens_Feed "3h";
BA_ "GenSigTimeoutTime_ALL" SG_ 307 SRR_RR_BSD_sens_Feed 500;
BA_ "GenSigSendType" SG_ 307 SRR_RR_BSD_sens_Feed 2;
BA_ "InvalidValue" SG_ 307 SRR_RR_RCTA_IndRight "0h";
BA_ "GenSigTimeoutTime_ALL" SG_ 307 SRR_RR_RCTA_IndRight 500;
BA_ "GenSigSendType" SG_ 307 SRR_RR_RCTA_IndRight 2;
BA_ "InvalidValue" SG_ 307 SRR_RR_RCTA_IndLeft "0h";
BA_ "GenSigTimeoutTime_ALL" SG_ 307 SRR_RR_RCTA_IndLeft 500;
BA_ "GenSigSendType" SG_ 307 SRR_RR_RCTA_IndLeft 2;
BA_ "InvalidValue" SG_ 307 SRR_RR_RCTA_sens_Feed "3h";
BA_ "GenSigTimeoutTime_ALL" SG_ 307 SRR_RR_RCTA_sens_Feed 500;
BA_ "GenSigSendType" SG_ 307 SRR_RR_RCTA_sens_Feed 2;
BA_ "InvalidValue" SG_ 307 SRR_RR_RCTA_state "7h";
BA_ "GenSigTimeoutTime_ALL" SG_ 307 SRR_RR_RCTA_state 500;
BA_ "GenSigSendType" SG_ 307 SRR_RR_RCTA_state 2;
BA_ "InvalidValue" SG_ 307 SRR_RR_RCTA_SndWarn "0h";
BA_ "GenSigTimeoutTime_ALL" SG_ 307 SRR_RR_RCTA_SndWarn 500;
BA_ "GenSigSendType" SG_ 307 SRR_RR_RCTA_SndWarn 2;
BA_ "InvalidValue" SG_ 307 SRR_RR_RCTA_Mode_Feed "3h";
BA_ "GenSigTimeoutTime_ALL" SG_ 307 SRR_RR_RCTA_Mode_Feed 500;
BA_ "GenSigSendType" SG_ 307 SRR_RR_RCTA_Mode_Feed 2;
BA_ "InvalidValue" SG_ 307 SRR_RR_RCTA_check "3h";
BA_ "GenSigTimeoutTime_ALL" SG_ 307 SRR_RR_RCTA_check 500;
BA_ "GenSigSendType" SG_ 307 SRR_RR_RCTA_check 2;
BA_ "InvalidValue" SG_ 307 SRR_RR_DOW_SndWarn "0h";
BA_ "GenSigTimeoutTime_ALL" SG_ 307 SRR_RR_DOW_SndWarn 500;
BA_ "GenSigSendType" SG_ 307 SRR_RR_DOW_SndWarn 2;
BA_ "InvalidValue" SG_ 307 SRR_RR_DOW_WarnRight "3h";
BA_ "GenSigTimeoutTime_ALL" SG_ 307 SRR_RR_DOW_WarnRight 500;
BA_ "GenSigSendType" SG_ 307 SRR_RR_DOW_WarnRight 2;
BA_ "InvalidValue" SG_ 307 SRR_RR_DOW_WarnLeft "3h";
BA_ "GenSigTimeoutTime_ALL" SG_ 307 SRR_RR_DOW_WarnLeft 500;
BA_ "GenSigSendType" SG_ 307 SRR_RR_DOW_WarnLeft 2;
BA_ "InvalidValue" SG_ 307 SRR_RR_DOW_check "3h";
BA_ "GenSigTimeoutTime_ALL" SG_ 307 SRR_RR_DOW_check 500;
BA_ "GenSigSendType" SG_ 307 SRR_RR_DOW_check 2;
BA_ "InvalidValue" SG_ 307 SRR_RR_DOW_state "7h";
BA_ "GenSigTimeoutTime_ALL" SG_ 307 SRR_RR_DOW_state 500;
BA_ "GenSigSendType" SG_ 307 SRR_RR_DOW_state 2;
BA_ "InvalidValue" SG_ 307 SRR_RR_DOW_Mode_Feed "3h";
BA_ "GenSigTimeoutTime_ALL" SG_ 307 SRR_RR_DOW_Mode_Feed 500;
BA_ "GenSigSendType" SG_ 307 SRR_RR_DOW_Mode_Feed 2;
BA_ "InvalidValue" SG_ 307 SRR_RR_Right_block "3h";
BA_ "GenSigTimeoutTime_ALL" SG_ 307 SRR_RR_Right_block 500;
BA_ "GenSigSendType" SG_ 307 SRR_RR_Right_block 2;
BA_ "InvalidValue" SG_ 307 SRR_RR_Left_block "3h";
BA_ "GenSigTimeoutTime_ALL" SG_ 307 SRR_RR_Left_block 500;
BA_ "GenSigSendType" SG_ 307 SRR_RR_Left_block 2;
BA_ "InvalidValue" SG_ 307 Obj_ID_RL "FFh";
BA_ "GenSigTimeoutTime_ALL" SG_ 307 Obj_ID_RL 500;
BA_ "GenSigSendType" SG_ 307 Obj_ID_RL 2;
BA_ "InvalidValue" SG_ 307 Obj_Class_RL "7h";
BA_ "GenSigTimeoutTime_ALL" SG_ 307 Obj_Class_RL 500;
BA_ "GenSigSendType" SG_ 307 Obj_Class_RL 2;
BA_ "InvalidValue" SG_ 307 Obj_OrientationAngle_RL "3FFh";
BA_ "GenSigTimeoutTime_ALL" SG_ 307 Obj_OrientationAngle_RL 500;
BA_ "GenSigSendType" SG_ 307 Obj_OrientationAngle_RL 2;
BA_ "InvalidValue" SG_ 307 Obj_DistLong_RL "1FFFh";
BA_ "GenSigTimeoutTime_ALL" SG_ 307 Obj_DistLong_RL 500;
BA_ "GenSigSendType" SG_ 307 Obj_DistLong_RL 2;
BA_ "InvalidValue" SG_ 307 Obj_DislLat_RL "7FFFh";
BA_ "GenSigTimeoutTime_ALL" SG_ 307 Obj_DislLat_RL 500;
BA_ "GenSigSendType" SG_ 307 Obj_DislLat_RL 2;
BA_ "InvalidValue" SG_ 307 Obj_VrelLong_RL "3FFh";
BA_ "GenSigTimeoutTime_ALL" SG_ 307 Obj_VrelLong_RL 500;
BA_ "GenSigSendType" SG_ 307 Obj_VrelLong_RL 2;
BA_ "InvalidValue" SG_ 307 Obj_VrelLat_RL "1FFh";
BA_ "GenSigTimeoutTime_ALL" SG_ 307 Obj_VrelLat_RL 500;
BA_ "GenSigSendType" SG_ 307 Obj_VrelLat_RL 2;
BA_ "InvalidValue" SG_ 307 Obj_ID_RR "FFh";
BA_ "GenSigTimeoutTime_ALL" SG_ 307 Obj_ID_RR 500;
BA_ "GenSigSendType" SG_ 307 Obj_ID_RR 2;
BA_ "InvalidValue" SG_ 307 Obj_Class_RR "7h";
BA_ "GenSigTimeoutTime_ALL" SG_ 307 Obj_Class_RR 500;
BA_ "GenSigSendType" SG_ 307 Obj_Class_RR 2;
BA_ "InvalidValue" SG_ 307 Obj_OrientationAngle_RR "3FFh";
BA_ "GenSigTimeoutTime_ALL" SG_ 307 Obj_OrientationAngle_RR 500;
BA_ "GenSigSendType" SG_ 307 Obj_OrientationAngle_RR 2;
BA_ "InvalidValue" SG_ 307 Obj_DistLong_RR "1FFFh";
BA_ "GenSigTimeoutTime_ALL" SG_ 307 Obj_DistLong_RR 500;
BA_ "GenSigSendType" SG_ 307 Obj_DistLong_RR 2;
BA_ "InvalidValue" SG_ 307 Obj_DislLat_RR "7FFFh";
BA_ "GenSigTimeoutTime_ALL" SG_ 307 Obj_DislLat_RR 500;
BA_ "GenSigSendType" SG_ 307 Obj_DislLat_RR 2;
BA_ "InvalidValue" SG_ 307 Obj_VrelLong_RR "3FFh";
BA_ "GenSigTimeoutTime_ALL" SG_ 307 Obj_VrelLong_RR 500;
BA_ "GenSigSendType" SG_ 307 Obj_VrelLong_RR 2;
BA_ "InvalidValue" SG_ 307 Obj_VrelLat_RR "1FFh";
BA_ "GenSigTimeoutTime_ALL" SG_ 307 Obj_VrelLat_RR 500;
BA_ "GenSigSendType" SG_ 307 Obj_VrelLat_RR 2;
BA_ "InvalidValue" SG_ 307 SRR_RR_RCTB_Mode_Feed "3h";
BA_ "GenSigTimeoutTime_ALL" SG_ 307 SRR_RR_RCTB_Mode_Feed 250;
BA_ "InvalidValue" SG_ 307 SRR_RR_RCTB_State "7h";
BA_ "GenSigTimeoutTime_ALL" SG_ 307 SRR_RR_RCTB_State 250;
BA_ "InvalidValue" SG_ 307 SRR_RR_RCTB_Check "3h";
BA_ "GenSigTimeoutTime_ALL" SG_ 307 SRR_RR_RCTB_Check 250;
BA_ "InvalidValue" SG_ 307 SRR_RR_RCTB_Braking_Flag "3h";
BA_ "GenSigTimeoutTime_ALL" SG_ 307 SRR_RR_RCTB_Braking_Flag 250;
BA_ "InvalidValue" SG_ 307 SRR_RR_RCTB_Braking_Deceleration "FFh";
BA_ "GenSigTimeoutTime_ALL" SG_ 307 SRR_RR_RCTB_Braking_Deceleration 250;
BA_ "InvalidValue" SG_ 307 SRR_RR_CollisionObjID "FFh";
BA_ "GenSigTimeoutTime_ALL" SG_ 307 SRR_RR_CollisionObjID 250;
BA_ "InvalidValue" SG_ 323 Ionizer_Set "3h";
BA_ "GenSigSendType" SG_ 323 Ionizer_Set 1;
BA_ "GenSigSendType" SG_ 323 Rear_AirRecirculationFlap_Set 1;
BA_ "GenSigSendType" SG_ 323 FrontPass_AirModeFlap_Set 1;
BA_ "GenSigSendType" SG_ 323 FrontByPass_AirModeFlap_Set 1;
BA_ "GenSigSendType" SG_ 323 RearFoot_AirModeFlap_Set 1;
BA_ "GenSigSendType" SG_ 323 Rear_AirModeFlap_Set 1;
BA_ "GenSigSendType" SG_ 323 RL_TempFlap_Set 1;
BA_ "GenSigSendType" SG_ 323 RR_TempFlap_Set 1;
BA_ "GenSigSendType" SG_ 323 Rear_TempFlap_Set 1;
BA_ "GenSigSendType" SG_ 323 RearSOV_Req 1;
BA_ "InvalidValue" SG_ 323 RearBlowerRelay_Set "3h";
BA_ "GenSigSendType" SG_ 323 RearBlowerRelay_Set 1;
BA_ "InvalidValue" SG_ 382 ALIVE_EPS_SAS_Sensor "Fh";
BA_ "GenSigStartValue" SG_ 382 SAS_SteerWhlRotSpd 8000;
BA_ "InvalidValue" SG_ 382 SAS_SteerWheelAngleValid "1h";
BA_ "GenSigStartValue" SG_ 519 BCM_AutoSunroof_Sts 2;
BA_ "InvalidValue" SG_ 524 ALIVE_CVC_ODO "Fh";
BA_ "GenSigTimeoutTime_ALL" SG_ 525 CRC_WCBS_STATUS 200;
BA_ "InvalidValue" SG_ 525 ALIVE_WCBS_STATUS "Fh";
BA_ "GenSigTimeoutTime_ALL" SG_ 525 ALIVE_WCBS_STATUS 200;
BA_ "GenSigTimeoutTime_ALL" SG_ 525 ABSFailed 200;
BA_ "GenSigTimeoutTime_ALL" SG_ 525 ABSActive 200;
BA_ "GenSigTimeoutTime_ALL" SG_ 525 WCBS_VehicleSpeed 200;
BA_ "GenSigTimeoutTime_ALL" SG_ 525 ESC_VehicleStandstill 200;
BA_ "GenSigTimeoutTime_ALL" SG_ 525 WCBS_VehicleSpeedValid 200;
BA_ "GenSigTimeoutTime_ALL" SG_ 525 ESC_VehicleHoldStat 200;
BA_ "InvalidValue" SG_ 525 WCBS_Veh_DriveCondition "7h";
BA_ "InvalidValue" SG_ 533 ALIVE_BMS_Sts "Fh";
BA_ "GenSigStartValue" SG_ 533 BMS_SOH 54;
BA_ "GenSigStartValue" SG_ 533 BMS_SOE 54;
BA_ "InvalidValue" SG_ 533 BMS_HV_Sts "FFh";
BA_ "InvalidValue" SG_ 536 ALIVE_CVC_ExteriorLight_Req "Fh";
BA_ "InvalidValue" SG_ 536 CVC_PosLight_RR_Req "3h";
BA_ "InvalidValue" SG_ 536 CVC_RearFogLamp_RL_Req "3h";
BA_ "InvalidValue" SG_ 536 CVC_RearFogLamp_RR_Req "3h";
BA_ "InvalidValue" SG_ 536 CVC_DaytimeRunningLight_FL_Req "3h";
BA_ "InvalidValue" SG_ 536 CVC_DaytimeRunningLight_FR_Req "3h";
BA_ "InvalidValue" SG_ 536 CVC_TurnIndicator_FL_Req "3h";
BA_ "GenSigStartValue" SG_ 536 CVC_TurnIndicator_FL_Req 2;
BA_ "InvalidValue" SG_ 536 CVC_TurnIndicator_RL_Req "3h";
BA_ "GenSigStartValue" SG_ 536 CVC_TurnIndicator_RL_Req 2;
BA_ "InvalidValue" SG_ 536 CVC_TurnIndicator_FR_Req "3h";
BA_ "GenSigStartValue" SG_ 536 CVC_TurnIndicator_FR_Req 2;
BA_ "InvalidValue" SG_ 536 CVC_TurnIndicator_RR_Req "3h";
BA_ "GenSigStartValue" SG_ 536 CVC_TurnIndicator_RR_Req 2;
BA_ "InvalidValue" SG_ 536 CVC_RLS_AutoLampRequest "3h";
BA_ "InvalidValue" SG_ 536 CVC_ReverseLamp_RL_Req "3h";
BA_ "InvalidValue" SG_ 536 CVC_ReverseLamp_RR_Req "3h";
BA_ "InvalidValue" SG_ 536 CVC_BrakeLight_RL_Req "3h";
BA_ "InvalidValue" SG_ 536 CVC_BrakeLight_RR_Req "3h";
BA_ "InvalidValue" SG_ 536 CVC_BrakeLight_Center_Req "3h";
BA_ "InvalidValue" SG_ 536 CVC_LicensePlateLamp_RE_Req "3h";
BA_ "InvalidValue" SG_ 536 CVC_HighBeam_FL_Req "3h";
BA_ "InvalidValue" SG_ 536 CVC_HighBeam_FR_Req "3h";
BA_ "InvalidValue" SG_ 536 CVC_LowBeam_FL_Req "3h";
BA_ "InvalidValue" SG_ 536 CVC_LowBeam_FR_Req "3h";
BA_ "InvalidValue" SG_ 536 CVC_PosLight_RL_Req "3h";
BA_ "InvalidValue" SG_ 536 CVC_MirrorLED_FL_Req "3h";
BA_ "InvalidValue" SG_ 536 CVC_MirrorLED_FR_Req "3h";
BA_ "InvalidValue" SG_ 536 CVC_WelcomeFarewellLight_Req "3h";
BA_ "InvalidValue" SG_ 536 CVC_SignatureLight_RE_Req "3h";
BA_ "InvalidValue" SG_ 536 CVC_PosLight_FR_Req "3h";
BA_ "InvalidValue" SG_ 536 CVC_PosLight_FL_Req "3h";
BA_ "InvalidValue" SG_ 536 CVC_FrontFogLamp_FR_Req "3h";
BA_ "InvalidValue" SG_ 536 CVC_FrontFogLamp_FL_Req "3h";
BA_ "InvalidValue" SG_ 536 CVC_IndicatorMode_Req "Fh";
BA_ "InvalidValue" SG_ 536 CVC_ParkLight_RL_Req "3h";
BA_ "InvalidValue" SG_ 536 CVC_ParkLight_RR_Req "3h";
BA_ "InvalidValue" SG_ 536 CVC_SideMarkerLight_Req "3h";
BA_ "InvalidValue" SG_ 536 CVC_ParkLight_RM_Req "3h";
BA_ "InvalidValue" SG_ 536 CVC_PosLight_RM_Req "3h";
BA_ "InvalidValue" SG_ 539 CVC_Mirror_CourtesyLightReq "3h";
BA_ "GenSigStartValue" SG_ 539 CVC_Mirror_CourtesyLightReq 2;
BA_ "InvalidValue" SG_ 539 CVC_CargoLightReq "3h";
BA_ "InvalidValue" SG_ 539 CVC_BonnetLightReq "3h";
BA_ "InvalidValue" SG_ 539 CVC_FLFootwellLightReq "3h";
BA_ "InvalidValue" SG_ 539 CVC_FRFootwellLightReq "3h";
BA_ "InvalidValue" SG_ 539 CVC_FrontDomeLampReq "3h";
BA_ "InvalidValue" SG_ 539 CVC_Rear_2nd_DomeLampReq "3h";
BA_ "GenSigStartValue" SG_ 539 CVC_SwitchLightBrightnessSet 80;
BA_ "InvalidValue" SG_ 539 CVC_FLScuffLightReq "3h";
BA_ "InvalidValue" SG_ 539 CVC_FRScuffLightReq "3h";
BA_ "InvalidValue" SG_ 539 CVC_FLProjectorLightReq "3h";
BA_ "InvalidValue" SG_ 539 CVC_RLProjectorLightReq "3h";
BA_ "InvalidValue" SG_ 539 CVC_RRProjectorLightReq "3h";
BA_ "InvalidValue" SG_ 539 CVC_FRProjectorLightReq "3h";
BA_ "InvalidValue" SG_ 539 CVC_Rear_3rd_DomeLampReq "3h";
BA_ "InvalidValue" SG_ 539 CVC_HazardLightReq "3h";
BA_ "InvalidValue" SG_ 541 CVC_AHL_STS "3h";
BA_ "InvalidValue" SG_ 542 CVC_RearFogLampSts "3h";
BA_ "InvalidValue" SG_ 542 CVC_ExteriorLightSts "4h";
BA_ "InvalidValue" SG_ 542 CVC_FollowMeHomeSts "5h";
BA_ "InvalidValue" SG_ 542 CVC_WelcomeLightSts "3h";
BA_ "InvalidValue" SG_ 542 CVC_FrontFogLampSts "3h";
BA_ "InvalidValue" SG_ 565 ALIVE_TRM_STATUS "Fh";
BA_ "InvalidValue" SG_ 565 TRM_TowingDetected "3h";
BA_ "InvalidValue" SG_ 565 TRM_TrailerDetected "3h";
BA_ "InvalidValue" SG_ 592 ALIVE_BMS_CVC_THMReq "Fh";
BA_ "InvalidValue" SG_ 592 BMS_PreHeatCoolReq "3h";
BA_ "GenSigStartValue" SG_ 592 BMS_InletTemp_Req 40;
BA_ "InvalidValue" SG_ 619 Sig_TgtVer_LR "3FFh";
BA_ "GenSigStartValue" SG_ 619 Sig_TgtVer_LR 1000;
BA_ "InvalidValue" SG_ 662 ALIVE_POD_DCDC_Status "Fh";
BA_ "InvalidValue" SG_ 662 PDU_DCDC_StsCtrl "Fh";
BA_ "GenSigSendType" SG_ 676 LV_ConsecutiveTopUpCancelCnt 1;
BA_ "GenSigSendType" SG_ 676 CVC_B_ESCOFF_SW_Sts 1;
BA_ "GenSigSendType" SG_ 676 CVC_B_AVH_Req 1;
BA_ "GenSigSendType" SG_ 676 CVC_B_RegencyLevRequest 1;
BA_ "GenSigSendType" SG_ 676 CVC_B_DM_SwitchModeSts 1;
BA_ "GenSigSendType" SG_ 676 CVC_LV_Batt_Charging_Req 1;
BA_ "GenSigSendType" SG_ 676 CVC_B_Trailermode_Req 1;
BA_ "GenSigTimeoutTime_ALL" SG_ 746 InteriorTemperature 500;
BA_ "GenSigStartValue" SG_ 746 CVC_DCChgPosTemp 40;
BA_ "GenSigStartValue" SG_ 746 CVC_DCChgNegTemp 40;
BA_ "GenSigStartValue" SG_ 746 CVC_ACChgLTerminalTemp 40;
BA_ "GenSigStartValue" SG_ 746 CVC_ACChgNTerminalTemp_Reserve 40;
BA_ "GenSigStartValue" SG_ 760 DISP_DATE_DAY 1;
BA_ "GenSigStartValue" SG_ 760 DISP_DATE_MON 1;
BA_ "GenSigStartValue" SG_ 760 DISP_DATE_YR 1;
BA_ "InvalidValue" SG_ 768 CVC_STAT_SyncClimateZone "3h";
BA_ "GenSigSendType" SG_ 768 CVC_STAT_SyncClimateZone 1;
BA_ "InvalidValue" SG_ 768 CVC_STAT_Auto "3h";
BA_ "GenSigSendType" SG_ 768 CVC_STAT_Auto 1;
BA_ "InvalidValue" SG_ 768 CVC_STAT_Aircondition "3h";
BA_ "GenSigSendType" SG_ 768 CVC_STAT_Aircondition 1;
BA_ "InvalidValue" SG_ 768 CVC_STAT_IonButton "3h";
BA_ "GenSigSendType" SG_ 768 CVC_STAT_IonButton 1;
BA_ "InvalidValue" SG_ 768 CVC_STAT_MaxAc "3h";
BA_ "GenSigSendType" SG_ 768 CVC_STAT_MaxAc 1;
BA_ "InvalidValue" SG_ 768 CVC_STAT_ClimateOnOff "3h";
BA_ "GenSigSendType" SG_ 768 CVC_STAT_ClimateOnOff 1;
BA_ "InvalidValue" SG_ 768 CVC_STAT_FanSpeed "Fh";
BA_ "GenSigSendType" SG_ 768 CVC_STAT_FanSpeed 1;
BA_ "InvalidValue" SG_ 768 CVC_STAT_RecircFlap "3h";
BA_ "GenSigStartValue" SG_ 768 CVC_STAT_RecircFlap 1;
BA_ "GenSigSendType" SG_ 768 CVC_STAT_RecircFlap 1;
BA_ "InvalidValue" SG_ 768 CVC_STAT_AirDistributionMode "7h";
BA_ "GenSigSendType" SG_ 768 CVC_STAT_AirDistributionMode 1;
BA_ "InvalidValue" SG_ 768 CVC_STAT_Defrost "3h";
BA_ "GenSigSendType" SG_ 768 CVC_STAT_Defrost 1;
BA_ "InvalidValue" SG_ 768 CVC_STAT_PTC_Heater "7h";
BA_ "GenSigSendType" SG_ 768 CVC_STAT_PTC_Heater 1;
BA_ "GenSigStartValue" SG_ 768 CVC_STAT_TempDriver 48;
BA_ "GenSigSendType" SG_ 768 CVC_STAT_TempDriver 1;
BA_ "GenSigStartValue" SG_ 768 CVC_STAT_TempPassenger 48;
BA_ "GenSigSendType" SG_ 768 CVC_STAT_TempPassenger 1;
BA_ "InvalidValue" SG_ 768 CVC_CoolSysWarnLvl "7h";
BA_ "GenSigSendType" SG_ 768 CVC_CoolSysWarnLvl 1;
BA_ "GenSigStartValue" SG_ 773 HtrMediumOutletTemp 80;
BA_ "GenSigStartValue" SG_ 773 HtrMediumInletTemp 80;
BA_ "InvalidValue" SG_ 775 ALIVE_CPD_OUTPUT "Fh";
BA_ "InvalidValue" SG_ 776 ALIVE_MHU_SET_CPD_Settings "Fh";
BA_ "GenSigSendType" SG_ 776 MHU_SET_CPD_InitWarnDelay 2;
BA_ "GenSigSendType" SG_ 776 MHU_SET_CPD_TempWarnDelay 2;
BA_ "InvalidValue" SG_ 776 MHU_DKCU_CPD_Warn_Cancel "3h";
BA_ "GenSigSendType" SG_ 776 MHU_DKCU_CPD_Warn_Cancel 2;
BA_ "InvalidValue" SG_ 777 ALIVE_CVC_CPD_Warn_Sts "Fh";
BA_ "InvalidValue" SG_ 778 ALIVE_CVC_DKCU_CommandRequest "Fh";
BA_ "GenSigSendType" SG_ 778 CVC_DKCU_PhoneLocationReq 4;
BA_ "GenSigSendType" SG_ 779 CVC_DKCU_Temp_Intervention_Fdbk 4;
BA_ "GenSigSendType" SG_ 779 CVC_DKCU_Remote_Phone_Interventi 4;
BA_ "SystemSignalLongSymbol" SG_ 779 CVC_DKCU_Remote_Phone_Interventi "CVC_DKCU_Remote_Phone_Intervention_Fdbk";
BA_ "InvalidValue" SG_ 862 ALIVE_CVC_Vehicle_info "Fh";
BA_ "GenSigStartValue" SG_ 862 CVC_VehLock_STS 3;
BA_ "InvalidValue" SG_ 892 ALIVE_EVCC_Charging_Sts "Fh";
BA_ "InvalidValue" SG_ 892 EVCC_ChgFlap_Sts "3h";
BA_ "InvalidValue" SG_ 892 EVCC_VehChgCompError_Sts "7h";
BA_ "InvalidValue" SG_ 897 ALIVE_ACU_OCCUPANT_STATUS "Fh";
BA_ "GenSigTimeoutTime_ALL" SG_ 899 CVC_VIN_Byte1 5000;
BA_ "GenSigTimeoutTime_ALL" SG_ 899 CVC_VIN_Byte2 5000;
BA_ "GenSigTimeoutTime_ALL" SG_ 899 CVC_VIN_Byte3 5000;
BA_ "GenSigTimeoutTime_ALL" SG_ 899 CVC_VIN_Byte4 5000;
BA_ "GenSigTimeoutTime_ALL" SG_ 899 CVC_VIN_Byte5 5000;
BA_ "GenSigTimeoutTime_ALL" SG_ 899 CVC_VIN_Byte6 5000;
BA_ "GenSigTimeoutTime_ALL" SG_ 899 CVC_VIN_Byte7 5000;
BA_ "GenSigSendType" SG_ 905 DK_CVC_Immo_Status 1;
BA_ "GenSigSendType" SG_ 905 CVC_IMMO_Sts 1;
BA_ "GenSigSendType" SG_ 905 Truncated_MAC 1;
BA_ "GenSigSendType" SG_ 905 DKCU_AuthSessionStatus 1;
BA_ "GenSigSendType" SG_ 921 CVC_Immo_Byte_0 1;
BA_ "GenSigSendType" SG_ 921 CVC_Immo_Byte_1 1;
BA_ "GenSigSendType" SG_ 921 CVC_Immo_Byte_2 1;
BA_ "GenSigSendType" SG_ 921 CVC_Immo_Byte_3 1;
BA_ "GenSigSendType" SG_ 921 CVC_Immo_Byte_4 1;
BA_ "GenSigSendType" SG_ 921 CVC_Immo_Byte_5 1;
BA_ "GenSigSendType" SG_ 921 CVC_Immo_Byte_6 1;
BA_ "GenSigSendType" SG_ 921 CVC_Immo_Byte_7 1;
BA_ "GenSigSendType" SG_ 922 CVC_B_Immo_Byte_0 1;
BA_ "GenSigSendType" SG_ 922 CVC_B_Immo_Byte_1 1;
BA_ "GenSigSendType" SG_ 922 CVC_B_Immo_Byte_2 1;
BA_ "GenSigSendType" SG_ 922 CVC_B_Immo_Byte_3 1;
BA_ "GenSigSendType" SG_ 922 CVC_B_Immo_Byte_4 1;
BA_ "GenSigSendType" SG_ 922 CVC_B_Immo_Byte_5 1;
BA_ "GenSigSendType" SG_ 922 CVC_B_Immo_Byte_6 1;
BA_ "GenSigSendType" SG_ 922 CVC_B_Immo_Byte_7 1;
BA_ "InvalidValue" SG_ 925 ALIVE_CVC_AHB_Sts "Fh";
BA_ "InvalidValue" SG_ 1004 ALIVE_CVC_PanicEvent "Fh";
BA_ "GenSigSendType" SG_ 1004 CVC_PanicEventTrigger 7;
BA_ "GenSigSendType" SG_ 1004 CVC_PanicEventSource 7;
BA_ "GenSigSendType" SG_ 1004 CVC_PanicEventStatus 7;
BA_ "GenSigSendType" SG_ 1004 CVC_PanicEventCounter 7;
BA_ "GenSigStartValue" SG_ 1009 CVC_AmbientLightIntensityBrightn 50;
BA_ "GenSigSendType" SG_ 1009 CVC_AmbientLightIntensityBrightn 1;
BA_ "InvalidValue" SG_ 1011 ALIVE_CVC_DKSettingStatus "Fh";
BA_ "InvalidValue" SG_ 1015 ALIVE_CVC_MFS_Control_Button "Fh";
BA_ "GenSigSendType" SG_ 1015 MFS_L_Lever_Control 4;
BA_ "GenSigSendType" SG_ 1015 MFS_L_LeverButton_Control 4;
BA_ "GenSigSendType" SG_ 1015 MFS_L_Failure 4;
BA_ "GenSigSendType" SG_ 1015 MFS_L_UpControl 4;
BA_ "GenSigSendType" SG_ 1015 MFS_L_DownControl 4;
BA_ "GenSigSendType" SG_ 1015 MFS_L_LeftControl 4;
BA_ "GenSigSendType" SG_ 1015 MFS_L_RightControl 4;
BA_ "GenSigSendType" SG_ 1015 MFS_LIN_error 4;
BA_ "GenSigSendType" SG_ 1015 MFS_R_Lever_Control 4;
BA_ "GenSigSendType" SG_ 1015 MFS_R_LeverButton_Control 4;
BA_ "GenSigSendType" SG_ 1015 MFS_R_Failure 4;
BA_ "GenSigSendType" SG_ 1015 MFS_R_UpControl 4;
BA_ "GenSigSendType" SG_ 1015 MFS_R_DownControl 4;
BA_ "GenSigSendType" SG_ 1015 MFS_R_LeftControl 4;
BA_ "GenSigSendType" SG_ 1015 MFS_R_RightControl 4;
BA_ "GenSigSendType" SG_ 1015 MFS_Delta_Scroll_Wheel_Left 4;
BA_ "GenSigSendType" SG_ 1015 MFS_Delta_Scroll_Wheel_Right 4;
BA_ "GenSigSendType" SG_ 1015 MFS_Scroll_Wheel_Left_Direction 4;
BA_ "GenSigSendType" SG_ 1015 MFS_Scroll_Wheel_Right_Direction 4;
BA_ "GenSigSendType" SG_ 1015 MFS_Scroll_Wheel_Left_Press 4;
BA_ "GenSigSendType" SG_ 1015 MFS_Scroll_Wheel_Right_Press 4;
BA_ "GenSigSendType" SG_ 1015 MFS_Scroll_Wheel_Left_Valid 4;
BA_ "GenSigSendType" SG_ 1015 MFS_Scroll_Wheel_Right_Valid 4;
BA_ "GenSigSendType" SG_ 1015 MFS_Scroll_Wheel_Left_ID 4;
BA_ "GenSigSendType" SG_ 1015 MFS_Scroll_Wheel_Right_ID 4;
BA_ "InvalidValue" SG_ 1017 ALIVE_MHU_DKConfiguration "Fh";
BA_ "SystemSignalLongSymbol" SG_ 1017 MHU_SET_UserSettingApproachUnloc "MHU_SET_UserSettingApproachUnlock";
BA_ "SystemSignalLongSymbol" SG_ 1017 MHU_SET_LockUnlockDriveCfg_Phone "MHU_SET_LockUnlockDriveCfg_PhoneKey";
BA_ "GenSigStartValue" SG_ 1022 CVC_RLS_SensitivityLevelSet 1;
BA_ "GenSigStartValue" SG_ 1026 CVC_B_SET_DayTimeRunningLight 1;
BA_ "GenSigStartValue" SG_ 1026 CVC_B_SET_RearFogLight 3;
BA_ "GenSigStartValue" SG_ 1026 CVC_B_SET_FrontFogLight 3;
BA_ "GenSigStartValue" SG_ 1026 CVC_B_SET_WelcomeDimmingHeadligh 3;
BA_ "SystemSignalLongSymbol" SG_ 1026 CVC_B_SET_WelcomeDimmingHeadligh "CVC_B_SET_WelcomeDimmingHeadlight";
BA_ "GenSigStartValue" SG_ 1026 CVC_B_SET_FootwellLightMode 2;
BA_ "GenSigStartValue" SG_ 1026 CVC_B_SET_ExteriorLight 4;
BA_ "GenSigStartValue" SG_ 1026 CVC_B_SET_TRWarningSignals 3;
BA_ "GenSigStartValue" SG_ 1026 CVC_B_SET_FrontDomeLamp 3;
BA_ "SystemSignalLongSymbol" SG_ 1026 CVC_B_SET_Welcome_Farewell_Anima "CVC_B_SET_Welcome_Farewell_Animation";
BA_ "GenSigStartValue" SG_ 1026 CVC_B_SET_Auto_Leveling 1;
BA_ "GenSigSendType" SG_ 1032 CVC_SET_MirrorAuto 1;
BA_ "GenSigSendType" SG_ 1032 CVC_SET_MirrorAutoUnfold 1;
BA_ "GenSigSendType" SG_ 1032 CVC_SET_WLC 1;
BA_ "GenSigSendType" SG_ 1032 CVC_SET_AutoRearWiper 1;
BA_ "GenSigSendType" SG_ 1032 CVC_SET_RearHeatedWindow 1;
BA_ "GenSigSendType" SG_ 1032 CVC_TPMSReset 1;
BA_ "GenSigSendType" SG_ 1032 CVC_SET_MirrorDefaultSetting 1;
BA_ "GenSigSendType" SG_ 1032 CVC_SET_MirrorReverseLink 1;
BA_ "GenSigStartValue" SG_ 1032 CVC_SET_AntiTheftMode 3;
BA_ "GenSigSendType" SG_ 1032 CVC_SET_AntiTheftMode 1;
BA_ "GenSigSendType" SG_ 1032 CVC_SET_WLCReminder 1;
BA_ "GenSigSendType" SG_ 1032 CVC_SET_ClimateKeepOn 1;
BA_ "GenSigSendType" SG_ 1032 CVC_SET_WLC2 1;
BA_ "GenSigSendType" SG_ 1032 CVC_SET_WLC2Reminder 1;
BA_ "GenSigSendType" SG_ 1032 CVC_SET_WLC_Phoneforgetalert 1;
BA_ "GenSigSendType" SG_ 1032 CVC_SteeringWheel_Adjust_Req 3;
BA_ "GenSigStartValue" SG_ 1032 CVC_SteeringWheelPosX_Req 50;
BA_ "GenSigSendType" SG_ 1032 CVC_SteeringWheelPosX_Req 3;
BA_ "GenSigStartValue" SG_ 1032 CVC_SteeringWheelPosY_Req 50;
BA_ "GenSigSendType" SG_ 1032 CVC_SteeringWheelPosY_Req 3;
BA_ "GenSigSendType" SG_ 1033 TBOX_IntrusionAlertStatus 1;
BA_ "InvalidValue" SG_ 1036 ALIVE_CVC_B_SEAT_CONTROL "Fh";
BA_ "GenSigStartValue" SG_ 1050 MHU_SteeringWheel_Telescope 20;
BA_ "GenSigSendType" SG_ 1050 MHU_SteeringWheel_Telescope 2;
BA_ "GenSigSendType" SG_ 1050 MHU_SteeringWheel_EasyEntry 2;
BA_ "GenSigStartValue" SG_ 1050 MHU_SteeringWheel_Angle 21;
BA_ "GenSigSendType" SG_ 1050 MHU_SteeringWheel_Angle 2;
BA_ "GenSigSendType" SG_ 1050 MHU_SteeringWheel_Heater 2;
BA_ "GenSigSendType" SG_ 1050 MHU_SteerElecAdj_Req 2;
BA_ "GenSigStartValue" SG_ 1066 CVC_FLSeatTrackPos_Req 65;
BA_ "GenSigStartValue" SG_ 1066 CVC_FLSeatTiltPos_Req 1;
BA_ "GenSigStartValue" SG_ 1066 CVC_FLSeatHeightPos_Req 2;
BA_ "GenSigStartValue" SG_ 1066 CVC_FLSeatReclinePos_Req 42;
BA_ "InvalidValue" SG_ 1074 ALIVE_CVC_B_FOTA_STATUS "Fh";
BA_ "InvalidValue" SG_ 1082 ALIVE_CVC_CVC_B_info "Fh";
BA_ "GenSigStartValue" SG_ 1082 CVC_PowerRegenGaugeDisplay 100;
BA_ "GenSigStartValue" SG_ 1082 CVC_Regen_available 1;
BA_ "GenSigSendType" SG_ 1112 CVC_AmbientLightColorZoneReq 1;
BA_ "GenSigSendType" SG_ 1112 CVC_AmbientLightColorRed 1;
BA_ "GenSigSendType" SG_ 1112 CVC_AmbientLightColorGreen 1;
BA_ "GenSigSendType" SG_ 1112 CVC_AmbientLightColorBlue 1;
BA_ "GenSigSendType" SG_ 1113 CVC_AmbLightIntensityZoneReq 1;
BA_ "GenSigSendType" SG_ 1113 CVC_AmbLightIntensityTypeReq 1;
BA_ "GenSigSendType" SG_ 1113 CVC_AmbLightIntensityReq 1;
BA_ "GenSigSendType" SG_ 1113 CVC_AmbLightIntensityTimingT1Req 1;
BA_ "GenSigSendType" SG_ 1113 CVC_AmbLightIntensityTimingT2Req 1;
BA_ "GenSigSendType" SG_ 1113 CVC_AmbLightIntensityTimingT3Req 1;
BA_ "GenSigSendType" SG_ 1113 CVC_AmbLightIntensityTimingT4Req 1;
BA_ "GenSigSendType" SG_ 1113 CVC_AmbLightIntensityTimingN2Req 1;
BA_ "GenSigSendType" SG_ 1113 CVC_AmbLightIntensityTimingN1Req 1;
BA_ "GenSigSendType" SG_ 1114 CVC_Z3_AmbLightZoneFLReq 1;
BA_ "GenSigSendType" SG_ 1114 CVC_Z1_AmbLightZoneIPDrivReq 1;
BA_ "GenSigSendType" SG_ 1114 CVC_Z2_AmbLightZoneFRReq 1;
BA_ "GenSigSendType" SG_ 1114 CVC_Z5_AmbLightZoneRLReq 1;
BA_ "GenSigSendType" SG_ 1114 CVC_Z4_AmbLightZoneRRReq 1;
BA_ "GenSigSendType" SG_ 1114 CVC_Z3B_AmbLightZoneFLReq 1;
BA_ "GenSigSendType" SG_ 1114 CVC_Z2B_AmbLightZoneFRReq 1;
BA_ "GenSigSendType" SG_ 1114 CVC_Z6_AmbLightZoneIPPassReq 1;
BA_ "GenSigSendType" SG_ 1114 CVC_Z6B_AmbLightZoneIPPassReq 1;
BA_ "GenSigSendType" SG_ 1114 CVC_Z7_AmbLightZoneConsLReq 1;
BA_ "GenSigSendType" SG_ 1114 CVC_Z7B_AmbLightZoneConsLReq 1;
BA_ "GenSigSendType" SG_ 1114 CVC_Z8_AmbLightZoneConsRReq 1;
BA_ "GenSigSendType" SG_ 1114 CVC_Z8B_AmbLightZoneConsRReq 1;
BA_ "GenSigSendType" SG_ 1114 CVC_Z9_AmbLightZoneConsRLReq 1;
BA_ "GenSigSendType" SG_ 1114 CVC_Z10_AmbLightZoneConsRRReq 1;
BA_ "GenSigSendType" SG_ 1114 CVC_Z5B_AmbLightZoneRLReq 1;
BA_ "GenSigSendType" SG_ 1114 CVC_Z4B_AmbLightZoneRRReq 1;
BA_ "GenSigTimeoutTime_ALL" SG_ 1117 CRC_FCAM_Heater_Request 1000;
BA_ "InvalidValue" SG_ 1117 ALIVE_FCAM_Heater_Request "Fh";
BA_ "GenSigTimeoutTime_ALL" SG_ 1117 ALIVE_FCAM_Heater_Request 1000;
BA_ "InvalidValue" SG_ 1117 FCAM_HeaterActivation_Req "0h";
BA_ "GenSigTimeoutTime_ALL" SG_ 1117 FCAM_HeaterActivation_Req 1000;
BA_ "InvalidValue" SG_ 1171 ALIVE_BMS_WarnMsg "Fh";
BA_ "InvalidValue" SG_ 1171 BMS_Warning_DeltaTemperature "FFh";
BA_ "InvalidValue" SG_ 1171 BMS_Warning_BDUTemperatureSts "FFh";
BA_ "GenSigSendType" SG_ 1257 CVC_RHMirrorAdjustmentSet 1;
BA_ "GenSigSendType" SG_ 1257 CVC_LHMirrorAdjustmentSet 1;
BA_ "GenSigSendType" SG_ 1257 CVC_SET_MirrorFold_Right 1;
BA_ "GenSigSendType" SG_ 1257 CVC_SET_MirrorFold_Left 1;
BA_ "GenSigSendType" SG_ 1257 RHMirror_Adjustment_Req 1;
BA_ "GenSigSendType" SG_ 1257 LHMirror_Adjustment_Req 1;
BA_ "InvalidValue" SG_ 1257 CVC_SET_LeftMirrorPosX "FFh";
BA_ "GenSigStartValue" SG_ 1257 CVC_SET_LeftMirrorPosX 255;
BA_ "GenSigSendType" SG_ 1257 CVC_SET_LeftMirrorPosX 1;
BA_ "InvalidValue" SG_ 1257 CVC_SET_LeftMirrorPosY "FFh";
BA_ "GenSigStartValue" SG_ 1257 CVC_SET_LeftMirrorPosY 255;
BA_ "GenSigSendType" SG_ 1257 CVC_SET_LeftMirrorPosY 1;
BA_ "InvalidValue" SG_ 1257 CVC_SET_RightMirrorPosX "FFh";
BA_ "GenSigStartValue" SG_ 1257 CVC_SET_RightMirrorPosX 255;
BA_ "GenSigSendType" SG_ 1257 CVC_SET_RightMirrorPosX 1;
BA_ "InvalidValue" SG_ 1257 CVC_SET_RightMirrorPosY "FFh";
BA_ "GenSigStartValue" SG_ 1257 CVC_SET_RightMirrorPosY 255;
BA_ "GenSigSendType" SG_ 1257 CVC_SET_RightMirrorPosY 1;
BA_ "GenSigSendType" SG_ 1879 CVC_TMSMode 1;
BA_ "GenSigSendType" SG_ 1879 CVC_HVCHPowerLim 1;
BA_ "GenSigSendType" SG_ 1879 CVC_HVCHOffCode 1;
BA_ "GenSigSendType" SG_ 1879 CVC_AirPTCOffCode 1;
BA_ "GenSigSendType" SG_ 1879 CVC_CompOffCode 1;
BA_ "InvalidValue" SG_ 1889 EAC_power_lim "FFh";
BA_ "InvalidValue" SG_ 1889 EAC_speed "FFh";
BA_ "InvalidValue" SG_ 1889 EAC_target_speed "FFh";
BA_ "GenSigSendType" SG_ 1968 Sync_TripCnt 2;
BA_ "GenSigSendType" SG_ 1968 Sync_ResetCnt 2;
BA_ "GenSigSendType" SG_ 1968 Sync_MAC 2;
BA_ "GenSigSendType" SG_ 168 BCMRE_Climate_RearAirDistFlapPos 1;
BA_ "GenSigSendType" SG_ 168 BCMRE_Climate_RearTempFlapPos 1;
BA_ "GenSigSendType" SG_ 168 BCMRE_Climate_RearAirRecirculati 1;
BA_ "SystemSignalLongSymbol" SG_ 168 BCMRE_Climate_RearAirRecirculati "BCMRE_Climate_RearAirRecirculation_Sts";
BA_ "GenSigSendType" SG_ 168 BCMRE_Climate_RearAirDistFlapSts 1;
BA_ "GenSigSendType" SG_ 168 BCMRE_Climate_RearTempFlapSts 1;
BA_ "GenSigSendType" SG_ 168 BCMRE_Climate_RearAirRecirc_0000 1;
BA_ "SystemSignalLongSymbol" SG_ 168 BCMRE_Climate_RearAirRecirc_0000 "BCMRE_Climate_RearAirRecirculation_FlapPos";
BA_ "GenSigSendType" SG_ 168 BCMRE_Climate_FrontPassAirMode_F 1;
BA_ "SystemSignalLongSymbol" SG_ 168 BCMRE_Climate_FrontPassAirMode_F "BCMRE_Climate_FrontPassAirMode_FlapPos";
BA_ "GenSigSendType" SG_ 168 BCMRE_Climate_FrontByPassAirMode 1;
BA_ "SystemSignalLongSymbol" SG_ 168 BCMRE_Climate_FrontByPassAirMode "BCMRE_Climate_FrontByPassAirMode_FlapPos";
BA_ "GenSigSendType" SG_ 168 BCMRE_Climate_RearFootAirMode_Fl 1;
BA_ "SystemSignalLongSymbol" SG_ 168 BCMRE_Climate_RearFootAirMode_Fl "BCMRE_Climate_RearFootAirMode_FlapPos";
BA_ "GenSigSendType" SG_ 168 BCMRE_Climate_RLTemp_FlapPos 1;
BA_ "GenSigSendType" SG_ 168 BCMRE_Climate_RRTemp_FlapPos 1;
BA_ "GenSigSendType" SG_ 168 BCMRE_Climate_FrontPassAirMode_S 1;
BA_ "SystemSignalLongSymbol" SG_ 168 BCMRE_Climate_FrontPassAirMode_S "BCMRE_Climate_FrontPassAirMode_Sts";
BA_ "GenSigSendType" SG_ 168 BCMRE_Climate_FrontByPassAi_0000 1;
BA_ "SystemSignalLongSymbol" SG_ 168 BCMRE_Climate_FrontByPassAi_0000 "BCMRE_Climate_FrontByPassAirMode_Sts";
BA_ "GenSigSendType" SG_ 168 BCMRE_Climate_RearFootAirMode_St 1;
BA_ "SystemSignalLongSymbol" SG_ 168 BCMRE_Climate_RearFootAirMode_St "BCMRE_Climate_RearFootAirMode_Sts";
BA_ "GenSigSendType" SG_ 168 BCMRE_Climate_RLTemp_Sts 1;
BA_ "GenSigSendType" SG_ 168 BCMRE_Climate_RRTemp_Sts 1;
BA_ "InvalidValue" SG_ 168 BCMRE_Climate_RearBlowerRelay_St "3h";
BA_ "GenSigStartValue" SG_ 168 BCMRE_Climate_RearBlowerRelay_St 3;
BA_ "GenSigSendType" SG_ 168 BCMRE_Climate_RearBlowerRelay_St 1;
BA_ "SystemSignalLongSymbol" SG_ 168 BCMRE_Climate_RearBlowerRelay_St "BCMRE_Climate_RearBlowerRelay_Sts";
BA_ "GenSigSendType" SG_ 168 BCMRE_Climate_AirDistFlapRHPos 1;
BA_ "GenSigSendType" SG_ 168 BCMRE_Climate_AirDistFlapRHSts 1;
BA_ "GenSigSendType" SG_ 168 BCMRE_Climate_BypassFlap 1;
BA_ "GenSigSendType" SG_ 168 BCMRE_Climate_BypassFlapSts 1;
BA_ "GenSigSendType" SG_ 168 BCMRE_Climate_AirDistRearFlapPos 1;
BA_ "GenSigSendType" SG_ 168 BCMRE_Climate_AirDistRearFlapSts 1;
BA_ "GenSigSendType" SG_ 168 BCMRE_Climate_RearDuctFlapPos 1;
BA_ "GenSigSendType" SG_ 168 BCMRE_Climate_RearDuctFlapSts 1;
BA_ "InvalidValue" SG_ 172 ALIVE_BCMRE_DoorStatus "Fh";
VAL_ 267 TrailerInput 0 "Trailer synchronous with CAN" 1 "Trailer synchronous with HW input" 2 "Reserved" 3 "Invalid" ;
VAL_ 267 TrailerSystemError 0 "No error" 1 "Error" 2 "Reserved" 3 "Invalid" ;
VAL_ 267 TRM_VoltageStatus 0 "No failure" 1 "Overvoltage" 2 "Undervoltage" 3 "Invalid" ;
VAL_ 267 TRM_STAT_BrakeLight 0 "OFF" 1 "ON" 2 "Reserved" 3 "Signal invalid" ;
VAL_ 267 TRM_STAT_FogLampRear 0 "OFF" 1 "ON" 2 "Failure" 3 "Signal invalid" ;
VAL_ 267 TRM_STAT_PositionLight 0 "PositionLight OFF" 1 "PositionLight ON" 2 "PositionLight failure" 3 "Signal invalid" ;
VAL_ 267 TRM_STAT_TurnIndicators 0 "OFF" 1 "Left turn lamp ON" 2 "Right turn lamp ON" 3 "Both turn lamps ON" 4 "Left turn lamp defect" 5 "Right turn lamp defect" 6 "Both turn lamp defect" 15 "Signal invalid" ;
VAL_ 267 TRM_STAT_ReverseLight 0 "OFF" 1 "ON" 2 "Reserved" 3 "Signal invalid" ;
VAL_ 267 TRM_STAT_HWBrakeLightInput 0 "Brakel Light Input not active TRM" 1 "Brakel Light Input active TRM" 2 "Reserved" 3 "Signal invalid" ;
VAL_ 267 TRM_STAT_HWIndicatorInput 0 "Indicator Input not active TRM" 1 "Indicator Input active TRM" 2 "Reserved" 3 "Signal invalid" ;
VAL_ 267 TRM_STAT_HWPosLightInput 0 "PosLight nput not active TRM" 1 "PosLight input active TRM" 2 "Reserved" 3 "Signal invalid" ;
VAL_ 274 RemoteFunctionState 0 "Normal function" 1 "Remote function" 2 "Reserved" 3 "Signal Invalid" ;
VAL_ 274 CVC_STAT_BLS 0 "BLS not pressed" 1 "BLS pressed" 2 "Reserved" 3 "Signal invalid" ;
VAL_ 274 Vehicle_Operation_State 0 "OFF(Comfort Enable)" 1 "ACC (Park)" 2 "ON (Driver Present)" 3 "Engine start (eMotor running)" 4 "SW Update OTA" 5 "Reserved" 6 "Reserved" 7 "Signal Invalid" ;
VAL_ 284 TBOX_FOTA_STAT_TerminalReq 0 "OFF(Comfort Enable)" 1 "ACC(Park)" 2 "ON (Driver Present)" 3 "FOTA" 4 "Reserved" 5 "Reserved" 6 "No action" 7 "Signal Invalid" ;
VAL_ 307 SRR_RR_BSD_check 0 "Available" 1 "Temporarily not available" 2 "Permanently not available" ;
VAL_ 307 SRR_RR_BSD_state 0 "OFF State" 1 "Stand by state" 2 "Armed state" 3 "Static Warning" 4 "Flashing Warning" 5 "Malfunction stage" 6 "Reserved" 7 "Invalid" ;
VAL_ 307 SRR_RR_BSD_AudChime_Feed 0 "Off" 1 "On" ;
VAL_ 307 SRR_RR_BSD_IndLeft 0 "Indicator output off" 1 "Indicator On(warning stage - 1)" 2 "Indicator flashing(warning stage - 2)" 3 "Sensor Fault" ;
VAL_ 307 SRR_RR_BSD_IndRight 0 "Indicator output off" 1 "Indicator On(warning stage - 1)" 2 "Indicator flashing(warning stage - 2)" 3 "Sensor Fault" ;
VAL_ 307 SRR_RR_BSD_SndWarn 0 "Sound Warning disable" 1 "Left Sound Warning enable" 2 "Right Sound Warning enable" 3 "Left and Right Sound Warning enable" ;
VAL_ 307 SRR_RR_BSD_Mode_Feed 0 "Off" 1 "On" ;
VAL_ 307 SRR_RR_BSD_sens_Feed 0 "Early" 1 "Normal" 2 "Late" 3 "Reserved" ;
VAL_ 307 SRR_RR_RCTA_IndRight 0 "Indicator output off" 1 "Indicator On(warning stage - 1)" 2 "Indicator flashing(warning stage - 2)" 3 "Reserved" ;
VAL_ 307 SRR_RR_RCTA_IndLeft 0 "Indicator output off" 1 "Indicator On(warning stage - 1)" 2 "Indicator flashing(warning stage - 2)" 3 "Reserved" ;
VAL_ 307 SRR_RR_RCTA_sens_Feed 0 "Early" 1 "Normal" 2 "Late" 3 "Reserved" ;
VAL_ 307 SRR_RR_RCTA_state 0 "OFF State" 1 "Stand by state" 2 "Armed state" 3 "Warning stage" 4 "Malfunction Stage" ;
VAL_ 307 SRR_RR_RCTA_SndWarn 0 "Sound Warning disable" 1 "Left Sound Warning enable" 2 "Right Sound Warning enable" 3 "Left and Right Sound Warning enable" ;
VAL_ 307 SRR_RR_RCTA_Mode_Feed 0 "Off'" 1 "On" 2 "Reserved" ;
VAL_ 307 SRR_RR_RCTA_check 0 "Available" 1 "Temporarily not available" 2 "Permanently not available" ;
VAL_ 307 SRR_RR_DOW_SndWarn 0 "Sound Warning disable" 1 "Left Sound Warning enable" 2 "Right Sound Warning enable" 3 "Left and Right Sound Warning enable" ;
VAL_ 307 SRR_RR_DOW_WarnRight 0 "No warning" 1 "Warning Level 1" 2 "Warning Level 2" 3 "Reserved" ;
VAL_ 307 SRR_RR_DOW_WarnLeft 0 "No warning" 1 "Warning Level 1" 2 "Warning Level 2" 3 "Reserved" ;
VAL_ 307 SRR_RR_DOW_check 0 "Available" 1 "Temporarily not available" 2 "Permanently not available" ;
VAL_ 307 SRR_RR_DOW_state 0 "OFF State" 1 "Stand by state" 2 "Armed state" 3 "Warning stage" 4 "Malfunction stage" ;
VAL_ 307 SRR_RR_DOW_Mode_Feed 0 "Off" 1 "Warning Only" 2 "Warning/Door Lock both" 3 "Reserved" ;
VAL_ 307 SRR_RR_Right_block 0 "No Blockage" 1 "Blockaged" ;
VAL_ 307 SRR_RR_Left_block 0 "No Blockage" 1 "Blockaged" ;
VAL_ 307 Obj_Class_RL 0 "unknown" 1 "big car" 2 "small car" 3 "two wheels" 4 "pedestrain" 5 "Reserved" 6 "Reserved" 7 "Reserved" ;
VAL_ 307 Obj_Class_RR 0 "unknown" 1 "big car" 2 "small car" 3 "two wheels" 4 "pedestrain" 5 "Reserved" 6 "Reserved" 7 "Reserved" ;
VAL_ 307 SRR_RR_RCTB_Mode_Feed 0 "Off" 1 "On" ;
VAL_ 307 SRR_RR_RCTB_State 0 "OFF State" 1 "Stand by state" 2 "Armed state" 3 "Warning stage" 4 "Malfunction stage" ;
VAL_ 307 SRR_RR_RCTB_Check 0 "Available" 1 "Temporarily not available" 2 "Permanently not available" ;
VAL_ 307 SRR_RR_RCTB_Braking_Flag 0 "No brake request" 1 "Pre-fill request" 2 "Brake request" ;
VAL_ 323 Ionizer_Set 0 "No request" 1 "OFF" 2 "ON" 3 "Invalid" ;
VAL_ 323 RearSOV_Req 0 "Invalid" 1 "SOV Open" 2 "SOV Close" ;
VAL_ 323 RearBlowerRelay_Set 0 "No request" 1 "OFF" 2 "ON" 3 "Invalid" ;
VAL_ 382 SAS_SASStsSnsr 0 "sensor value Invalid" 1 "sensor value valid" ;
VAL_ 382 SAS_SteerWhlRotSpdStatus 0 "Invalid" 1 "Valid" ;
VAL_ 382 SAS_SASFailure 0 "Failure" 1 "No Failure" ;
VAL_ 382 SAS_Calibrated 0 "Not Calibrated" 1 "Calibrated" ;
VAL_ 382 SAS_SteerWheelAngleValid 0 "Valid" 1 "Invalid" ;
VAL_ 519 SR_Undervoltage_Fault_Sts 0 "Normal" 1 "Fault" ;
VAL_ 519 SR_Overvoltage_Fault_Sts 0 "Normal" 1 "Fault" ;
VAL_ 519 SR_SLEEP_RQ 0 "Sleep Not Ready" 1 "Ready to Sleep" ;
VAL_ 519 SR_Position 0 "Unknown -Default" 1 "All Closed" 2 "All Closed To Tilt" 3 "Tilt" 4 "Tilt to Half Open" 5 "Half Open" 6 "Half Open to Open" 7 "ALL Open" ;
VAL_ 519 SR_Motor_Running_Sts 0 "Stop" 1 "Open Direction" 2 "Close Direction" 3 "Not Used" ;
VAL_ 519 SR_MotorReverse_Fault_Sts 0 "Normal" 1 "Fault" ;
VAL_ 519 SR_Hall_Fault_Sts 0 "Normal" 1 "Fault" ;
VAL_ 519 SR_Normalisation_Sts 0 "Normalised" 1 "Not normalised" ;
VAL_ 519 SR_Relay_Fault 0 "Normal" 1 "Fault" ;
VAL_ 519 SR_Commu_Fault_Sts 0 "Normal" 1 "Fault" ;
VAL_ 519 SR_Initialisation_Status 0 "Initialised" 1 "Not initialised" ;
VAL_ 519 SR_Ctrl_Result 0 "No Response" 1 "Running" 2 "Succeed" 3 "Failed" ;
VAL_ 519 SR_ThermalProtection_Fault_Sts 0 "Normal" 1 "Fault" ;
VAL_ 519 SR_Operation_Stat 0 "Idle/Not pressed" 1 "Manual Slide Open" 2 "Manual Slide Closed" 3 "ManualTilt Open" 4 "Manual Tilt Closed" 5 "Auto Slide Open" 6 "Auto Slide Closed" 7 "Auto Tilt Open" 8 "Auto Tilt Closed" ;
VAL_ 519 SR_Error_RSP 0 "No Error" 1 "Error" ;
VAL_ 519 BCM_AutoSunroof_Sts 0 "OFF" 1 "Glass Only" 2 "Glass & Shade" 3 "Signal invalid" ;
VAL_ 524 CVC_OdometerV 0 "valid" 1 "invalid" ;
VAL_ 525 ABSFailed 0 "No fault" 1 "Fault" ;
VAL_ 525 ABSActive 0 "Inactive" 1 "Active" ;
VAL_ 525 ESC_VehicleStandstill 0 "NO_VEHICLE_STANDSTILL" 1 "VEHICLE_STANDSTILL" ;
VAL_ 525 WCBS_VehicleSpeedValid 0 "Valid" 1 "Invalid" ;
VAL_ 525 ESC_VehicleHoldStat 0 "No vehicle hold" 1 "vehicle hold" 2 "reserved" 3 "reserved" ;
VAL_ 525 ABS_EBDFailed 0 "EBD Normal" 1 "EBD Failed" ;
VAL_ 525 ABS_HAZActive 0 "Emergency brake light off" 1 "Emergency brake light on" ;
VAL_ 525 ABS_LowBrakeFluid 0 "no failure" 1 "failure" ;
VAL_ 525 EBDActive 0 "Inactive" 1 "Active" ;
VAL_ 525 WCBS_Veh_DriveCondition 0 "Vehicle is stationary" 1 "Vehicle is moving forward" 2 "Vehicle is moving reverse" 3 "Vehicle is stationary rear axle rol" 4 "Vehicle is stationary front axle roll" 5 "Vehicle is stationary all axle roll" 6 "reserved" 7 "Signal invalid" ;
VAL_ 533 BMS_BatBalance_ERR 0 "Error" 1 "normal" ;
VAL_ 533 BMS_Balance_STS 0 "Inactive" 1 "active" ;
VAL_ 533 BMS_IGN_Sts 0 "OFF" 1 "ON" ;
VAL_ 533 BMS_HWCrash_Sts 0 "No Crash" 1 "Crash" ;
VAL_ 533 BMS_HVIL_STS 0 "Closed" 1 "Open & short to battery" 2 "short to ground" 3 "Signal invalid" ;
VAL_ 533 BMS_HVOnOff_STS 0 "HV Off" 1 "Precharge" 2 "HV On" 3 "Fail to HV on" ;
VAL_ 533 BMS_ERR_LEV 0 "No error" 1 "Warning" 2 "Limp Home" 3 "Power down without FTTI" 4 "Delay power down with FTTI" 5 "Emergency off condition" 6 "Fault, needs to shutdown and wakeup" 7 "Battery locked - reserved" ;
VAL_ 533 BMS_Sys_STS 0 "Initialization of power on, self-checking" 1 "Self-check passes, can be high-voltage" 2 "Successful High Voltage Power Up" 3 "Successful Power Down of HV" 4 "Power Down process" 5 "Successful Power Down" 6 "BCU Sleep mode" 7 "Failure, unable to operate" 8 "Invalid" ;
VAL_ 533 BMS_ISU_Status 0 "Normal (> 250 kOhms)" 1 "Level1 (<250 kOhms ~ >100 kOhms)" 3 "Level3 (<100 kOhms)" ;
VAL_ 533 BMS_HV_Sts 0 "HV Off" 1 "Pre Charge" 2 "HV On" 3 "Super_Fast_Charge" 4 "AC Charge" 5 "Undefined" 6 "Undefined" 7 "Undefined" 8 "Undefined" 9 "Undefined" ;
VAL_ 536 CVC_PosLight_RR_Req 0 "OFF" 1 "ON" 2 "Reserved" 3 "Signal Invalid" ;
VAL_ 536 CVC_RearFogLamp_RL_Req 0 "OFF" 1 "ON" 2 "Reserved" 3 "Signal Invalid" ;
VAL_ 536 CVC_RearFogLamp_RR_Req 0 "OFF" 1 "ON" 2 "Reserved" 3 "Signal Invalid" ;
VAL_ 536 CVC_DaytimeRunningLight_FL_Req 0 "OFF" 1 "ON" 2 "Reserved" 3 "Signal Invalid" ;
VAL_ 536 CVC_DaytimeRunningLight_FR_Req 0 "OFF" 1 "ON" 2 "Reserved" 3 "Signal Invalid" ;
VAL_ 536 CVC_TurnIndicator_FL_Req 0 "OFF" 1 "ON" 2 "No request" 3 "Signal Invalid" ;
VAL_ 536 CVC_TurnIndicator_RL_Req 0 "OFF" 1 "ON" 2 "No request" 3 "Signal Invalid" ;
VAL_ 536 CVC_TurnIndicator_FR_Req 0 "OFF" 1 "ON" 2 "No request" 3 "Signal Invalid" ;
VAL_ 536 CVC_TurnIndicator_RR_Req 0 "OFF" 1 "ON" 2 "No request" 3 "Signal Invalid" ;
VAL_ 536 CVC_RLS_AutoLampRequest 0 "Lamp ON" 1 "Lamp OFF" ;
VAL_ 536 CVC_ReverseLamp_RL_Req 0 "OFF" 1 "ON" 2 "Reserved" 3 "Signal Invalid" ;
VAL_ 536 CVC_ReverseLamp_RR_Req 0 "OFF" 1 "ON" 2 "Reserved" 3 "Signal Invalid" ;
VAL_ 536 CVC_BrakeLight_RL_Req 0 "OFF" 1 "ON" 2 "Reserved" 3 "Signal Invalid" ;
VAL_ 536 CVC_BrakeLight_RR_Req 0 "OFF" 1 "ON" 2 "Reserved" 3 "Signal Invalid" ;
VAL_ 536 CVC_BrakeLight_Center_Req 0 "OFF" 1 "ON" 2 "Reserved" 3 "Signal Invalid" ;
VAL_ 536 CVC_LicensePlateLamp_RE_Req 0 "OFF" 1 "ON" 2 "Reserved" 3 "Signal Invalid" ;
VAL_ 536 CVC_HighBeam_FL_Req 0 "OFF" 1 "ON" 2 "Reserved" 3 "Signal Invalid" ;
VAL_ 536 CVC_HighBeam_FR_Req 0 "OFF" 1 "ON" 2 "Reserved" 3 "Signal Invalid" ;
VAL_ 536 CVC_LowBeam_FL_Req 0 "OFF" 1 "ON" 2 "Reserved" 3 "Signal Invalid" ;
VAL_ 536 CVC_LowBeam_FR_Req 0 "OFF" 1 "ON" 2 "Reserved" 3 "Signal Invalid" ;
VAL_ 536 CVC_PosLight_RL_Req 0 "OFF" 1 "ON" 2 "Reserved" 3 "Signal Invalid" ;
VAL_ 536 CVC_MirrorLED_FL_Req 0 "OFF" 1 "ON" 2 "Reserved" 3 "Signal invalid" ;
VAL_ 536 CVC_MirrorLED_FR_Req 0 "OFF" 1 "ON" 2 "Reserved" 3 "Signal invalid" ;
VAL_ 536 CVC_WelcomeFarewellLight_Req 0 "No request" 1 "Welcome mode 1 request" 2 "Welcome mode 2 request" 3 "Welcome mode 3 request" 4 "Farewell mode 1 request" 5 "Farewell mode 2 request" 6 "Farewell mode 3 request" 7 "Signal Invalid" ;
VAL_ 536 CVC_SignatureLight_RE_Req 0 "OFF" 1 "ON" 2 "Reserved" 3 "Signal invalid" ;
VAL_ 536 CVC_PosLight_FR_Req 0 "OFF" 1 "ON" 2 "Reserved" 3 "Signal Invalid" ;
VAL_ 536 CVC_PosLight_FL_Req 0 "OFF" 1 "ON" 2 "Reserved" 3 "Signal Invalid" ;
VAL_ 536 CVC_FrontFogLamp_FR_Req 0 "OFF" 1 "ON" 2 "Reserved" 3 "Signal Invalid" ;
VAL_ 536 CVC_FrontFogLamp_FL_Req 0 "OFF" 1 "ON" 2 "Reserved" 3 "Signal Invalid" ;
VAL_ 536 CVC_IndicatorMode_Req 0 "OFF" 1 "Left Signal" 2 "Right Signal" 3 "Manual Hazard" 4 "Emergency Hazard" 5 "Crash Hazard" 6 "OTA Flashing" 7 "Tailgate Flashing" 8 "Anti-theft Flashing" 15 "Signal Invalid" ;
VAL_ 536 CVC_ParkLight_RL_Req 0 "OFF" 1 "ON" 2 "Reserved" 3 "Signal Invalid" ;
VAL_ 536 CVC_ParkLight_RR_Req 0 "OFF" 1 "ON" 2 "Reserved" 3 "Signal Invalid" ;
VAL_ 536 CVC_SideMarkerLight_Req 0 "OFF" 1 "ON" 2 "Reserved" 3 "Invalid" ;
VAL_ 536 CVC_ParkLight_RM_Req 0 "OFF" 1 "ON" 2 "Reserved" 3 "Signal Invalid" ;
VAL_ 536 CVC_PosLight_RM_Req 0 "OFF" 1 "ON" 2 "Reserved" 3 "Signal Invalid" ;
VAL_ 539 CVC_Mirror_CourtesyLightReq 0 "OFF" 1 "ON" 2 "No Request" 3 "Signal Invalid" ;
VAL_ 539 CVC_CargoLightReq 0 "OFF" 1 "ON 1" 2 "Reserved" 3 "Signal Invalid" ;
VAL_ 539 CVC_BonnetLightReq 0 "OFF" 1 "ON 1" 2 "Reserved" 3 "Signal Invalid" ;
VAL_ 539 CVC_FLFootwellLightReq 0 "OFF" 1 "ON 1" 2 "Reserved" 3 "Signal Invalid" ;
VAL_ 539 CVC_FRFootwellLightReq 0 "OFF" 1 "ON 1" 2 "Reserved" 3 "Signal Invalid" ;
VAL_ 539 CVC_FrontDomeLampReq 0 "OFF" 1 "ON 1" 2 "Reserved" 3 "Signal Invalid" ;
VAL_ 539 CVC_Rear_2nd_DomeLampReq 0 "OFF" 1 "ON 1" 2 "Reserved" 3 "Signal Invalid" ;
VAL_ 539 CVC_FLScuffLightReq 0 "OFF" 1 "ON" 2 "Reserved" 3 "Signal Invalid" ;
VAL_ 539 CVC_FRScuffLightReq 0 "OFF" 1 "ON" 2 "Reserved" 3 "Signal Invalid" ;
VAL_ 539 CVC_FLProjectorLightReq 0 "OFF" 1 "ON" 2 "Reserved" 3 "Signal Invalid" ;
VAL_ 539 CVC_RLProjectorLightReq 0 "OFF" 1 "ON" 2 "Reserved" 3 "Signal Invalid" ;
VAL_ 539 CVC_RRProjectorLightReq 0 "OFF" 1 "ON" 2 "Reserved" 3 "Signal Invalid" ;
VAL_ 539 CVC_FRProjectorLightReq 0 "OFF" 1 "ON" 2 "Reserved" 3 "Signal Invalid" ;
VAL_ 539 CVC_Rear_3rd_DomeLampReq 0 "OFF" 1 "ON 1" 2 "Reserved" 3 "Invalid" ;
VAL_ 539 CVC_HazardLightReq 0 "OFF" 1 "ON 1" 2 "Reserved" 3 "Invalid" ;
VAL_ 541 CVC_AHL_Mode 0 "Inactive" 1 "Active" 2 "Error" 3 "Reserved" ;
VAL_ 541 CVC_AHL_STS 0 "OFF" 1 "ON" 2 "Reserved" 3 "Signal Invalid" ;
VAL_ 542 CVC_RearFogLampSts 0 "OFF" 1 "ON" 2 "Reserved" 3 "Signal Invalid" 4 "Fault" ;
VAL_ 542 CVC_ExteriorLightSts 0 "OFF" 1 "Parking" 2 "On" 3 "Auto" 4 "Invalid" ;
VAL_ 542 CVC_FollowMeHomeSts 0 "OFF" 1 "30 secs" 2 "60 secs" 3 "90 secs" 4 "120 secs" 5 "Signal Invalid" ;
VAL_ 542 CVC_WelcomeLightSts 0 "Vehicle Unlock" 1 "Driver walk toward" 2 "OFF" 3 "Signal invalid" ;
VAL_ 542 CVC_FrontFogLampSts 0 "OFF" 1 "ON" 2 "Reserved" 3 "Signal Invalid" 4 "Fault" ;
VAL_ 565 TRM_TowingDetected 0 "Towing not detected" 1 "Towing detected" 3 "Invalid" ;
VAL_ 565 TRM_TrailerDetected 0 "Trailer not detected" 1 "Trailer detected" 3 "Invalid" ;
VAL_ 592 BMS_CVC_PTCOnOff_Req 0 "OFF" 1 "ON" ;
VAL_ 592 BMS_CVC_ValveOnOff_Req 0 "close" 1 "open" ;
VAL_ 592 BMS_PreHeatCoolReq 0 "Precondition OFF" 1 "Precondition Heating ON" 2 "Precondition Cooling ON" 3 "Invalid value" ;
VAL_ 619 Sig_SPVer_L 1 "AVAC safety position is requested for vertical stepper motor" 2 "AVAC safety freeze is requested for vertical stepper motor" 3 "AVAC stepper motor is quit" ;
VAL_ 619 Sig_SPVer_R 1 "AVAC safety position is requested for vertical stepper motor" 2 "AVAC safety freeze is requested for vertical stepper motor" 3 "AVAC stepper motor is quit" ;
VAL_ 619 Sig_RefVer_LR 0 "AVAC Referencing Request" ;
VAL_ 662 PDU_DCDC_StsCtrl 0 "DCDC_OFF" 1 "DCDC_STANDBY" 2 "DCDC_ON" 3 "DCDC_RESERVED" 4 "DCDC_DEGRAEDED" 5 "DCDC_FAULT_SHUTDOWN" 6 "DCDC_EMEGENCY_SHUTDOWN" 7 "DCDC_SNA" ;
VAL_ 676 CVC_B_ESCOFF_SW_Sts 0 "No Action" 1 "ESC OFF" 2 "ESC ON" ;
VAL_ 676 CVC_B_CVC_CreepDisable_stt 0 "No request" 1 "Creep Disable request" ;
VAL_ 676 CVC_B_AVH_Req 0 "No Action" 1 "OFF()" 2 "ON()" ;
VAL_ 676 CVC_B_RegencyLevRequest 0 "No Request" 1 "OFF" 2 "Request Regency Leve1" 3 "Request Regency Leve2" ;
VAL_ 676 CVC_B_DM_SwitchModeSts 0 "No request" 1 "Comfort Mode" 2 "Eco Mode" 3 "Sport Mode" ;
VAL_ 676 CVC_LV_Batt_Charging_Req 0 "Disable" 1 "Enable" ;
VAL_ 676 CVC_B_Trailermode_Req 0 "No Action" 1 "OFF" 2 "ON" ;
VAL_ 746 CVC_Fan_Sts 0 "Closed" 1 "Low Speed" 2 "High speed" ;
VAL_ 746 CVC_EdrivePump_Sts 0 "Not Work" 1 "Working" 2 "Fault" ;
VAL_ 746 CVC_BatPump_Sts 0 "Not Work" 1 "Working" 2 "Fault" ;
VAL_ 760 DISP_DATE_WDAY 1 "Monday" 2 "Tuesday" 3 "Wednesday" 4 "Thursday" 5 "Friday" 6 "Saturday" 7 "Sunday" 15 "Signal invalid" ;
VAL_ 760 ST_DISP_CTI_DATE 0 "data not valid" 1 "data valid" 3 "UTC" 5 "winter time" 6 "Manually set time" 7 "summer time" 15 "signal invalid" ;
VAL_ 768 CVC_STAT_SyncClimateZone 0 "OFF" 1 "ON" 2 "Reserved" 3 "Signal invalid" ;
VAL_ 768 CVC_STAT_Auto 0 "OFF" 1 "ON" 2 "Reserved" 3 "Signal invalid" ;
VAL_ 768 CVC_STAT_Aircondition 0 "OFF" 1 "ON" 2 "Reserved" 3 "Signal invalid" ;
VAL_ 768 CVC_STAT_IonButton 0 "OFF" 1 "ON" 2 "Reserved" 3 "Signal invalid" ;
VAL_ 768 CVC_STAT_MaxAc 0 "OFF" 1 "ON" 2 "Reserved" 3 "Signal invalid" ;
VAL_ 768 CVC_STAT_ClimateOnOff 0 "OFF" 1 "ON" 2 "Reserved" 3 "Signal invalid" ;
VAL_ 768 CVC_STAT_FanSpeed 0 "OFF" 1 "Level 1" 2 "Level 2" 3 "Level 3" 4 "Level 4" 5 "Level 5" 6 "Level 6" 7 "Reserved" 8 "Reserved" 9 "Reserved" 10 "Reserved" 11 "Reserved" 12 "Reserved" 13 "Reserved" 14 "Reserved" 15 "Signal invalid" ;
VAL_ 768 CVC_STAT_RecircFlap 0 "Inside" 1 "Outside" 2 "Auto" 3 "Signal invalid" ;
VAL_ 768 CVC_STAT_AirDistributionMode 0 "OFF" 1 "Vent" 2 "Vent/Foot" 3 "Foot" 4 "Foot/Defrost" 5 "Defrost" 6 "Default" 7 "Signal invalid" ;
VAL_ 768 CVC_STAT_Defrost 0 "OFF" 1 "ON" 2 "Reserved" 3 "Signal invalid" ;
VAL_ 768 CVC_STAT_PTC_Heater 0 "OFF" 1 "Stage 1" 2 "Stage 2" 3 "Stage 3" 4 "Reserved" 5 "Reserved" 6 "Reserved" 7 "Signal invalid" ;
VAL_ 768 CVC_CoolSysWarnLvl 0 "No fault" 1 "Level 1" 2 "Level 2" 3 "Level 3" 4 "Level 4" 5 "Level 5" 6 "Level 6" 7 "Signal invalid" ;
VAL_ 773 CcuHtrOnOffSts 0 "HV PTC off / HV_PTC_OFF" 1 "HV PTC on / HV_PTC_ON" 2 "HV PTC degraded / HV_PTC_DEG" 3 "HV PTC stopped / HV_PTC_STOP" 4 "HV PTC shutdown / HV_PTC_SHUTDOWN" 5 "HV PTC shorted / HV_PTC_SHORTED" 6 "HV PTC reset not possible / HV_PTC_NO_RESET" 7 "SNA" ;
VAL_ 773 EcompOnOffSts 0 "Off" 1 "On" 2 "Reserved" 3 "Signal invalid" ;
VAL_ 775 OUT_Alert_TO_BCM 0 "Init" 1 "Warning level 1" 2 "Warning level 2" 3 "Warning level 3" 4 "Deactivate Warning" 5 "Invalid Value" ;
VAL_ 775 CPD_State_information 0 "Enable" 1 "Disable" 2 "Child Mode" 3 "Pet Mode" 4 "Reserved" 5 "Reserved" 6 "Reserved" 7 "Reserved" ;
VAL_ 775 OUT_Alert_TO_MHU 0 "Init" 1 "Default Warning" 2 "Warning on MHU" 3 "Warning Outside (Send SMS)" 4 "Deactivate Warning" ;
VAL_ 775 CPD_Occupancy_Status 0 "NOT_DETECTED" 1 "DETECTED" 2 "FAULT" 3 "UNKNOWN" 7 "Invalid Value" ;
VAL_ 775 CPD_Init_Warning_Delay 0 "No delay Time" 1 "1 minute" 2 "2 minute" 3 "3 minute" 4 "4 minute" 5 "5 minute" 6 "6 minute" 7 "7 minute" 8 "8 minute" 9 "9 minute" 10 "10 minute" ;
VAL_ 775 CPD_Temp_Warn_Delay_Sts 0 "UNKNOWN" 1 "Deactivation" 2 "Activation" 7 "Invalid Value" ;
VAL_ 775 CPD_OccupancyAlert 0 "UNKNOWN" 1 "Initial Warning" 2 "Escalation Warning" 7 "Invalid Value" ;
VAL_ 775 CPD_Warn_Cancel_Sts 0 "UNKNOWN" 1 "Deactivation" 2 "Activation" 3 "Invalid Value" ;
VAL_ 776 MHU_SET_CPD_InitWarnDelay 0 "No delay Time" 1 "1 minute" 2 "2 minute" 3 "3 minute" 4 "4 minute" 5 "5 minute" 6 "6 minute" 7 "7 minute" 8 "8 minute" 9 "9 minute" 10 "10 minute" ;
VAL_ 776 MHU_SET_CPD_TempWarnDelay 0 "UNKNOWN" 1 "Cancel Temporary Deactivation" 2 "Temporary Deactivation" ;
VAL_ 776 MHU_DKCU_CPD_Warn_Cancel 0 "UNKNOWN" 1 "Cancel Warning" 3 "Invalid Value" ;
VAL_ 777 CPD_Warn_Initial_Start 0 "UNKNOWN" 1 "Initial Warning Start" ;
VAL_ 777 CPD_Warn_Initial_End 0 "UNKNOWN" 1 "Initial Warning Complete" ;
VAL_ 777 CPD_Warn_Escalated_Start 0 "UNKNOWN" 1 "Escalation Warning Start" ;
VAL_ 777 CPD_Warn_Escalated_End 0 "UNKNOWN" 1 "Escalation Warning Complete" ;
VAL_ 777 CVC_DKCU_CPD_Warn_Cancel 0 "UNKNOWN" 1 "cancel initial warning" 2 "cancel escalation warning" ;
VAL_ 778 CVC_DKCU_PhoneLocationReq 0 "No request" 1 "Request phone location once" 2 "Start periodic phone location reporting" 3 "Stop periodic phone location reporting" ;
VAL_ 779 CVC_DKCU_Temp_Intervention_Fdbk 0 "UNKNOWN" 1 "Temperature Intervention Start" ;
VAL_ 779 CVC_DKCU_Remote_Phone_Interventi 0 "UNKNOWN" 1 "Phone Intervention Start" ;
VAL_ 862 CVC_VehLock_STS 0 "Locked" 1 "Unlocked" ;
VAL_ 862 CVC_VehChgAllow 0 "Forbid charging" 1 "Not allow, waiting" 2 "Allow charging" 3 "Invalid" ;
VAL_ 862 CVC_VehDischgAllow 0 "Forbid discharging" 1 "Shutdown" 2 "Allow discharging" 3 "Invalid" ;
VAL_ 862 Re_InitCharging_Req 0 "Forbid" 1 "Allow" 2 "Reserved" 3 "Invalid" ;
VAL_ 862 CVC_AntiTheft_Status 0 "Secured" 1 "Unsecured" 2 "Alarm" 3 "Partly secured" 4 "Reserved" 5 "Reserved" 6 "Reserved" 7 "Signal invalid" ;
VAL_ 862 CVC_GPSMonitorStatus 0 "OFF" 1 "ON" ;
VAL_ 862 CVC_RLS_Malfunction 0 "None" 1 "Alert" ;
VAL_ 862 CVC_RLS_Response_Error 0 "None" 1 "Error" ;
VAL_ 862 CVC_FrontWiperMotor_Status 0 "No error" 1 "Front wiper motor stalling" 2 "Reversed" 3 "Invalid" ;
VAL_ 862 CVC_RearWiperMotor_Status 0 "No error" 1 "Rear wiper motor stalling" 2 "Reversed" 3 "Invalid" ;
VAL_ 892 EVCC_ChgGun_Sts 0 "Gun not plugged-in" 1 "Gun plugged-in, locked" 2 "Gun plugged-in, released" 3 "Error, cannot lock" 4 "Error, cannot release" 5 "Bad connection" 6 "Reversed" 7 "Invalid" ;
VAL_ 892 EVCC_ChgFlap_Sts 0 "Locked" 1 "Unlocked" 2 "Faults" 3 "Invalid" ;
VAL_ 892 EVCC_ChgType 0 "No charging" 1 "Normal AC charging" 2 "PLC AC charging" 3 "DC charging" 4 "V2L" 5 "Reserved" 6 "Reserved" 7 "Invalid" ;
VAL_ 892 EVCC_VehChg_Sts 0 "Not charging" 1 "Charging in-progress" 2 "Waiting to start charging" 3 "Charging complete" 4 "Charge fault" 5 "Reserved" 6 "Reserved" 7 "Invalid" ;
VAL_ 892 EVCC_ChgAuthen_Sts 0 "Not authenticating" 1 "Authenticating" 2 "Authentication success" 3 "Authentication failed" 4 "Forbidden vehicle" 5 "Reserved" 6 "Reserved" 7 "Invalid" ;
VAL_ 892 EVCC_PaymentType 0 "Init" 1 "EIM" 2 "PnC" 3 "Reserved" 4 "Reserved" 5 "Reserved" 6 "Reserved" 7 "Invalid" ;
VAL_ 892 EVCC_VehChgCompError_Sts 0 "No error" 1 "Error level 1" 2 "Error level 2" 3 "Error level 3" 4 "Error level 4" 5 "Reserved" 6 "Reserved" 7 "Reserved" ;
VAL_ 892 EVCC_S3Button_Sts 0 "Not pressed" 1 "Pressed" 2 "Reserved" 3 "Invalid" ;
VAL_ 897 ACU_Seat_Occupancy_Passenger 0 "Seat_Not_Occupied" 1 "Seat Occupied" 2 "Not_Available" 3 "Failure" ;
VAL_ 897 ACU_Seat_Occupancy_2nd_Row_Dri 0 "Seat_Not_Occupied" 1 "Seat Occupied" 2 "Not_Available" 3 "Failure" ;
VAL_ 897 ACU_Seat_Occupancy_2nd_Row_Pas 0 "Seat_Not_Occupied" 1 "Seat Occupied" 2 "Not_Available" 3 "Failure" ;
VAL_ 897 ACU_Seat_Occupancy_2nd_Row_Mid 0 "Seat_Not_Occupied" 1 "Seat Occupied" 2 "Not_Available" 3 "Failure" ;
VAL_ 897 ACU_Seat_Belt_Status_Passenger 0 "Not_buckled" 1 "Buckled" 2 "Not_Available" 3 "Failure" ;
VAL_ 897 ACU_Seat_Belt_Status_Driver 0 "Not_buckled" 1 "Buckled" 2 "Not_Available" 3 "Failure" ;
VAL_ 897 ACU_Seat_Belt_Status_2nd_Row_Dri 0 "Not_buckled" 1 "Buckled" 2 "Not_Available" 3 "Failure" ;
VAL_ 897 ACU_Seat_Belt_Status_2nd_Row_Mid 0 "Not_buckled" 1 "Buckled" 2 "Not_Available" 3 "Failure" ;
VAL_ 897 ACU_Seat_Belt_Status_2nd_Row_Pas 0 "Not_buckled" 1 "Buckled" 2 "Not_Available" 3 "Failure" ;
VAL_ 897 ACU_Seat_Occupancy_Driver 0 "Seat_Not_Occupied" 1 "Seat Occupied" 2 "Not_Available" 3 "Failure" ;
VAL_ 905 DK_CVC_Immo_Status 0 "init" 1 "pass" 2 "failed" ;
VAL_ 905 CVC_IMMO_Sts 0 "init" 1 "pass" 2 "failed" ;
VAL_ 905 DKCU_AuthSessionStatus 0 "Idle" 1 "Active" 2 "Expired" 3 "Not Available" ;
VAL_ 925 CVC_ADAS_AHB_Sts 0 "OFF State" 1 "HighBeam Passive or Inactive" 2 "HighBeam Active" 3 "Fault" ;
VAL_ 925 CVC_AHB_Override 0 "Not used" 1 "Automatic High Beam request" 2 "AHB Inhibit by Driver" 3 "Invalid" ;
VAL_ 925 CVC_ADAS_AHB_RBPos_Sts 0 "Off or low beam" 1 "high beam" 2 "Reserved" 3 "Reserved" 4 "Reserved" 5 "Reserved" 6 "Reserved" 7 "Reserved" ;
VAL_ 925 CVC_ADAS_AHB_LBPos_Sts 0 "Off or low beam" 1 "high beam" 2 "Reserved" 3 "Reserved" 4 "Reserved" 5 "Reserved" 6 "Reserved" 7 "Reserved" ;
VAL_ 925 CVC_AHB_Icon_Sts 0 "Off" 1 "Gray ICON" 2 "Green ICON" 3 "White ICON" 4 "Yellow ICON" 5 "Red ICON" ;
VAL_ 1004 CVC_PanicEventTrigger 0 "No event" 1 "Panic triggered" ;
VAL_ 1004 CVC_PanicEventSource 0 "Unknown / Reserved" 1 "Mobile App (Digital Key)" 2 "Key Fob" 3 "Vehicle HMI / Interior Button (if any)" ;
VAL_ 1004 CVC_PanicEventStatus 0 "Idle" 1 "Active" 2 "Completed" 3 "Cancelled" ;
VAL_ 1011 CVC_PaaK_Enable 0 "Disable" 1 "Enable" 2 "Reserved" 3 "Signal Invalid" ;
VAL_ 1011 CVC_UserSettingApproachUnlock 0 "Disable" 1 "Enable" 2 "Reserved" 3 "Signal Invalid" ;
VAL_ 1011 CVC_UserSettingWalkawayLock 0 "Disable" 1 "Enable" 2 "Reserved" 3 "Signal Invalid" ;
VAL_ 1011 CVC_LockUnlockDriveCfg_PhoneKey 0 "Disable" 1 "Enable" 2 "Reserved" 3 "Signal Invalid" ;
VAL_ 1011 CVC_LockUnlockDriveCfg_NFC_Card 0 "Disable" 1 "Enable" 2 "Reserved" 3 "Signal Invalid" ;
VAL_ 1015 MFS_L_Lever_Control 0 "No action" 1 "Short Up" 2 "Long Up" 3 "Short Down" 4 "Long Down" 7 "Signal invalid" ;
VAL_ 1015 MFS_L_LeverButton_Control 0 "Unpressed" 1 "Short Press" 2 "Long Press" 7 "Signal invalid" ;
VAL_ 1015 MFS_L_Failure 0 "No Error" 1 "Error" ;
VAL_ 1015 MFS_L_UpControl 0 "Unpressed" 1 "Short Press" 2 "Long Press" 7 "Signal invalid" ;
VAL_ 1015 MFS_L_DownControl 0 "Unpressed" 1 "Short Press" 2 "Long Press" 7 "Signal invalid" ;
VAL_ 1015 MFS_L_LeftControl 0 "Unpressed" 1 "Short Press" 2 "Long Press" 7 "Signal invalid" ;
VAL_ 1015 MFS_L_RightControl 0 "Unpressed" 1 "Short Press" 2 "Long Press" 7 "Signal invalid" ;
VAL_ 1015 MFS_LIN_error 0 "No Error" 1 "Error" ;
VAL_ 1015 MFS_R_Lever_Control 0 "No action" 1 "Short Up" 2 "Long Up" 3 "Short Down" 4 "Long Down" 7 "Signal invalid" ;
VAL_ 1015 MFS_R_LeverButton_Control 0 "Unpressed" 1 "Short Press" 2 "Long Press" 7 "Signal invalid" ;
VAL_ 1015 MFS_R_Failure 0 "No Error" 1 "Error" ;
VAL_ 1015 MFS_R_UpControl 0 "Unpressed" 1 "Short Press" 2 "Long Press" 7 "Signal invalid" ;
VAL_ 1015 MFS_R_DownControl 0 "Unpressed" 1 "Short Press" 2 "Long Press" 7 "Signal invalid" ;
VAL_ 1015 MFS_R_LeftControl 0 "Unpressed" 1 "Short Press" 2 "Long Press" 7 "Signal invalid" ;
VAL_ 1015 MFS_R_RightControl 0 "Unpressed" 1 "Short Press" 2 "Long Press" 7 "Signal invalid" ;
VAL_ 1015 MFS_Scroll_Wheel_Left_Direction 0 "Neutral" 1 "Scroll Up" 2 "Scroll Down" 3 "Reserve" ;
VAL_ 1015 MFS_Scroll_Wheel_Right_Direction 0 "Neutral" 1 "Scroll Up" 2 "Scroll Down" 3 "Reserve" ;
VAL_ 1015 MFS_Scroll_Wheel_Left_Press 0 "No Request" 1 "Short Press" 2 "Long Press" 3 "Reserve" ;
VAL_ 1015 MFS_Scroll_Wheel_Right_Press 0 "No Request" 1 "Short Press" 2 "Long Press" 3 "Reserve" ;
VAL_ 1015 MFS_Scroll_Wheel_Left_Valid 0 "Valid" 1 "Invalid" ;
VAL_ 1015 MFS_Scroll_Wheel_Right_Valid 0 "Valid" 1 "Invalid" ;
VAL_ 1017 MHU_SET_PaaK_Enable 0 "Disable" 1 "Enable" ;
VAL_ 1017 MHU_SET_UserSettingApproachUnloc 0 "Disable" 1 "Enable" ;
VAL_ 1017 MHU_SET_UserSettingWalkawayLock 0 "Disable" 1 "Enable" ;
VAL_ 1017 MHU_SET_LockUnlockDriveCfg_Phone 0 "Disable" 1 "Enable" ;
VAL_ 1022 CVC_RearWiperSet 0 "No action" 1 "ON" 2 "OFF" ;
VAL_ 1022 CVC_SET_RearWiperServiceMod 0 "OFF" 1 "ON" 2 "Reserved" 3 "Signal Invalid" ;
VAL_ 1022 CVC_SET_FrontWiperServiceMod 0 "OFF" 1 "ON" 2 "Reserved" 3 "Signal Invalid" ;
VAL_ 1022 CVC_WiperServiceModeSet 0 "No action" 1 "ON" 2 "OFF" ;
VAL_ 1022 CVC_FrontWiperSpeedSet 0 "OFF" 1 "Low speed" 2 "Low speed continuous" 3 "High speed continuous" ;
VAL_ 1022 CVC_RLS_SensitivityLevelSet 1 "Step 1" 2 "Step 2" 3 "Step 3" 4 "Step 4" ;
VAL_ 1022 CVC_RS_L_WiperSpeed 0 "OFF" 1 "Low speed" 2 "Low speed continuous" 3 "High speed continuous" ;
VAL_ 1022 CVC_FR_RR_WashAndMist_Req 0 "No request" 1 "Front MIST" 2 "Front Wash and Wipe" 3 "Rear MIST" 4 "Rear Wash and Wipe" 5 "Reserved" 6 "Reserved" 7 "Invalid" ;
VAL_ 1022 CVC_RearWasherFuildSpayReq 0 "No action" 1 "ON" 2 "OFF" ;
VAL_ 1022 CVC_FrontWasherFuildSpayReq 0 "No action" 1 "ON" 2 "OFF" ;
VAL_ 1026 CVC_B_SET_DayTimeRunningLight 0 "OFF" 1 "ON" 2 "Reserved" 3 "Signal invalid" ;
VAL_ 1026 CVC_B_SET_RearFogLight 0 "OFF" 1 "ON" 2 "Reserved" 3 "Signal invalid" ;
VAL_ 1026 CVC_B_SET_FrontFogLight 0 "OFF" 1 "ON" 2 "Reserved" 3 "Signal invalid" ;
VAL_ 1026 CVC_B_SET_WelcomeDimmingHeadligh 0 "OFF" 1 "ON" 2 "Reserved" 3 "Signal invalid" ;
VAL_ 1026 CVC_B_SET_FootwellLightMode 0 "OFF" 1 "ON" 2 "AUTO" 3 "Signal invalid" ;
VAL_ 1026 CVC_B_SET_ExteriorLight 0 "OFF" 1 "Parking" 2 "ON" 3 "AUTO" 4 "Signal invalid" ;
VAL_ 1026 CVC_B_SET_TRWarningSignals 0 "Off BCM warning signals" 1 "On BCM warning signals" 2 "Reserved" 3 "Signal Invalid" ;
VAL_ 1026 CVC_B_SET_FrontDomeLamp 0 "OFF" 1 "ON" 2 "AUTO" 3 "Signal invalid" ;
VAL_ 1026 CVC_B_SET_HazardLight 0 "OFF" 1 "ON" 2 "Reserved" 3 "Signal Invalid" ;
VAL_ 1026 CVC_B_SET_FollowMeHome 0 "OFF" 1 "30 secs" 2 "60 secs" 3 "90 secs" 4 "120 secs" 5 "Signal invalid" ;
VAL_ 1026 CVC_B_SET_ADB_AHB 0 "OFF" 1 "ON" 2 "Reserved" 3 "Signal Invalid" ;
VAL_ 1026 CVC_B_SET_Welcome_Farewell_Anima 0 "Initial" 1 "Welcome1" 2 "Welcome2" 3 "Welcome3" 4 "Goodbye1" 5 "Goodbye2" 6 "Goodbye3" 7 "Invalid" ;
VAL_ 1026 CVC_B_SET_ChargingAnimation 0 "OFF" 1 "ON" 2 "Reserved" 3 "Signal invalid" ;
VAL_ 1026 CVC_B_SET_Auto_Leveling 0 "OFF" 1 "ON" 2 "Reserved" 3 "Signal Invalid" ;
VAL_ 1032 CVC_SET_MirrorAuto 0 "OFF" 1 "ON" 2 "Reserved" 3 "Signal invalid" ;
VAL_ 1032 CVC_SET_MirrorAutoUnfold 0 "Vehicle Unlock" 1 "Driver walk toward" 2 "OFF" 3 "Signal invalid" ;
VAL_ 1032 CVC_SET_WLC 0 "OFF" 1 "ON" 2 "Reserved" 3 "Signal invalid" ;
VAL_ 1032 CVC_SET_AutoRearWiper 0 "OFF" 1 "ON" 2 "Reserved" 3 "Signal invalid" ;
VAL_ 1032 CVC_SET_RearHeatedWindow 0 "No Request" 1 "ON" 2 "OFF" 3 "Signal invalid" ;
VAL_ 1032 CVC_TPMSReset 0 "Noreset" 1 "Reset" 2 "Reserved" 3 "Signal invalid" ;
VAL_ 1032 CVC_SET_MirrorDefaultSetting 0 "Not pressed" 1 "Pressed" 2 "Reserved" 3 "Signal invalid" ;
VAL_ 1032 CVC_SET_MirrorReverseLink 0 "OFF" 1 "Right Mirror" 2 "Left Mirror" 3 "Both Mirror" ;
VAL_ 1032 CVC_SET_AntiTheftMode 0 "OFF" 1 "Light Only" 2 "Horn Only" 3 "Light and Horn" ;
VAL_ 1032 CVC_SET_WLCReminder 0 "OFF" 1 "ON" 2 "Reserved" 3 "Signal invalid" ;
VAL_ 1032 CVC_SET_ClimateKeepOn 0 "OFF" 1 "PET" 2 "CAMP" 3 "REMOTE CONTROL" ;
VAL_ 1032 CVC_SET_WLC2 0 "OFF" 1 "ON" 2 "Reserved" 3 "Signal invalid" ;
VAL_ 1032 CVC_SET_WLC2Reminder 0 "OFF" 1 "ON" 2 "Reserved" 3 "Signal invalid" ;
VAL_ 1032 CVC_SET_WLC_Phoneforgetalert 0 "OFF" 1 "ON" 2 "Reserved" 3 "Signal invalid" ;
VAL_ 1032 CVC_SteeringWheel_Adjust_Req 0 "No request" 1 "Up" 2 "Down" 3 "Front" 4 "Rear" 5 "Reserved" 7 "Signal Invalid" ;
VAL_ 1033 TBOX_IntrusionAlertStatus 0 "OFF" 1 "ON" 2 "Stop Alarm" 3 "Signal invalid" ;
VAL_ 1036 CVC_B_DrvSeat_Control_Status 0 "Idle" 1 "Request seat moving" 2 "Reserved" 3 "Invalid value" ;
VAL_ 1050 MHU_SteeringWheel_EasyEntry 0 "ON" 1 "OFF" 2 "reserved" 3 "Invalid" ;
VAL_ 1050 MHU_SteeringWheel_Heater 0 "ON" 1 "OFF" 2 "reserved" 3 "Invalid" ;
VAL_ 1050 MHU_SteerElecAdj_Req 0 "No Request" 1 "Save" 2 "Restore memory location" 3 "Moving" ;
VAL_ 1066 CVC_DriverSeatControl_Req 0 "Idle" 1 "Request seat moving" 2 "Reserved" 3 "Invalid Value" ;
VAL_ 1066 CVC_FRSeatMassageMode_Set 0 "OFF" 1 "Wave mode" 2 "Catpad mode" 3 "Cross mode" 4 "Relieve mode" 5 "Jump mode" 6 "Reserved" 7 "Invalid" ;
VAL_ 1066 CVC_FLSeatMassageMode_Set 0 "OFF" 1 "Wave mode" 2 "Catpad mode" 3 "Cross mode" 4 "Relieve mode" 5 "Jump mode" 6 "Reserved" 7 "Invalid" ;
VAL_ 1066 CVC_FLSeatMassageLevel_Set 0 "OFF" 1 "Initial Value" 2 "Level 1 (Weak)" 3 "Level 2 (General)" 4 "Level 3 (Strong)" 5 "Reserved" 6 "Reserved" 7 "Invalid" ;
VAL_ 1066 CVC_RRSeatMassageMode_Set 0 "OFF" 1 "Wave mode" 2 "Catpad mode" 3 "Cross mode" 4 "Relieve mode" 5 "Jump mode" 6 "Reserved" 7 "Invalid" ;
VAL_ 1066 CVC_RLSeatMassageMode_Set 0 "OFF" 1 "Wave mode" 2 "Catpad mode" 3 "Cross mode" 4 "Relieve mode" 5 "Jump mode" 6 "Reserved" 7 "Invalid" ;
VAL_ 1066 CVC_RRSeatMassageLevel_Set 0 "OFF" 1 "Initial Value" 2 "Level 1 (Weak)" 3 "Level 2 (General)" 4 "Level 3 (Strong)" 5 "Reserved" 6 "Reserved" 7 "Invalid" ;
VAL_ 1066 CVC_RLSeatMassageLevel_Set 0 "OFF" 1 "Initial Value" 2 "Level 1 (Weak)" 3 "Level 2 (General)" 4 "Level 3 (Strong)" 5 "Reserved" 6 "Reserved" 7 "Invalid" ;
VAL_ 1066 CVC_FRSeatMassageLevel_Set 0 "OFF" 1 "Initial Value" 2 "Level 1 (Weak)" 3 "Level 2 (General)" 4 "Level 3 (Strong)" 5 "Reserved" 6 "Reserved" 7 "Invalid" ;
VAL_ 1074 CVC_B_FOTA_State 0 "INIT" 1 "NORMAL" 2 "FOTA FLASHING" 3 "FOTA-SUSPENDED" 4 "FAIL-SAFE-ERROR" 5 "SHUTDOWN" 6 "REMOTE DIAGNOSTICS" 7 "Invalid" ;
VAL_ 1082 CVC_BrakeRegenMode 0 "OFF" 1 "LOW" 2 "MID" 3 "HIGH" ;
VAL_ 1082 CVC_CreepEnable_stt 0 "Enable" 1 "Disable" ;
VAL_ 1082 CVC_Regen_available 0 "Not available" 1 "Available" 2 "Regen limit" 3 "Regen faut" ;
VAL_ 1082 CVC_Hvbatt_charging_stt 0 "Not charging" 1 "Charging" ;
VAL_ 1099 CVC_RLSeatHeating_Set 0 "OFF" 1 "Level 1" 2 "Level 2" 3 "Level 3" 4 "Reserved" 5 "Reserved" 6 "Reserved" 7 "Invalid" ;
VAL_ 1099 CVC_FRSeatHeating_Set 0 "OFF" 1 "Level 1" 2 "Level 2" 3 "Level 3" 4 "Reserved" 5 "Reserved" 6 "Reserved" 7 "Invalid" ;
VAL_ 1099 CVC_FLSeatHeating_Set 0 "OFF" 1 "Level 1" 2 "Level 2" 3 "Level 3" 4 "Reserved" 5 "Reserved" 6 "Reserved" 7 "Invalid" ;
VAL_ 1099 CVC_FRSeatVentilation_Set 0 "OFF" 1 "Level 1" 2 "Level 2" 3 "Level 3" 4 "Reserved" 5 "Reserved" 6 "Reserved" 7 "Invalid" ;
VAL_ 1099 CVC_FLSeatVentilation_Set 0 "OFF" 1 "Level 1" 2 "Level 2" 3 "Level 3" 4 "Reserved" 5 "Reserved" 6 "Reserved" 7 "Invalid" ;
VAL_ 1099 CVC_RRSeatHeating_Set 0 "OFF" 1 "Level 1" 2 "Level 2" 3 "Level 3" 4 "Reserved" 5 "Reserved" 6 "Reserved" 7 "Invalid" ;
VAL_ 1099 CVC_RRSeatVentilation_Set 0 "OFF" 1 "Level 1" 2 "Level 2" 3 "Level 3" 4 "Reserved" 5 "Reserved" 6 "Reserved" 7 "Invalid" ;
VAL_ 1099 CVC_RLSeatVentilation_Set 0 "OFF" 1 "Level 1" 2 "Level 2" 3 "Level 3" 4 "Reserved" 5 "Reserved" 6 "Reserved" 7 "Invalid" ;
VAL_ 1099 CVC_UserProfile 0 "No user detected" 1 "User 1" 2 "User 2" 3 "Guest 3" 4 "Reserved" 5 "Reserved" 6 "Reserved" 7 "Invalid" ;
VAL_ 1112 CVC_AmbientLightColorZoneReq 0 "Init" 1 "ALM zone Instrument Panel" 2 "ALM zone Front Left" 3 "ALM zone Rear Left" 4 "ALM zone Front Right" 5 "ALM zone Rear Right" 6 "Reserved" 7 "Reserved" 8 "Reserved" 9 "Reserved" 10 "Reserved" 11 "Reserved" 12 "Reserved" 13 "Reserved" 14 "Reserved" 15 "Invalid" ;
VAL_ 1113 CVC_AmbLightIntensityZoneReq 0 "Init" 1 "ALM zone Instrument Panel" 2 "ALM zone Front Left" 3 "ALM zone Rear Left" 4 "ALM zone Front Right" 5 "ALM zone Rear Right" 6 "Reserved" 7 "Reserved" 8 "Reserved" 9 "Reserved" 10 "Reserved" 11 "Reserved" 12 "Reserved" 13 "Reserved" 14 "Reserved" 15 "Invalid" ;
VAL_ 1113 CVC_AmbLightIntensityTypeReq 0 "None" 1 "Blinking" 2 "Wave" 3 "Morse" 4 "Fading" ;
VAL_ 1114 CVC_Z3_AmbLightZoneFLReq 0 "OFF" 1 "ON" 2 "Reserved" 3 "Signal invalid" ;
VAL_ 1114 CVC_Z1_AmbLightZoneIPDrivReq 0 "OFF" 1 "ON" 2 "Reserved" 3 "Signal invalid" ;
VAL_ 1114 CVC_Z2_AmbLightZoneFRReq 0 "OFF" 1 "ON" 2 "Reserved" 3 "Signal invalid" ;
VAL_ 1114 CVC_Z5_AmbLightZoneRLReq 0 "OFF" 1 "ON" 2 "Reserved" 3 "Signal invalid" ;
VAL_ 1114 CVC_Z4_AmbLightZoneRRReq 0 "OFF" 1 "ON" 2 "Reserved" 3 "Signal invalid" ;
VAL_ 1114 CVC_Z3B_AmbLightZoneFLReq 0 "OFF" 1 "ON" 2 "Reserved" 3 "Signal invalid" ;
VAL_ 1114 CVC_Z2B_AmbLightZoneFRReq 0 "OFF" 1 "ON" 2 "Reserved" 3 "Signal invalid" ;
VAL_ 1114 CVC_Z6_AmbLightZoneIPPassReq 0 "OFF" 1 "ON" 2 "Reserved" 3 "Signal invalid" ;
VAL_ 1114 CVC_Z6B_AmbLightZoneIPPassReq 0 "OFF" 1 "ON" 2 "Reserved" 3 "Signal invalid" ;
VAL_ 1114 CVC_Z7_AmbLightZoneConsLReq 0 "OFF" 1 "ON" 2 "Reserved" 3 "Signal invalid" ;
VAL_ 1114 CVC_Z7B_AmbLightZoneConsLReq 0 "OFF" 1 "ON" 2 "Reserved" 3 "Signal invalid" ;
VAL_ 1114 CVC_Z8_AmbLightZoneConsRReq 0 "OFF" 1 "ON" 2 "Reserved" 3 "Signal invalid" ;
VAL_ 1114 CVC_Z8B_AmbLightZoneConsRReq 0 "OFF" 1 "ON" 2 "Reserved" 3 "Signal invalid" ;
VAL_ 1114 CVC_Z9_AmbLightZoneConsRLReq 0 "OFF" 1 "ON" 2 "Reserved" 3 "Signal invalid" ;
VAL_ 1114 CVC_Z10_AmbLightZoneConsRRReq 0 "OFF" 1 "ON" 2 "Reserved" 3 "Signal invalid" ;
VAL_ 1114 CVC_Z5B_AmbLightZoneRLReq 0 "OFF" 1 "ON" 2 "Reserved" 3 "Signal invalid" ;
VAL_ 1114 CVC_Z4B_AmbLightZoneRRReq 0 "OFF" 1 "ON" 2 "Reserved" 3 "Signal invalid" ;
VAL_ 1117 FCAM_HeaterActivation_Req 0 "false" 1 "true" ;
VAL_ 1171 BMS_PackTempSts 0 "No warning" 1 "Over Temperature Warning" 2 "Under Temperature Warning" ;
VAL_ 1171 BMS_ThermalRunaway 0 "No Warning" 1 "Warning" ;
VAL_ 1171 BMS_BatteryReplacement 0 "No Warning" 1 "Warning" ;
VAL_ 1171 BMS_Warning_PowerDegrade 0 "Normal" 1 "Pack Power Degrade" ;
VAL_ 1171 BMS_Warning_DeltaSoC 0 "Normal" 1 "Delta SOC high" ;
VAL_ 1171 BMS_Warning_HVILSts 0 "Normal" 1 "HVIL error detected" ;
VAL_ 1171 BMS_Warning_Isolation 0 "Normal" 1 "Isolation reached level 3" ;
VAL_ 1171 BMS_Warning_CoolantLeakage 0 "Normal" 1 "Coolant leakage detected" ;
VAL_ 1171 BMS_MalfunctionSts 0 "No Warning" 1 "Warning" ;
VAL_ 1171 BMS_LowBattery 0 "No warning" 1 "Low level" 2 "Extremely low level" ;
VAL_ 1171 BMS_Warning_DeltaTemperature 0 "Normal" 1 "Level 1 warning" 2 "Level 2 extreme" ;
VAL_ 1171 BMS_Warning_BDUTemperatureSts 0 "Normal" 1 "BDU temp warning" 2 "BDU hot" 3 "BDU extreme hot" ;
VAL_ 1171 BMS_Warning_Contactor_Aging 0 "No Warning" 1 "Warning" ;
VAL_ 1257 CVC_RHMirrorAdjustmentSet 0 "OFF" 1 "ON" 2 "Reserved" 3 "Invalid" ;
VAL_ 1257 CVC_LHMirrorAdjustmentSet 0 "OFF" 1 "ON" 2 "Reserved" 3 "Invalid" ;
VAL_ 1257 CVC_SET_MirrorFold_Right 0 "No request" 1 "Fold" 2 "Unfold" 3 "Invalid" ;
VAL_ 1257 CVC_SET_MirrorFold_Left 0 "No request" 1 "Fold" 2 "Unfold" 3 "Invalid" ;
VAL_ 1257 RHMirror_Adjustment_Req 0 "No request" 1 "Up" 2 "Down" 3 "Left" 4 "Right" 5 "Invalid" ;
VAL_ 1257 LHMirror_Adjustment_Req 0 "No request" 1 "Up" 2 "Down" 3 "Left" 4 "Right" 5 "Invalid" ;
VAL_ 1879 CVC_TMSMode 0 "Reserved" 1 "C1" 2 "C2" 3 "C3" 4 "C4" 5 "C5" 6 "C6" 7 "C7" 8 "C8" 9 "C9" 10 "MIX" 11 "H1" 12 "H2" 13 "H3" 14 "H4" 15 "H5" 16 "H6" 17 "H7" 255 "Invalid" ;
VAL_ 1879 CVC_HVCHOffCode 0 "HVCH is normal" 1 "Water pump 1 fails cause the HVCH is turned off" 2 "Water pump 2 fails cause the HVCH is turned off" 4 "W5WV1 initialization is not complete and the compressor is turned off" 8 "W5WV2 initialization is not complete and the compressor is turned off" 16 "The HVCH is confirmed to be faulty, and the HVCH to turned off" 32 "The system mode need the HVCH to be turned of" 64 "The HVCH outlet water temperature is too high cause HVCH turn off" 128 "The HV battery inlet and outlet water temperature have faults cause HVCH turn off (TBD)" 256 "CVC battery voltage is too low cause the HVCH to turned off" 512 "CVC battery voltage is too high cause the HVCH to turned off" 1024 "KL15 is OFF, HVCH off" 2048 "HVCH detection communication failure, HVCH shut down" 4096 "CVC detected a communication fault with the HVCH and shut it down" ;
VAL_ 1879 CVC_AirPTCOffCode 0 "AirPTC is normal" 1 "Water pump 1 fails cause the AirPTC is turned off" 2 "Water pump 2 fails cause the AirPTC is turned off" 4 "W5WV1 initialization is not complete and the compressor is turned off" 8 "W5WV2 initialization is not complete and the compressor is turned off" 16 "The AirPTC is confirmed to be faulty, and the AirPTC to turned off" 32 "The system mode need the AirPTC to be turned off" 64 "The AirPTC inlet water temperature is too high cause AirPTC turn off" 128 "The blower fail or stop, the airPTC shuts down" 256 "The AirPTC inlet water temperature has fault cause AirPTC turn off" 512 "CVC battery voltage is too low cause the AirPTC to turned off" 1024 "CVC battery voltage is too high cause the AirPTC to turned off" 2048 "KL15 is OFF, AirPTC off" 4096 "AirPTC detection communication failure, AirPTC shut down" 8192 "CVC detected a communication fault with the AirPTC and shut it down" ;
VAL_ 1879 CVC_CompOffCode 0 "The compressor is normal" 1 "Compressor suction pressure protection to turned off" 2 "Compressor discharge pressure protection to turned off" 4 "Compressor suction temperature protection to turned off" 8 "Compressor discharge temperature protection to turned off" 16 "Compressor evaporator temperature protection to turned off" 32 "EXV1 initialization is not complete and the compressor is turned of" 64 "EXV2 initialization is not complete and the compressor is turned of" 128 "W5WV1 initialization is not complete and the compressor is turned of" 256 "W5WV2 initialization is not complete and the compressor is turned of" 512 "The cooling fan is faulty and the compressor to turned of" 1024 "The compressor is confirmed to be faulty, and the compressor to turned of" 2048 "The system mode need the compressor to be turned off" 4096 "Inlet water temperature is too low cause compressor to turn off" 8192 "Cabin has no cooling and heating demand, and the compressor is turned off" 16384 "Water pump 1 fails cause the compressor to turned off" 32768 "Water pump 2 fails cause the compressor to turned off" 65536 "The blower fails or stop, the compressor shuts down" 131072 "CVC battery voltage is too low cause the compressor to turned off" 262144 "CVC battery voltage is too high cause the compressor to turned off" 524288 "KL15 is OFF, compressor off" 1048576 "Compressor discharge PT sensor fault cause compressor to turn down" 2097152 "Compressor suction PT sensor failure cause compressor to turn down" 4194304 "ACC outlet PT sensor fault, compressor shutdown" 8388608 "Compressor detection communication failure, compressor shut down" 16777216 "CVC detected a communication fault with the compressor and shut it down" 33554432 "EXV1 turned too small, compressor protection turned off" 67108864 "EXV2 turned too small, compressor protection turned off" ;
VAL_ 1889 EAC_status 0 "Compressor off" 1 "Compressor on" 2 "Compressor limit" 3 "Pre-Heating" 4 "Reserved" 5 "Reserved" 6 "Init" 7 "Failure of EAC" ;
VAL_ 1889 EAC_drive_request 0 "Compressor OFF" 1 "Compressor ON" 2 "Not define" 3 "SNA" ;
VAL_ 1889 MWV1_OperationMode 0 "No Request" 1 "Mode 1" 2 "Mode 2" 3 "Mode 3" 4 "Mode 4" 5 "Mode 5" 6 "Mode 6" 7 "Mode 7" 8 "Mode 8" 9 "Filling mode" ;
VAL_ 1889 MWV2_OperationMode 0 "No Request" 1 "Mode 1" 2 "Mode 2" 3 "Mode 3" 4 "Mode 4" 5 "Mode 5" 6 "Mode 6" 7 "Mode 7" 8 "Mode 8" 9 "Filling mode" ;
VAL_ 168 BCMRE_Climate_RearAirRecirculati 0 "Normal" 1 "Fault" ;
VAL_ 168 BCMRE_Climate_RearAirDistFlapSts 0 "Normal" 1 "Fault" ;
VAL_ 168 BCMRE_Climate_RearTempFlapSts 0 "Normal" 1 "Fault" ;
VAL_ 168 BCMRE_Climate_FrontPassAirMode_S 0 "Normal" 1 "Fault" ;
VAL_ 168 BCMRE_Climate_FrontByPassAi_0000 0 "Normal" 1 "Fault" ;
VAL_ 168 BCMRE_Climate_RearFootAirMode_St 0 "Normal" 1 "Fault" ;
VAL_ 168 BCMRE_Climate_RLTemp_Sts 0 "Normal" 1 "Fault" ;
VAL_ 168 BCMRE_Climate_RRTemp_Sts 0 "Normal" 1 "Fault" ;
VAL_ 168 BCMRE_Climate_RearBlowerRelay_St 0 "OFF" 1 "ON" 2 "Fault" 3 "Invalid" ;
VAL_ 168 BCMRE_Climate_AirDistFlapRHSts 0 "Normal" 1 "Fault" ;
VAL_ 168 BCMRE_Climate_BypassFlapSts 0 "Normal" 1 "Fault" ;
VAL_ 168 BCMRE_Climate_AirDistRearFlapSts 0 "Normal" 1 "Fault" ;
VAL_ 168 BCMRE_Climate_RearDuctFlapSts 0 "Normal" 1 "Fault" ;
VAL_ 172 TailgateAjarStatus 0 "Closed" 1 "Opened" 2 "Faults" 3 "Invalid" ;
VAL_ 172 TailgateLockStatus 0 "Lock" 1 "Unlocked" 2 "Faults" 3 "Invalid" ;
VAL_ 172 Fuel_Port_Lock_Status 0 "Lock" 1 "Unlocked" 2 "Reserved" 3 "Invalid" ;
VAL_ 172 Fuel_Port_Ajar_Status 0 "Closed" 1 "Opened" 2 "Reserved" 3 "Invalid" ;
VAL_ 179 Tailgate_Malfunction 0 "Not Error" 1 "Error" ;
VAL_ 179 TailgateIntButton_Request 0 "No command" 1 "Short press" 2 "Long press" ;
VAL_ 179 AntiPinch_Operation 0 "Not Active" 1 "Active" ;
VAL_ 188 DoorPassiveEntry_Request 0 "Not pressed" 1 "Pressed" 2 "Long Pressed" 3 "Invalid" ;
VAL_ 188 TailgatePassiveEntry_Request 0 "Not pressed" 1 "Pressed" 2 "Long Pressed" 3 "Invalid" ;
